VERSION ""

NS_ :

BS_:

BU_: L_3HKBD L_FHPTC L_2HKBD L_ATCU L_PCM L_EVNT L_HKBD L_RHPTC

BO_ 68 L_HKBD_04: 8 L_HKBD
 SG_ HKBD_Fr_DrTempDnSw : 0|1@1+ (1,0) [0|0] ""  L_ATCU
 SG_ HKBD_Fr_DrTempUpSw : 1|1@1+ (1,0) [0|0] ""  L_ATCU
 SG_ HKBD_Fr_PsBlwDnSw : 11|1@1+ (1,0) [0|0] ""  L_ATCU
 SG_ HKBD_Fr_PsBlwDnOffSw : 12|1@1+ (1,0) [0|0] ""  L_ATCU
 SG_ HKBD_Fr_PsBlwUpSw : 13|1@1+ (1,0) [0|0] ""  L_ATCU
 SG_ HKBD_Fr_PsBlwSet : 14|4@1+ (1,0) [0|0] ""  L_ATCU
 SG_ HKBD_Fr_RrDrTempDnSw : 18|1@1+ (1,0) [0|0] ""  L_ATCU
 SG_ HKBD_Fr_RrDrTempUpSw : 19|1@1+ (1,0) [0|0] ""  L_ATCU
 SG_ HKBD_Fr_PsTempDnSw : 2|1@1+ (1,0) [0|0] ""  L_ATCU
 SG_ HKBD_Fr_RrDrBlwDnSw : 20|1@1+ (1,0) [0|0] ""  L_ATCU
 SG_ HKBD_Fr_RrDrBlwDnOffSw : 21|1@1+ (1,0) [0|0] ""  L_ATCU
 SG_ HKBD_Fr_RrDrBlwUpSw : 22|1@1+ (1,0) [0|0] ""  L_ATCU
 SG_ HKBD_Fr_RrDrBlwSet : 23|4@1+ (1,0) [0|0] ""  L_ATCU
 SG_ HKBD_Fr_RrDrModDnSw : 27|1@1+ (1,0) [0|0] ""  L_ATCU
 SG_ HKBD_Fr_RrDrModUpSw : 28|1@1+ (1,0) [0|0] ""  L_ATCU
 SG_ HKBD_Fr_RrDrModVntSw : 29|1@1+ (1,0) [0|0] ""  L_ATCU
 SG_ HKBD_Fr_PsTempUpSw : 3|1@1+ (1,0) [0|0] ""  L_ATCU
 SG_ HKBD_Fr_RrDrModFlrSw : 30|1@1+ (1,0) [0|0] ""  L_ATCU
 SG_ HKBD_Fr_RrDrModBiLvlSw : 31|1@1+ (1,0) [0|0] ""  L_ATCU
 SG_ HKBD_Fr_RrDrAutoSw : 32|1@1+ (1,0) [0|0] ""  L_ATCU
 SG_ HKBD_Fr_RrDrMultiAutoSw : 33|3@1+ (1,0) [0|0] ""  L_ATCU
 SG_ HKBD_Fr_RrOffSw : 36|1@1+ (1,0) [0|0] ""  L_ATCU
 SG_ HKBD_Fr_RrSyncSw : 37|1@1+ (1,0) [0|0] ""  L_ATCU
 SG_ HKBD_Fr_RLStHeatSw : 38|1@1+ (1,0) [0|0] ""  L_ATCU
 SG_ HKBD_Fr_RLStVentSw : 39|1@1+ (1,0) [0|0] ""  L_ATCU
 SG_ HKBD_Fr_DrBlwDnSw : 4|1@1+ (1,0) [0|0] ""  L_ATCU
 SG_ HKBD_Fr_RRStHeatSw : 40|1@1+ (1,0) [0|0] ""  L_ATCU
 SG_ HKBD_Fr_RRStVentSw : 41|1@1+ (1,0) [0|0] ""  L_ATCU
 SG_ HKBD_Fr_RLStTumblrSw : 42|2@1+ (1,0) [0|0] ""  L_ATCU
 SG_ HKBD_Fr_RRStTumblrSw : 44|2@1+ (1,0) [0|0] ""  L_ATCU
 SG_ HKBD_Fr_RrPsModDnSw : 46|1@1+ (1,0) [0|0] ""  L_ATCU
 SG_ HKBD_Fr_RrPsModUpSw : 47|1@1+ (1,0) [0|0] ""  L_ATCU
 SG_ HKBD_Fr_RrPsModVntSw : 48|1@1+ (1,0) [0|0] ""  L_ATCU
 SG_ HKBD_Fr_RrPsModFlrSw : 49|1@1+ (1,0) [0|0] ""  L_ATCU
 SG_ HKBD_Fr_DrBlwDnOffSw : 5|1@1+ (1,0) [0|0] ""  L_ATCU
 SG_ HKBD_Fr_RrLockSw : 50|1@1+ (1,0) [0|0] ""  L_ATCU
 SG_ HKBD_Fr_RrPsModBiLvlSw : 51|1@1+ (1,0) [0|0] ""  L_ATCU
 SG_ HKBD_Fr_RrDrModSw : 52|1@1+ (1,0) [0|0] ""  L_ATCU
 SG_ HKBD_Fr_RrPsModSw : 53|1@1+ (1,0) [0|0] ""  L_ATCU
 SG_ HKBD_Fr_RrPsBlwSet : 54|4@1+ (1,0) [0|0] ""  L_ATCU
 SG_ HKBD_Fr_RrPsBlwUpSw : 58|1@1+ (1,0) [0|0] ""  L_ATCU
 SG_ HKBD_Fr_RrPsBlwDnSw : 59|1@1+ (1,0) [0|0] ""  L_ATCU
 SG_ HKBD_Fr_DrBlwUpSw : 6|1@1+ (1,0) [0|0] ""  L_ATCU
 SG_ HKBD_Fr_RrPsBlwDnOffSw : 60|1@1+ (1,0) [0|0] ""  L_ATCU
 SG_ HKBD_Fr_RrPsTempDnSw : 61|1@1+ (1,0) [0|0] ""  L_ATCU
 SG_ HKBD_Fr_RrPsTempUpSw : 62|1@1+ (1,0) [0|0] ""  L_ATCU
 SG_ HKBD_Fr_DrBlwSet : 7|4@1+ (1,0) [0|0] ""  L_ATCU

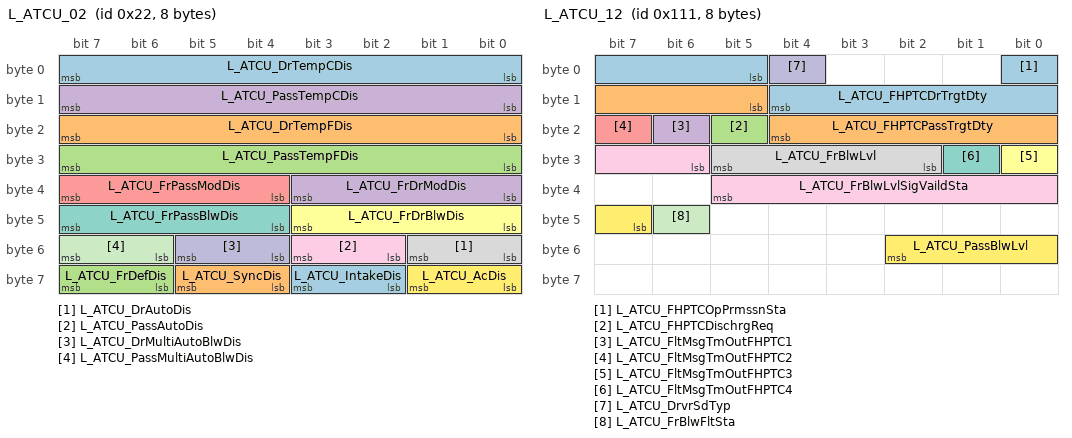
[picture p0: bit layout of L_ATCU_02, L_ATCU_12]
BO_ 34 L_ATCU_02: 8 L_ATCU
 SG_ L_ATCU_DrTempCDis : 0|8@1+ (0.5,14) [0|0] "¡É"  L_HKBD
 SG_ L_ATCU_DrTempFDis : 16|8@1+ (1,56) [0|0] "¢µ"  L_HKBD
 SG_ L_ATCU_PassTempFDis : 24|8@1+ (1,56) [0|0] "¢µ"  L_HKBD
 SG_ L_ATCU_FrDrModDis : 32|4@1+ (1,0) [0|0] ""  L_EVNT,L_HKBD
 SG_ L_ATCU_FrPassModDis : 36|4@1+ (1,0) [0|0] ""  L_EVNT,L_HKBD
 SG_ L_ATCU_FrDrBlwDis : 40|4@1+ (1,0) [0|0] ""  L_HKBD
 SG_ L_ATCU_FrPassBlwDis : 44|4@1+ (1,0) [0|0] ""  L_HKBD
 SG_ L_ATCU_DrAutoDis : 48|2@1+ (1,0) [0|0] ""  L_HKBD
 SG_ L_ATCU_PassAutoDis : 50|2@1+ (1,0) [0|0] ""  L_HKBD
 SG_ L_ATCU_DrMultiAutoBlwDis : 52|2@1+ (1,0) [0|0] ""  L_HKBD
 SG_ L_ATCU_PassMultiAutoBlwDis : 54|2@1+ (1,0) [0|0] ""  L_HKBD
 SG_ L_ATCU_AcDis : 56|2@1+ (1,0) [0|0] ""  L_HKBD
 SG_ L_ATCU_IntakeDis : 58|2@1+ (1,0) [0|0] ""  L_HKBD
 SG_ L_ATCU_SyncDis : 60|2@1+ (1,0) [0|0] ""  L_HKBD
 SG_ L_ATCU_FrDefDis : 62|2@1+ (1,0) [0|0] ""  L_HKBD
 SG_ L_ATCU_PassTempCDis : 8|8@1+ (0.5,14) [0|0] "¡É"  L_HKBD

BO_ 69 L_HKBD_05: 8 L_HKBD
 SG_ HKBD_Fr_3rdRrTempDnSw : 0|1@1+ (1,0) [0|0] ""  L_ATCU
 SG_ HKBD_Fr_3rdRrTempUpSw : 1|1@1+ (1,0) [0|0] ""  L_ATCU
 SG_ HKBD_Fr_3rdRrModUpSw : 10|1@1+ (1,0) [0|0] ""  L_ATCU
 SG_ HKBD_Fr_3rdRrModVntSw : 11|1@1+ (1,0) [0|0] ""  L_ATCU
 SG_ HKBD_Fr_3rdRrModFlrSw : 12|1@1+ (1,0) [0|0] ""  L_ATCU
 SG_ HKBD_Fr_3rdRrAutoSw : 13|1@1+ (1,0) [0|0] ""  L_ATCU
 SG_ HKBD_Fr_3rdRrMultiAutoSw : 14|3@1+ (1,0) [0|0] ""  L_ATCU
 SG_ HKBD_Fr_3rdRrOffSw : 17|1@1+ (1,0) [0|0] ""  L_ATCU
 SG_ HKBD_Fr_3rdRrSyncSw : 18|1@1+ (1,0) [0|0] ""  L_ATCU
 SG_ HKBD_Fr_3rdRrLockSw : 19|1@1+ (1,0) [0|0] ""  L_ATCU
 SG_ HKBD_Fr_3rdRrBlwDnSw : 2|1@1+ (1,0) [0|0] ""  L_ATCU
 SG_ HKBD_Fr_3rdRrModBiLvlSw : 20|1@1+ (1,0) [0|0] ""  L_ATCU
 SG_ HKBD_FrRrTglSet : 21|2@1+ (1,0) [0|0] ""  L_ATCU
 SG_ HKBD_Fr_RrScrnSet : 23|2@1+ (1,0) [0|0] ""  L_ATCU
 SG_ HKBD_Fr_OnOffSet : 25|2@1+ (1,0) [0|0] ""  L_ATCU
 SG_ HKBD_Fr_RrOnOffSet : 27|2@1+ (1,0) [0|0] ""  L_ATCU
 SG_ HKBD_Fr_3rdRrOnOffSet : 29|2@1+ (1,0) [0|0] ""  L_ATCU
 SG_ HKBD_Fr_3rdRrBlwDnOffSw : 3|1@1+ (1,0) [0|0] ""  L_ATCU
 SG_ HKBD_Fr_RrPsAutoSw : 31|1@1+ (1,0) [0|0] ""  L_ATCU
 SG_ HKBD_Fr_RrPsMultiAutoSw : 32|3@1+ (1,0) [0|0] ""  L_ATCU
 SG_ HKBD_Fr_3rdRrModSw : 35|1@1+ (1,0) [0|0] ""  L_ATCU
 SG_ HKBD_Fr_3rdRrBlwUpSw : 4|1@1+ (1,0) [0|0] ""  L_ATCU
 SG_ HKBD_Fr_3rdRrBlwSet : 5|4@1+ (1,0) [0|0] ""  L_ATCU
 SG_ HKBD_Fr_3rdRrModDnSw : 9|1@1+ (1,0) [0|0] ""  L_ATCU

BO_ 35 L_ATCU_03: 8 L_ATCU
 SG_ L_ATCU_DrOnlyDis : 0|2@1+ (1,0) [0|0] ""  L_HKBD
 SG_ L_ATCU_SmrtVntDis : 11|2@1+ (1,0) [0|0] ""  L_HKBD
 SG_ L_ATCU_FrWndShldHtInd : 13|2@1+ (1,0) [0|0] ""  L_HKBD
 SG_ L_ATCU_IncarMtrOnReq : 15|1@1+ (1,0) [0|0] ""  L_HKBD
 SG_ L_ATCU_LanguageInfo : 16|8@1+ (1,0) [0|0] ""  L_HKBD
 SG_ L_ATCU_RrDefInd : 2|1@1+ (1,0) [0|0] ""  L_HKBD
 SG_ L_ATCU_AfterBlowDisplay : 24|2@1+ (1,0) [0|0] ""  L_HKBD
 SG_ L_ATCU_SchdldVentDisplay : 26|2@1+ (1,0) [0|0] ""  L_HKBD
 SG_ L_ATCU_FLStHeatSwHInd : 28|1@1+ (1,0) [0|0] ""  L_HKBD
 SG_ L_ATCU_FLStHeatSwMInd : 29|1@1+ (1,0) [0|0] ""  L_HKBD
 SG_ L_ATCU_ADSBlinkDis : 3|2@1+ (1,0) [0|0] ""  L_HKBD
 SG_ L_ATCU_FLStHeatSwLInd : 30|1@1+ (1,0) [0|0] ""  L_HKBD
 SG_ L_ATCU_FLStVntSwHInd : 31|1@1+ (1,0) [0|0] ""  L_HKBD
 SG_ L_ATCU_FLStVntSwMInd : 32|1@1+ (1,0) [0|0] ""  L_HKBD
 SG_ L_ATCU_FLStVntSwLInd : 33|1@1+ (1,0) [0|0] ""  L_HKBD
 SG_ L_ATCU_FRStHeatSwHInd : 34|1@1+ (1,0) [0|0] ""  L_HKBD
 SG_ L_ATCU_FRStHeatSwMInd : 35|1@1+ (1,0) [0|0] ""  L_HKBD
 SG_ L_ATCU_FRStHeatSwLInd : 36|1@1+ (1,0) [0|0] ""  L_HKBD
 SG_ L_ATCU_FRStVntSwHInd : 37|1@1+ (1,0) [0|0] ""  L_HKBD
 SG_ L_ATCU_FRStVntSwMInd : 38|1@1+ (1,0) [0|0] ""  L_HKBD
 SG_ L_ATCU_FRStVntSwLInd : 39|1@1+ (1,0) [0|0] ""  L_HKBD
 SG_ L_ATCU_StrWhlHeatInd : 40|2@1+ (1,0) [0|0] ""  L_HKBD
 SG_ L_ATCU_RhstaLvlSta : 42|5@1+ (1,0) [0|0] ""  L_2HKBD,L_EVNT,L_HKBD
 SG_ L_ATCU_IntTailOnOff : 47|1@1+ (1,0) [0|0] ""  L_2HKBD,L_HKBD
 SG_ L_ATCU_AutoLightSta : 48|1@1+ (1,0) [0|0] ""  L_HKBD
 SG_ L_ATCU_FrBckLightSta : 49|1@1+ (1,0) [0|0] ""  L_HKBD
 SG_ L_ATCU_DisplayTheme : 50|2@1+ (1,0) [0|0] ""  L_HKBD
 SG_ L_ATCU_GUIBlankDis : 52|1@1+ (1,0) [0|0] ""  L_HKBD
 SG_ L_ATCU_HptIntnstySet : 53|4@1+ (1,0) [0|0] ""  L_HKBD
 SG_ L_ATCU_TlltLmpDis : 57|3@1+ (1,0) [0|0] ""  L_HKBD
 SG_ L_ATCU_AvTailOnOff : 60|1@1+ (1,0) [0|0] ""  L_HKBD
 SG_ L_ATCU_SchdldClimateDisplay : 61|2@1+ (1,0) [0|0] ""  L_HKBD
 SG_ L_ATCU_AirClnDis : 7|2@1+ (1,0) [0|0] ""  L_HKBD
 SG_ L_ATCU_CO2WrngDis : 9|2@1+ (1,0) [0|0] ""  L_HKBD

BO_ 70 L_HKBD_06: 8 L_HKBD
 SG_ HKBD_SwBtnTyp : 0|40@1+ (1,0) [0|0] ""  L_ATCU
 SG_ L_HKBD_ResetOpSta : 62|2@1+ (1,0) [0|0] ""  L_ATCU

BO_ 273 L_ATCU_12: 8 L_ATCU
 SG_ L_ATCU_FHPTCOpPrmssnSta : 0|1@1+ (1,0) [0|0] ""  L_FHPTC,L_RHPTC
 SG_ L_ATCU_FHPTCPassTrgtDty : 13|8@1+ (0.5,0) [0|0] "%"  L_FHPTC,L_RHPTC
 SG_ L_ATCU_FHPTCDischrgReq : 21|1@1+ (1,0) [0|0] ""  L_FHPTC,L_RHPTC
 SG_ L_ATCU_FltMsgTmOutFHPTC1 : 22|1@1+ (1,0) [0|0] ""  L_FHPTC,L_RHPTC
 SG_ L_ATCU_FltMsgTmOutFHPTC2 : 23|1@1+ (1,0) [0|0] ""  L_FHPTC,L_RHPTC
 SG_ L_ATCU_FltMsgTmOutFHPTC3 : 24|1@1+ (1,0) [0|0] ""  L_FHPTC,L_RHPTC
 SG_ L_ATCU_FltMsgTmOutFHPTC4 : 25|1@1+ (1,0) [0|0] ""  L_FHPTC,L_RHPTC
 SG_ L_ATCU_FrBlwLvl : 26|4@1+ (1,0) [0|0] ""  L_EVNT,L_FHPTC,L_RHPTC
 SG_ L_ATCU_FrBlwLvlSigVaildSta : 30|8@1+ (1,0) [0|0] ""  L_FHPTC,L_RHPTC
 SG_ L_ATCU_DrvrSdTyp : 4|1@1+ (1,0) [0|0] ""  L_EVNT,L_FHPTC,L_HKBD,L_RHPTC
 SG_ L_ATCU_FrBlwFltSta : 46|1@1+ (1,0) [0|0] ""  L_FHPTC,L_RHPTC
 SG_ L_ATCU_PassBlwLvl : 47|4@1+ (1,0) [0|0] ""  L_EVNT,L_FHPTC,L_RHPTC
 SG_ L_ATCU_FHPTCDrTrgtDty : 5|8@1+ (0.5,0) [0|0] "%"  L_FHPTC,L_RHPTC

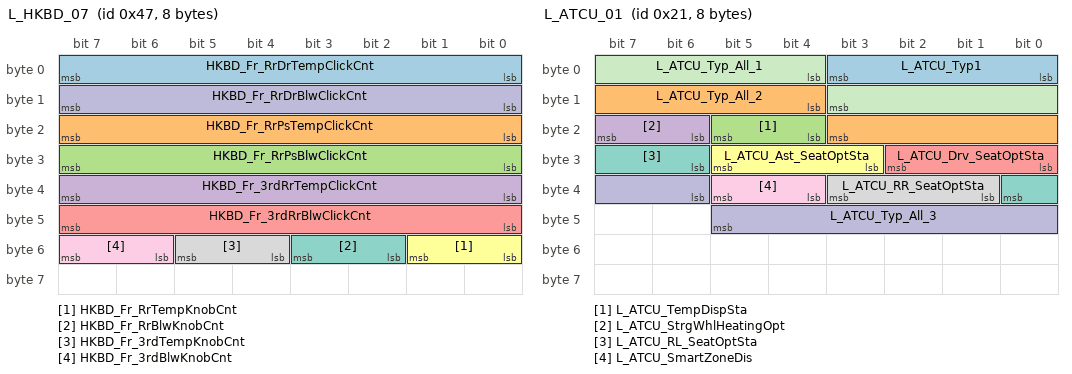
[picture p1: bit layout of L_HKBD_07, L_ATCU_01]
BO_ 71 L_HKBD_07: 8 L_HKBD
 SG_ HKBD_Fr_RrDrTempClickCnt : 0|8@1+ (1,0) [0|0] ""  L_ATCU
 SG_ HKBD_Fr_RrPsTempClickCnt : 16|8@1+ (1,0) [0|0] ""  L_ATCU
 SG_ HKBD_Fr_RrPsBlwClickCnt : 24|8@1+ (1,0) [0|0] ""  L_ATCU
 SG_ HKBD_Fr_3rdRrTempClickCnt : 32|8@1+ (1,0) [0|0] ""  L_ATCU
 SG_ HKBD_Fr_3rdRrBlwClickCnt : 40|8@1+ (1,0) [0|0] ""  L_ATCU
 SG_ HKBD_Fr_RrTempKnobCnt : 48|2@1+ (1,0) [0|0] ""  L_ATCU
 SG_ HKBD_Fr_RrBlwKnobCnt : 50|2@1+ (1,0) [0|0] ""  L_ATCU
 SG_ HKBD_Fr_3rdTempKnobCnt : 52|2@1+ (1,0) [0|0] ""  L_ATCU
 SG_ HKBD_Fr_3rdBlwKnobCnt : 54|2@1+ (1,0) [0|0] ""  L_ATCU
 SG_ HKBD_Fr_RrDrBlwClickCnt : 8|8@1+ (1,0) [0|0] ""  L_ATCU

BO_ 33 L_ATCU_01: 8 L_ATCU
 SG_ L_ATCU_Typ1 : 0|4@1+ (1,0) [0|0] ""  L_HKBD
 SG_ L_ATCU_Typ_All_2 : 12|8@1+ (1,0) [0|0] ""  L_2HKBD,L_3HKBD,L_HKBD
 SG_ L_ATCU_TempDispSta : 20|2@1+ (1,0) [0|0] ""  L_2HKBD,L_3HKBD,L_HKBD
 SG_ L_ATCU_StrgWhlHeatingOpt : 22|2@1+ (1,0) [0|0] ""  L_2HKBD,L_3HKBD,L_HKBD
 SG_ L_ATCU_Drv_SeatOptSta : 24|3@1+ (1,0) [0|0] ""  L_2HKBD,L_3HKBD,L_HKBD
 SG_ L_ATCU_Ast_SeatOptSta : 27|3@1+ (1,0) [0|0] ""  L_2HKBD,L_3HKBD,L_HKBD
 SG_ L_ATCU_RL_SeatOptSta : 30|3@1+ (1,0) [0|0] ""  L_2HKBD,L_3HKBD,L_HKBD
 SG_ L_ATCU_RR_SeatOptSta : 33|3@1+ (1,0) [0|0] ""  L_2HKBD,L_3HKBD,L_HKBD
 SG_ L_ATCU_SmartZoneDis : 36|2@1+ (1,0) [0|0] ""  L_HKBD
 SG_ L_ATCU_Typ_All_3 : 38|8@1+ (1,0) [0|0] ""  L_2HKBD,L_3HKBD,L_HKBD
 SG_ L_ATCU_Typ_All_1 : 4|8@1+ (1,0) [0|0] ""  L_2HKBD,L_3HKBD,L_HKBD

BO_ 38 L_ATCU_06: 8 L_ATCU
 SG_ L_ATCU_3rdRrTempCDis : 0|8@1+ (0.5,14) [0|0] "¡É"  L_3HKBD,L_HKBD
 SG_ L_ATCU_3rdRrModDis : 16|4@1+ (1,0) [0|0] ""  L_3HKBD,L_HKBD
 SG_ L_ATCU_3rdRrBlwDis : 20|4@1+ (1,0) [0|0] ""  L_3HKBD,L_HKBD
 SG_ L_ATCU_3rdRrAutoDis : 24|2@1+ (1,0) [0|0] ""  L_3HKBD,L_HKBD
 SG_ L_ATCU_3rdRrMultiAutoBlwDis : 26|3@1+ (1,0) [0|0] ""  L_3HKBD,L_HKBD
 SG_ L_ATCU_3rdRrSyncDis : 29|2@1+ (1,0) [0|0] ""  L_3HKBD,L_HKBD
 SG_ L_ATCU_3rdRrOnInd : 31|2@1+ (1,0) [0|0] ""  L_3HKBD,L_HKBD
 SG_ L_ATCU_3rdRrLockDis : 33|2@1+ (1,0) [0|0] ""  L_3HKBD,L_HKBD
 SG_ L_ATCU_3rdRrLcdBckLightSta : 35|1@1+ (1,0) [0|0] ""  L_3HKBD,L_HKBD
 SG_ L_ATCU_3rdRrGUIBlankDis : 36|1@1+ (1,0) [0|0] ""  L_3HKBD,L_HKBD
 SG_ L_ATCU_3rdRLStHeatSwHInd : 37|1@1+ (1,0) [0|0] ""  L_3HKBD,L_HKBD
 SG_ L_ATCU_3rdRLStHeatSwMInd : 38|1@1+ (1,0) [0|0] ""  L_3HKBD,L_HKBD
 SG_ L_ATCU_3rdRLStHeatSwLInd : 39|1@1+ (1,0) [0|0] ""  L_3HKBD,L_HKBD
 SG_ L_ATCU_3rdRLStVntSwHInd : 40|1@1+ (1,0) [0|0] ""  L_3HKBD,L_HKBD
 SG_ L_ATCU_3rdRLStVntSwMInd : 41|1@1+ (1,0) [0|0] ""  L_3HKBD,L_HKBD
 SG_ L_ATCU_3rdRLStVntSwLInd : 42|1@1+ (1,0) [0|0] ""  L_3HKBD,L_HKBD
 SG_ L_ATCU_3rdRRStHeatSwHInd : 43|1@1+ (1,0) [0|0] ""  L_3HKBD,L_HKBD
 SG_ L_ATCU_3rdRRStHeatSwMInd : 44|1@1+ (1,0) [0|0] ""  L_3HKBD,L_HKBD
 SG_ L_ATCU_3rdRRStHeatSwLInd : 45|1@1+ (1,0) [0|0] ""  L_3HKBD,L_HKBD
 SG_ L_ATCU_3rdRRStVntSwHInd : 46|1@1+ (1,0) [0|0] ""  L_3HKBD,L_HKBD
 SG_ L_ATCU_3rdRRStVntSwMInd : 47|1@1+ (1,0) [0|0] ""  L_3HKBD,L_HKBD
 SG_ L_ATCU_3rdRRStVntSwLInd : 48|1@1+ (1,0) [0|0] ""  L_3HKBD,L_HKBD
 SG_ L_ATCU_3rdRrMTCOpSta : 49|2@1+ (1,0) [0|0] ""  L_3HKBD,L_HKBD
 SG_ L_ATCU_3rdRrMtcTempLvl : 51|4@1+ (1,0) [0|0] ""  L_3HKBD,L_HKBD
 SG_ L_ATCU_3rdAUTOStep : 55|3@1+ (1,0) [0|0] ""  L_3HKBD,L_HKBD
 SG_ L_ATCU_RrPassMultiAutoBlwDis : 58|3@1+ (1,0) [0|0] ""  L_2HKBD,L_HKBD
 SG_ L_ATCU_DisPnlState : 61|2@1+ (1,0) [0|0] ""  L_HKBD
 SG_ L_ATCU_3rdRrTempFDis : 8|8@1+ (1,56) [0|0] "¢µ"  L_3HKBD,L_HKBD

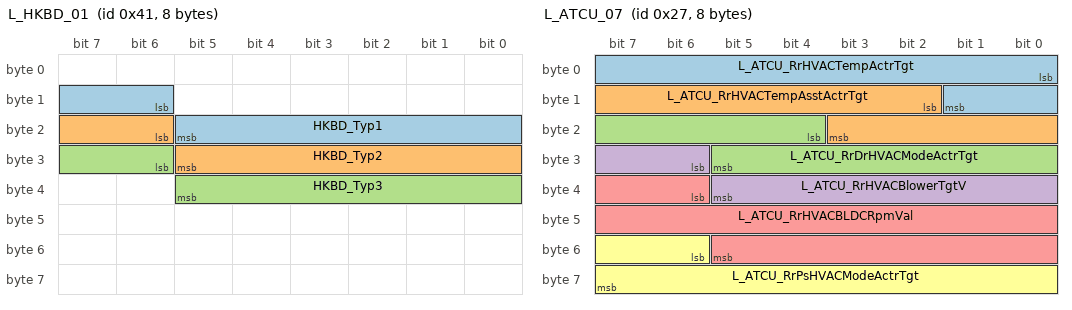
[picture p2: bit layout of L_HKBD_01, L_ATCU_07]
BO_ 65 L_HKBD_01: 8 L_HKBD
 SG_ HKBD_Typ1 : 14|8@1+ (1,0) [0|0] ""  L_ATCU
 SG_ HKBD_Typ2 : 22|8@1+ (1,0) [0|0] ""  L_ATCU
 SG_ HKBD_Typ3 : 30|8@1+ (1,0) [0|0] ""  L_ATCU

BO_ 39 L_ATCU_07: 8 L_ATCU
 SG_ L_ATCU_RrHVACTempActrTgt : 0|10@1+ (1,0) [0|0] "AD"  L_2HKBD,L_3HKBD,L_HKBD
 SG_ L_ATCU_RrHVACTempAsstActrTgt : 10|10@1+ (1,0) [0|0] "AD"  L_2HKBD,L_3HKBD,L_HKBD
 SG_ L_ATCU_RrDrHVACModeActrTgt : 20|10@1+ (1,0) [0|0] ""  L_2HKBD,L_3HKBD,L_HKBD
 SG_ L_ATCU_RrHVACBlowerTgtV : 30|8@1+ (0.1,0) [0|0] "V"  L_2HKBD,L_3HKBD,L_HKBD
 SG_ L_ATCU_RrHVACBLDCRpmVal : 38|16@1+ (1,0) [0|0] "rpm"  L_2HKBD,L_3HKBD,L_HKBD
 SG_ L_ATCU_RrPsHVACModeActrTgt : 54|10@1+ (1,0) [0|0] ""  L_2HKBD,L_3HKBD,L_HKBD

BO_ 66 L_HKBD_02: 8 L_HKBD
 SG_ HKBD_Fr_DrModDnSw : 0|1@1+ (1,0) [0|0] ""  L_ATCU
 SG_ HKBD_Fr_DrModUpSw : 1|1@1+ (1,0) [0|0] ""  L_ATCU
 SG_ HKBD_Fr_DrMultiAutoSw : 10|3@1+ (1,0) [0|0] ""  L_ATCU
 SG_ HKBD_Fr_PsAutoSw : 13|1@1+ (1,0) [0|0] ""  L_ATCU
 SG_ HKBD_Fr_PsMultiAutoSw : 14|3@1+ (1,0) [0|0] ""  L_ATCU
 SG_ HKBD_Fr_AcSw : 17|1@1+ (1,0) [0|0] ""  L_ATCU
 SG_ HKBD_Fr_DefSw : 18|1@1+ (1,0) [0|0] ""  L_ATCU
 SG_ HKBD_Fr_RecSw : 19|1@1+ (1,0) [0|0] ""  L_ATCU
 SG_ HKBD_Fr_DrModVntSw : 2|1@1+ (1,0) [0|0] ""  L_ATCU
 SG_ HKBD_Fr_FreSw : 20|1@1+ (1,0) [0|0] ""  L_ATCU
 SG_ HKBD_Fr_IntakeTglSw : 21|1@1+ (1,0) [0|0] ""  L_ATCU
 SG_ HKBD_Fr_OffSw : 22|1@1+ (1,0) [0|0] ""  L_ATCU
 SG_ HKBD_Fr_SyncSw : 23|1@1+ (1,0) [0|0] ""  L_ATCU
 SG_ HKBD_Fr_RrDefInd : 24|1@1+ (1,0) [0|0] ""  L_ATCU
 SG_ HKBD_Fr_RrDefSw : 25|1@1+ (1,0) [0|0] ""  L_ATCU
 SG_ HKBD_Fr_ArclnSw : 26|1@1+ (1,0) [0|0] ""  L_ATCU
 SG_ HKBD_Fr_DrOnlySw : 27|1@1+ (1,0) [0|0] ""  L_ATCU
 SG_ HKBD_Fr_ClimateSw : 28|1@1+ (1,0) [0|0] ""  L_ATCU
 SG_ HKBD_Fr_PerfumeSw : 29|1@1+ (1,0) [0|0] ""  L_ATCU
 SG_ HKBD_Fr_DrModFlrSw : 3|1@1+ (1,0) [0|0] ""  L_ATCU
 SG_ HKBD_Fr_HptIntnstySta : 30|4@1+ (1,0) [0|0] ""  L_ATCU
 SG_ HKBD_Fr_StrWhlHeatSw : 34|1@1+ (1,0) [0|0] ""  L_ATCU
 SG_ HKBD_FLStHeatSw : 35|1@1+ (1,0) [0|0] ""  L_ATCU
 SG_ HKBD_FLStVentSw : 36|1@1+ (1,0) [0|0] ""  L_ATCU
 SG_ HKBD_FRStHeatSw : 37|1@1+ (1,0) [0|0] ""  L_ATCU
 SG_ HKBD_FRStVentSw : 38|1@1+ (1,0) [0|0] ""  L_ATCU
 SG_ HKBD_FLStTumblrSw : 39|2@1+ (1,0) [0|0] ""  L_ATCU
 SG_ HKBD_Fr_DrModDefSw : 4|1@1+ (1,0) [0|0] ""  L_ATCU
 SG_ HKBD_FRStTumblrSw : 41|2@1+ (1,0) [0|0] ""  L_ATCU
 SG_ HKBD_Fr_FrWndShldHtSw : 43|1@1+ (1,0) [0|0] ""  L_ATCU
 SG_ HKBD_Fr_DrAutoDnSw : 44|1@1+ (1,0) [0|0] ""  L_ATCU
 SG_ HKBD_Fr_DrAutoUpSw : 45|1@1+ (1,0) [0|0] ""  L_ATCU
 SG_ HKBD_Fr_DrModSw : 46|1@1+ (1,0) [0|0] ""  L_ATCU
 SG_ HKBD_Fr_PsModSw : 47|1@1+ (1,0) [0|0] ""  L_ATCU
 SG_ HKBD_DisplayTheme : 48|2@1+ (1,0) [0|0] ""  L_ATCU
 SG_ HKBD_Fr_PsModDnSw : 5|1@1+ (1,0) [0|0] ""  L_ATCU
 SG_ HKBD_Fr_SmartZoneSW : 50|1@1+ (1,0) [0|0] ""  L_ATCU
 SG_ HKBD_Fr_PsModUpSw : 6|1@1+ (1,0) [0|0] ""  L_ATCU
 SG_ HKBD_Fr_PsModVntSw : 7|1@1+ (1,0) [0|0] ""  L_ATCU
 SG_ HKBD_Fr_PsModFlrSw : 8|1@1+ (1,0) [0|0] ""  L_ATCU
 SG_ HKBD_Fr_DrAutoSw : 9|1@1+ (1,0) [0|0] ""  L_ATCU

BO_ 36 L_ATCU_04: 8 L_ATCU
 SG_ L_ATCU_ArClnIntroEvt : 0|1@1+ (1,0) [0|0] ""  L_HKBD
 SG_ L_ATCU_ArClnSmblClr : 1|4@1+ (1,0) [0|0] ""  L_HKBD
 SG_ L_ATCU_DustLevelDis : 19|3@1+ (1,0) [0|0] ""  L_HKBD
 SG_ L_ATCU_DustBarDisOff : 22|1@1+ (1,0) [0|0] ""  L_HKBD
 SG_ L_ATCU_DustSnrStepDis : 23|6@1+ (1,0) [0|0] ""  L_HKBD
 SG_ L_ATCU_FragStrhDis : 29|2@1+ (1,0) [0|0] ""  L_HKBD,L_PCM
 SG_ L_ATCU_FragKindDis : 31|3@1+ (1,0) [0|0] ""  L_HKBD,L_PCM
 SG_ L_ATCU_Frag1Inform : 34|4@1+ (1,0) [0|0] ""  L_HKBD,L_PCM
 SG_ L_ATCU_Frag2Inform : 38|4@1+ (1,0) [0|0] ""  L_HKBD,L_PCM
 SG_ L_ATCU_Frag1RemainDisp : 42|4@1+ (1,0) [0|0] ""  L_HKBD,L_PCM
 SG_ L_ATCU_Frag2RemainDisp : 46|4@1+ (1,0) [0|0] ""  L_2HKBD,L_HKBD
 SG_ L_ATCU_ArClnSmblTyp : 5|4@1+ (1,0) [0|0] ""  L_HKBD
 SG_ L_ATCU_FrtBlwMaxLvlVaild : 50|4@1+ (1,0) [0|0] ""  L_2HKBD,L_HKBD
 SG_ L_ATCU_OpSta : 54|3@1+ (1,0) [0|0] ""  L_EVNT,L_HKBD
 SG_ L_ATCU_TempDispUnit : 57|2@1+ (1,0) [0|0] ""  L_2HKBD,L_HKBD
 SG_ L_ATCU_DrvAUTOStep : 59|4@1+ (1,0) [0|0] ""  L_HKBD
 SG_ L_ATCU_DiagCodeDis : 9|10@1+ (1,-1) [0|0] ""  L_HKBD

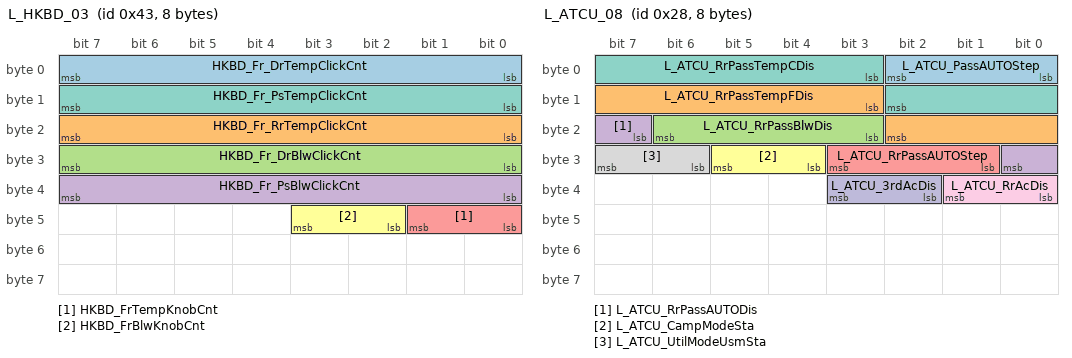
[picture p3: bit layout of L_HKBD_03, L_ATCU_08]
BO_ 67 L_HKBD_03: 8 L_HKBD
 SG_ HKBD_Fr_DrTempClickCnt : 0|8@1+ (1,0) [0|0] ""  L_ATCU
 SG_ HKBD_Fr_RrTempClickCnt : 16|8@1+ (1,0) [0|0] ""  L_ATCU
 SG_ HKBD_Fr_DrBlwClickCnt : 24|8@1+ (1,0) [0|0] ""  L_ATCU
 SG_ HKBD_Fr_PsBlwClickCnt : 32|8@1+ (1,0) [0|0] ""  L_ATCU
 SG_ HKBD_FrTempKnobCnt : 40|2@1+ (1,0) [0|0] ""  L_ATCU
 SG_ HKBD_FrBlwKnobCnt : 42|2@1+ (1,0) [0|0] ""  L_ATCU
 SG_ HKBD_Fr_PsTempClickCnt : 8|8@1+ (1,0) [0|0] ""  L_ATCU

BO_ 37 L_ATCU_05: 8 L_ATCU
 SG_ L_ATCU_RrOpSta : 0|3@1+ (1,0) [0|0] ""  L_2HKBD,L_HKBD
 SG_ L_ATCU_RrDrvTempFDis : 11|8@1+ (1,56) [0|0] "¢µ"  L_2HKBD,L_HKBD
 SG_ L_ATCU_RrDrvModDis : 19|4@1+ (1,0) [0|0] ""  L_2HKBD,L_EVNT,L_HKBD
 SG_ L_ATCU_RrDrvBlwDis : 23|4@1+ (1,0) [0|0] ""  L_2HKBD,L_HKBD
 SG_ L_ATCU_RrDrvAutoDis : 27|2@1+ (1,0) [0|0] ""  L_2HKBD,L_HKBD
 SG_ L_ATCU_RrDrvMultiAutoBlwDis : 29|2@1+ (1,0) [0|0] ""  L_2HKBD,L_HKBD
 SG_ L_ATCU_RrDrvTempCDis : 3|8@1+ (0.5,14) [0|0] "¡É"  L_2HKBD,L_HKBD
 SG_ L_ATCU_RrSyncDis : 31|2@1+ (1,0) [0|0] ""  L_2HKBD,L_HKBD
 SG_ L_ATCU_RrLcdBckLightSta : 33|1@1+ (1,0) [0|0] ""  L_2HKBD,L_HKBD
 SG_ L_ATCU_RrGUIBlankDis : 34|1@1+ (1,0) [0|0] ""  L_2HKBD,L_HKBD
 SG_ L_ATCU_RLStHeatSwHInd : 35|1@1+ (1,0) [0|0] ""  L_2HKBD,L_HKBD
 SG_ L_ATCU_RLStHeatSwMInd : 36|1@1+ (1,0) [0|0] ""  L_2HKBD,L_HKBD
 SG_ L_ATCU_RLStHeatSwLInd : 37|1@1+ (1,0) [0|0] ""  L_2HKBD,L_HKBD
 SG_ L_ATCU_RLStVntSwHInd : 38|1@1+ (1,0) [0|0] ""  L_2HKBD,L_HKBD
 SG_ L_ATCU_RLStVntSwMInd : 39|1@1+ (1,0) [0|0] ""  L_2HKBD,L_HKBD
 SG_ L_ATCU_RLStVntSwLInd : 40|1@1+ (1,0) [0|0] ""  L_2HKBD,L_HKBD
 SG_ L_ATCU_RRStHeatSwHInd : 41|1@1+ (1,0) [0|0] ""  L_2HKBD,L_HKBD
 SG_ L_ATCU_RRStHeatSwMInd : 42|1@1+ (1,0) [0|0] ""  L_2HKBD,L_HKBD
 SG_ L_ATCU_RRStHeatSwLInd : 43|1@1+ (1,0) [0|0] ""  L_2HKBD,L_HKBD
 SG_ L_ATCU_RRStVntSwHInd : 44|1@1+ (1,0) [0|0] ""  L_2HKBD,L_HKBD
 SG_ L_ATCU_RRStVntSwMInd : 45|1@1+ (1,0) [0|0] ""  L_2HKBD,L_HKBD
 SG_ L_ATCU_RRStVntSwLInd : 46|1@1+ (1,0) [0|0] ""  L_2HKBD,L_HKBD
 SG_ L_ATCU_RrMTCOpSta : 47|2@1+ (1,0) [0|0] ""  L_2HKBD,L_HKBD
 SG_ L_ATCU_RrMTCTempLvl : 49|4@1+ (1,0) [0|0] ""  L_2HKBD,L_HKBD
 SG_ L_ATCU_RrPsModDis : 53|4@1+ (1,0) [0|0] ""  L_2HKBD,L_EVNT,L_HKBD
 SG_ L_ATCU_RrLockDis : 57|2@1+ (1,0) [0|0] ""  L_2HKBD,L_HKBD
 SG_ L_ATCU_RrDrvAutoStep : 59|4@1+ (1,0) [0|0] ""  L_2HKBD,L_HKBD

BO_ 40 L_ATCU_08: 8 L_ATCU
 SG_ L_ATCU_PassAUTOStep : 0|3@1+ (1,0) [0|0] ""  L_2HKBD,L_HKBD
 SG_ L_ATCU_RrPassTempFDis : 11|8@1+ (1,56) [0|0] "¢µ"  L_2HKBD,L_HKBD
 SG_ L_ATCU_RrPassBlwDis : 19|4@1+ (1,0) [0|0] ""  L_2HKBD,L_HKBD
 SG_ L_ATCU_RrPassAUTODis : 23|2@1+ (1,0) [0|0] ""  L_2HKBD,L_HKBD
 SG_ L_ATCU_RrPassAUTOStep : 25|3@1+ (1,0) [0|0] ""  L_2HKBD,L_HKBD
 SG_ L_ATCU_CampModeSta : 28|2@1+ (1,0) [0|0] ""  L_2HKBD,L_3HKBD,L_EVNT,L_HKBD
 SG_ L_ATCU_RrPassTempCDis : 3|8@1+ (0.5,14) [0|0] "¡É"  L_2HKBD,L_HKBD
 SG_ L_ATCU_UtilModeUsmSta : 30|2@1+ (1,0) [0|0] ""  L_2HKBD,L_3HKBD,L_EVNT,L_HKBD
 SG_ L_ATCU_RrAcDis : 32|2@1+ (1,0) [0|0] ""  L_2HKBD,L_3HKBD,L_HKBD
 SG_ L_ATCU_3rdAcDis : 34|2@1+ (1,0) [0|0] ""  L_2HKBD,L_3HKBD,L_HKBD

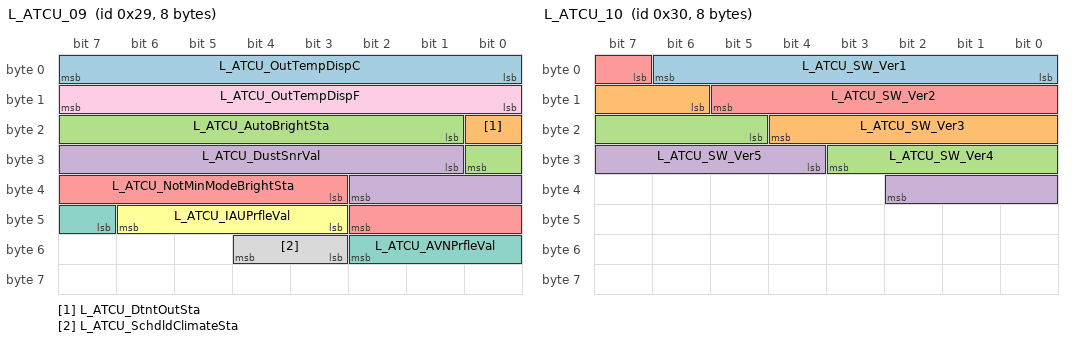
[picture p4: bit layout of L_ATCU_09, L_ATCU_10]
BO_ 41 L_ATCU_09: 8 L_ATCU
 SG_ L_ATCU_OutTempDispC : 0|8@1+ (0.5,-41) [0|0] "¡É"  L_FHPTC,L_HKBD,L_RHPTC
 SG_ L_ATCU_DtntOutSta : 16|1@1+ (1,0) [0|0] ""  L_2HKBD,L_EVNT,L_HKBD
 SG_ L_ATCU_AutoBrightSta : 17|8@1+ (1,0) [0|0] ""  L_2HKBD,L_EVNT,L_HKBD
 SG_ L_ATCU_DustSnrVal : 25|10@1+ (1,0) [0|0] "um/m3"  L_HKBD
 SG_ L_ATCU_NotMinModeBrightSta : 35|8@1+ (1,0) [0|0] ""  L_2HKBD,L_3HKBD,L_EVNT,L_HKBD
 SG_ L_ATCU_IAUPrfleVal : 43|4@1+ (1,0) [0|0] ""  L_EVNT
 SG_ L_ATCU_AVNPrfleVal : 47|4@1+ (1,0) [0|0] ""  L_EVNT
 SG_ L_ATCU_SchdldClimateSta : 51|2@1+ (1,0) [0|0] ""  L_EVNT
 SG_ L_ATCU_OutTempDispF : 8|8@1+ (1,-42) [0|0] "¢µ"  L_FHPTC,L_HKBD,L_RHPTC

BO_ 72 L_HKBD_08: 8 L_HKBD
 SG_ HKBD_Fr_IncarRaw : 0|10@1+ (0.01,0) [0|0] "V"  L_ATCU

BO_ 49 L_ATCU_11: 8 L_ATCU
 SG_ L_ATCU_ResetPreWrngForOthers : 0|2@1+ (1,0) [0|0] ""  L_2HKBD,L_3HKBD,L_EVNT,L_HKBD,L_PCM
 SG_ L_ATCU_ResetReqForOthers : 2|2@1+ (1,0) [0|0] ""  L_2HKBD,L_3HKBD,L_EVNT,L_HKBD,L_PCM

BO_ 48 L_ATCU_10: 8 L_ATCU
 SG_ L_ATCU_SW_Ver1 : 0|7@1+ (1,0) [0|0] ""  L_HKBD
 SG_ L_ATCU_SW_Ver3 : 14|7@1+ (1,0) [0|0] ""  L_HKBD
 SG_ L_ATCU_SW_Ver4 : 21|7@1+ (1,0) [0|0] ""  L_HKBD
 SG_ L_ATCU_SW_Ver5 : 28|7@1+ (1,0) [0|0] ""  L_HKBD
 SG_ L_ATCU_SW_Ver2 : 7|7@1+ (1,0) [0|0] ""  L_HKBD

CM_ BO_ 33 "[PE] Periodic and On Event";
CM_ SG_ 33 L_ATCU_Typ1 "ATCU_Type1";
CM_ SG_ 33 L_ATCU_Drv_SeatOptSta "ATCU_Drvier_SeatOptionStaus";
CM_ SG_ 33 L_ATCU_Ast_SeatOptSta "ATCU_Ast_SeatOptionStatus";
CM_ SG_ 33 L_ATCU_RL_SeatOptSta "ATCU_RearLeft_SeatOptionStatus";
CM_ SG_ 33 L_ATCU_RR_SeatOptSta "ATCU_RearRight_SeatOperationStatus";
CM_ SG_ 33 L_ATCU_SmartZoneDis "L_ATCU_SmartZoneDisplay";
CM_ BO_ 34 "[PE] Periodic and On Event";
CM_ SG_ 34 L_ATCU_DrTempCDis "ATCU_DrvierTemperatureDisplay(¡É)";
CM_ SG_ 34 L_ATCU_DrTempFDis "ATCU_DriverTemperatureDisplay(¢µ)";
CM_ SG_ 34 L_ATCU_PassTempFDis "ATCU_PassengerTemperatureDisplay(¢µ)";
CM_ SG_ 34 L_ATCU_FrDrModDis "ATCU_FrontDriverModeDisplay";
CM_ SG_ 34 L_ATCU_FrPassModDis "ATCU_FrontPassengerModeDisplay";
CM_ SG_ 34 L_ATCU_FrDrBlwDis "ATCU_FrontDriverBlowerDisplay";
CM_ SG_ 34 L_ATCU_FrPassBlwDis "ATCU_FrontPassengerBlowerDisplay";
CM_ SG_ 34 L_ATCU_DrAutoDis "ATCU_DriverAutoDisplay";
CM_ SG_ 34 L_ATCU_PassAutoDis "ATCU_PassengerAutoDisplay";
CM_ SG_ 34 L_ATCU_DrMultiAutoBlwDis "ATCU_DriverMultiAutoBlowerDisplay";
CM_ SG_ 34 L_ATCU_PassMultiAutoBlwDis "ATCU_PassengerMultiAutoBlowerDisplay";
CM_ SG_ 34 L_ATCU_AcDis "ATCU_AcDisplay";
CM_ SG_ 34 L_ATCU_IntakeDis "ATCU_IntakeDisplay";
CM_ SG_ 34 L_ATCU_SyncDis "ATCU_SyncDisplay";
CM_ SG_ 34 L_ATCU_FrDefDis "ATCU_FrontDefrostDisplay";
CM_ SG_ 34 L_ATCU_PassTempCDis "ATCU_PassengerTemperatureDisplay(¡É)";
CM_ BO_ 35 "[PE] Periodic and On Event";
CM_ SG_ 35 L_ATCU_DrOnlyDis "ATCU_DriverOnlyDisplay";
CM_ SG_ 35 L_ATCU_SmrtVntDis "ATCU_SmartVentilationDisplay";
CM_ SG_ 35 L_ATCU_FrWndShldHtInd "ATCU_FrontWindShieldHeaterIndicator";
CM_ SG_ 35 L_ATCU_IncarMtrOnReq "ATCU_IncarMotorOnRequest";
CM_ SG_ 35 L_ATCU_LanguageInfo "ATCU_LanguageInformation";
CM_ SG_ 35 L_ATCU_RrDefInd "ATCU_RearDEFIndicator";
CM_ SG_ 35 L_ATCU_AfterBlowDisplay "ATCU_AfterBlow Display";
CM_ SG_ 35 L_ATCU_SchdldVentDisplay "ATCU_SchduledVentDispaly";
CM_ SG_ 35 L_ATCU_FLStHeatSwHInd "ATCU_FrontLeftSeatHeatSwitchHighIndicator";
CM_ SG_ 35 L_ATCU_FLStHeatSwMInd "ATCU_FrontLeftSeatHeatSwitchMiddleIndicator";
CM_ SG_ 35 L_ATCU_ADSBlinkDis "ATCU_ADSBlinkDisplay";
CM_ SG_ 35 L_ATCU_FLStHeatSwLInd "ATCU_FrontLeftSeatHeatSwitchLowIndicator";
CM_ SG_ 35 L_ATCU_FLStVntSwHInd "ATCU_FrontLeftSeatVentilationSwitchHighIndicator";
CM_ SG_ 35 L_ATCU_FLStVntSwMInd "ATCU_FrontLeftSeatVentilationSwitchMiddleIndicator";
CM_ SG_ 35 L_ATCU_FLStVntSwLInd "ATCU_FrontLeftSeatVentilationSwitchLowIndicator";
CM_ SG_ 35 L_ATCU_FRStHeatSwHInd "ATCU_FrontRightSeatHeatSwitchHighIndicator";
CM_ SG_ 35 L_ATCU_FRStHeatSwMInd "ATCU_FrontRightSeatHeatSwitchMiddleIndicator";
CM_ SG_ 35 L_ATCU_FRStHeatSwLInd "ATCU_FrontRightSeatHeatSwitchLowIndicator";
CM_ SG_ 35 L_ATCU_FRStVntSwHInd "ATCU_FrontRightSeatVentilationSwitchHighIndicator";
CM_ SG_ 35 L_ATCU_FRStVntSwMInd "ATCU_FrontRightSeatVentilationSwitchMiddleIndicator";
CM_ SG_ 35 L_ATCU_FRStVntSwLInd "ATCU_FrontRightSeatVentilationSwitchLowIndicator";
CM_ SG_ 35 L_ATCU_StrWhlHeatInd "ATCU_SteeringWheelHeatIndicator";
CM_ SG_ 35 L_ATCU_RhstaLvlSta "ATCU_RheostatLevelStatus";
CM_ SG_ 35 L_ATCU_IntTailOnOff "ATCU_InternalTailOnOff";
CM_ SG_ 35 L_ATCU_AutoLightSta "ATCU_AutoLightStatus";
CM_ SG_ 35 L_ATCU_FrBckLightSta "ATCU_FrontBackLightStatus";
CM_ SG_ 35 L_ATCU_DisplayTheme "ATCU_DisplayTheme";
CM_ SG_ 35 L_ATCU_GUIBlankDis "ATCU_GUIBlankDisplay";
CM_ SG_ 35 L_ATCU_HptIntnstySet "ATCU_HapticIntensityLevelSet";
CM_ SG_ 35 L_ATCU_TlltLmpDis "ATCU_TelltaleLampDisplay";
CM_ SG_ 35 L_ATCU_AvTailOnOff "ATCU_AVTailOnOff";
CM_ SG_ 35 L_ATCU_SchdldClimateDisplay "ATCU_ScheduledClimateDisplay";
CM_ SG_ 35 L_ATCU_AirClnDis "ATCU_AirCleaningDisplay";
CM_ SG_ 35 L_ATCU_CO2WrngDis "ATCU_CO2WarningDisplay";
CM_ BO_ 36 "[PE] Periodic and On Event";
CM_ SG_ 36 L_ATCU_ArClnIntroEvt "ATCU_AirCleaningIntroEvent";
CM_ SG_ 36 L_ATCU_ArClnSmblClr "ATCU_AirCleaningSymbolColor";
CM_ SG_ 36 L_ATCU_DustLevelDis "ATCU_DustLevelDisplay";
CM_ SG_ 36 L_ATCU_DustBarDisOff "ATCU_DustBarDisplayOff";
CM_ SG_ 36 L_ATCU_DustSnrStepDis "ATCU_DustSensorStepDisplay";
CM_ SG_ 36 L_ATCU_FragStrhDis "ATCU_FragStrengthDisplay";
CM_ SG_ 36 L_ATCU_FragKindDis "ATCU_FragKindDisplay";
CM_ SG_ 36 L_ATCU_Frag1Inform "ATCU_Frag1Information";
CM_ SG_ 36 L_ATCU_Frag2Inform "ATCU_Frag2Information";
CM_ SG_ 36 L_ATCU_Frag1RemainDisp "ATCU_Frag1RemainDisplay";
CM_ SG_ 36 L_ATCU_Frag2RemainDisp "ATCU_Frag2RemainDisplay";
CM_ SG_ 36 L_ATCU_ArClnSmblTyp "ATCU_AircCleaningSymbolType";
CM_ SG_ 36 L_ATCU_FrtBlwMaxLvlVaild "ATCU_FrontBlowerMaxLevelVaild";
CM_ SG_ 36 L_ATCU_OpSta "ATCU_OperationStatus";
CM_ SG_ 36 L_ATCU_TempDispUnit "ATCU_TemperatureDisplayUnit";
CM_ SG_ 36 L_ATCU_DrvAUTOStep "ATCU_DriverAutoStep";
CM_ SG_ 36 L_ATCU_DiagCodeDis "ATCU_DiagCodeDisplay";
CM_ BO_ 37 "[PE] Periodic and On Event";
CM_ SG_ 37 L_ATCU_RrOpSta "ATCU_RearOperationStatus";
CM_ SG_ 37 L_ATCU_RrDrvTempFDis "ATCU_RearDriverTemperature¢µDisplay";
CM_ SG_ 37 L_ATCU_RrDrvModDis "ATCU_RearDriverModeDisplay";
CM_ SG_ 37 L_ATCU_RrDrvBlwDis "ATCU_RearDriverBlowerDisplay";
CM_ SG_ 37 L_ATCU_RrDrvAutoDis "ATCU_RearDriverAutoDisplay";
CM_ SG_ 37 L_ATCU_RrDrvMultiAutoBlwDis "ATCU_RearDriverMultiAutoBlowerDisplay";
CM_ SG_ 37 L_ATCU_RrDrvTempCDis "ATCU_RearDriverTemperature¡ÉDisplay";
CM_ SG_ 37 L_ATCU_RrSyncDis "ATCU_RearSyncDisplay";
CM_ SG_ 37 L_ATCU_RrLcdBckLightSta "ATCU_RearLCDBackLightStatus";
CM_ SG_ 37 L_ATCU_RrGUIBlankDis "ATCU_RearGUIBlankDisplay";
CM_ SG_ 37 L_ATCU_RLStHeatSwHInd "ATCU_RearLeftSeatHeatSwitchHighIndicator";
CM_ SG_ 37 L_ATCU_RLStHeatSwMInd "ATCU_RearLeftSeatHeatSwitchMiddleIndicator";
CM_ SG_ 37 L_ATCU_RLStHeatSwLInd "ATCU_RearLeftSeatHeatSwitchLowIndicator";
CM_ SG_ 37 L_ATCU_RLStVntSwHInd "ATCU_RearLeftSeatVentilationSwitchHighIndicator";
CM_ SG_ 37 L_ATCU_RLStVntSwMInd "ATCU_RearLeftSeatVentilationSwitchMiddleIndicator";
CM_ SG_ 37 L_ATCU_RLStVntSwLInd "ATCU_RearLeftSeatVentilationSwitchLowIndicator";
CM_ SG_ 37 L_ATCU_RRStHeatSwHInd "ATCU_RearRightSeatHeatSwitchHighIndicator";
CM_ SG_ 37 L_ATCU_RRStHeatSwMInd "ATCU_RearRightSeatHeatSwitchMiddleIndicator";
CM_ SG_ 37 L_ATCU_RRStHeatSwLInd "ATCU_RearRightSeatHeatSwitchLowIndicator";
CM_ SG_ 37 L_ATCU_RRStVntSwHInd "ATCU_RearRightSeatVentilationSwitchHighIndicator";
CM_ SG_ 37 L_ATCU_RRStVntSwMInd "ATCU_RearRightSeatVentilationSwitchMiddleIndicator";
CM_ SG_ 37 L_ATCU_RRStVntSwLInd "ATCU_RearRightSeatVentilationSwitchLowIndicator";
CM_ SG_ 37 L_ATCU_RrMTCOpSta "ATCU_RearMTCOperationStatus";
CM_ SG_ 37 L_ATCU_RrMTCTempLvl "ATCU_RearMTCTempLevel";
CM_ SG_ 37 L_ATCU_RrPsModDis "ATCU_RearPassengerModeDisplay";
CM_ SG_ 37 L_ATCU_RrLockDis "ATCU_RearLockDisplay";
CM_ SG_ 37 L_ATCU_RrDrvAutoStep "ATCU_RearDriverAutoStep";
CM_ BO_ 38 "[PE] Periodic and On Event";
CM_ SG_ 38 L_ATCU_3rdRrTempCDis "ATCU_3rdRearTemperature¡ÉDisplay";
CM_ SG_ 38 L_ATCU_3rdRrModDis "ATCU_3rdRearModeDisplay";
CM_ SG_ 38 L_ATCU_3rdRrBlwDis "ATCU_3rdRearBlowerDisplay";
CM_ SG_ 38 L_ATCU_3rdRrAutoDis "ATCU_3rdRearAutoDisplay";
CM_ SG_ 38 L_ATCU_3rdRrMultiAutoBlwDis "ATCU_3rdRearMultiAutoBlowerDisplay";
CM_ SG_ 38 L_ATCU_3rdRrSyncDis "ATCU_3rdRearSyncDisplay";
CM_ SG_ 38 L_ATCU_3rdRrOnInd "ATCU_3rdRearONIndicator";
CM_ SG_ 38 L_ATCU_3rdRrLockDis "ATCU_3rdRearLockDisplay";
CM_ SG_ 38 L_ATCU_3rdRrLcdBckLightSta "ATCU_3rdRearLCDBackLightStatus";
CM_ SG_ 38 L_ATCU_3rdRrGUIBlankDis "ATCU_3rdRearGUIBlankDisplay";
CM_ SG_ 38 L_ATCU_3rdRLStHeatSwHInd "ATCU_3rdRearLeftSeatHeatSwitchHighIndicator";
CM_ SG_ 38 L_ATCU_3rdRLStHeatSwMInd "ATCU_3rdRearLeftSeatHeatSwitchMiddleIndicator";
CM_ SG_ 38 L_ATCU_3rdRLStHeatSwLInd "ATCU_3rdRearLeftSeatHeatSwitchLowIndicator";
CM_ SG_ 38 L_ATCU_3rdRLStVntSwHInd "ATCU_3rdRearLeftSeatVentilationSwitchHighIndicator";
CM_ SG_ 38 L_ATCU_3rdRLStVntSwMInd "ATCU_3rdRearLeftSeatVentilationSwitchMiddleIndicator";
CM_ SG_ 38 L_ATCU_3rdRLStVntSwLInd "ATCU_3rdRearLeftSeatVentilationSwitchLowIndicator";
CM_ SG_ 38 L_ATCU_3rdRRStHeatSwHInd "ATCU_3rdRearRightSeatHeatSwitchHighIndicator";
CM_ SG_ 38 L_ATCU_3rdRRStHeatSwMInd "ATCU_3rdRearRightSeatHeatSwitchMiddleIndicator";
CM_ SG_ 38 L_ATCU_3rdRRStHeatSwLInd "ATCU_3rdRearRightSeatHeatSwitchLowIndicator";
CM_ SG_ 38 L_ATCU_3rdRRStVntSwHInd "ATCU_3rdRearRightSeatVentilationSwitchHighIndicator";
CM_ SG_ 38 L_ATCU_3rdRRStVntSwMInd "ATCU_3rdRearRightSeatVentilationSwitchMiddleIndicator";
CM_ SG_ 38 L_ATCU_3rdRRStVntSwLInd "ATCU_3rdRearRightSeatVentilationSwitchLowIndicator";
CM_ SG_ 38 L_ATCU_3rdRrMTCOpSta "ATCU_3rdRearMTCOperationStatus";
CM_ SG_ 38 L_ATCU_3rdRrMtcTempLvl "ATCU_3rdRearMTCTemperatureLevel";
CM_ SG_ 38 L_ATCU_3rdAUTOStep "ATCU_3rdAUTOStep";
CM_ SG_ 38 L_ATCU_RrPassMultiAutoBlwDis "ATCU_RrPassengerMultiAutoBlowerDisplay";
CM_ SG_ 38 L_ATCU_DisPnlState "ATCU_DisplayPanelState";
CM_ SG_ 38 L_ATCU_3rdRrTempFDis "ATCU_3rdRearTemperature¢µDisplay";
CM_ BO_ 39 "[P] Periodic";
CM_ SG_ 39 L_ATCU_RrHVACTempActrTgt "ATCU_RearHVACTemperatureActuatorTarget";
CM_ SG_ 39 L_ATCU_RrHVACTempAsstActrTgt "ATCU_RearHVCACTempAsstanceActuatorTarget";
CM_ SG_ 39 L_ATCU_RrDrHVACModeActrTgt "ATCU_RearDriverHVACModeActuatorTarget";
CM_ SG_ 39 L_ATCU_RrHVACBlowerTgtV "ATCU_RearHVACBlowerTargetVoltage";
CM_ SG_ 39 L_ATCU_RrHVACBLDCRpmVal "ATCU_RearHVAC BLDC Motor RPM Value";
CM_ SG_ 39 L_ATCU_RrPsHVACModeActrTgt "ATCU_RearPassengerHVACModeActuatorTarget";
CM_ BO_ 40 "[PE] Periodic and On Event";
CM_ SG_ 40 L_ATCU_PassAUTOStep "ATCU_PassAUTOStep";
CM_ SG_ 40 L_ATCU_RrPassTempFDis "ATCU_RrPassTempFDisplay";
CM_ SG_ 40 L_ATCU_RrPassBlwDis "ATCU_RrPassBlwDis";
CM_ SG_ 40 L_ATCU_RrPassAUTODis "ATCU_RrPassAUTODis";
CM_ SG_ 40 L_ATCU_RrPassAUTOStep "ATCU_RrPassAUTOStep";
CM_ SG_ 40 L_ATCU_CampModeSta "ATCU_CampModeStatus";
CM_ SG_ 40 L_ATCU_RrPassTempCDis "ATCU_RrPassTempCDisplay";
CM_ SG_ 40 L_ATCU_UtilModeUsmSta "ATCU_UtilityModeUSMStatus";
CM_ SG_ 40 L_ATCU_RrAcDis "ATCU_RrAcDisplay";
CM_ SG_ 40 L_ATCU_3rdAcDis "L_ATCU_3rdAcDisplay";
CM_ BO_ 41 "[P] Periodic";
CM_ SG_ 41 L_ATCU_OutTempDispC "ATCU_OutTemperatureDisplay(¡É)";
CM_ SG_ 41 L_ATCU_DtntOutSta "ATCU_DetentOutStatus";
CM_ SG_ 41 L_ATCU_AutoBrightSta "ATCU_AutoBrightStatus";
CM_ SG_ 41 L_ATCU_DustSnrVal "ATCU_DustSensorValue";
CM_ SG_ 41 L_ATCU_NotMinModeBrightSta "ATCU_NotMinimumModeBrightStatus";
CM_ SG_ 41 L_ATCU_IAUPrfleVal "L_ATCU_IAUProfileValue";
CM_ SG_ 41 L_ATCU_AVNPrfleVal "L_ATCU_AVNProfileValue";
CM_ SG_ 41 L_ATCU_SchdldClimateSta "Operation of the air conditioning system, controlled by the remote control instructions according to the Power status and VCU(HCU, CCU, etc.), NOT ROUTING.";
CM_ SG_ 41 L_ATCU_OutTempDispF "ATCU_OutTemperatureDisplay(¢µ)";
CM_ BO_ 48 "[PE] Periodic and On Event";
CM_ SG_ 48 L_ATCU_SW_Ver1 "ATCU_SoftWare_Version1";
CM_ SG_ 48 L_ATCU_SW_Ver3 "ATCU_SoftWare_Version3";
CM_ SG_ 48 L_ATCU_SW_Ver4 "ATCU_SoftWare_Version4";
CM_ SG_ 48 L_ATCU_SW_Ver5 "ATCU_SoftWare_Version5";
CM_ SG_ 48 L_ATCU_SW_Ver2 "ATCU_SoftWare_Version2";
CM_ BO_ 49 "[PE] Periodic and On Event";
CM_ SG_ 49 L_ATCU_ResetPreWrngForOthers "This is a PDC routing signal for reset preparing sideeffect of reset";
CM_ SG_ 49 L_ATCU_ResetReqForOthers "This is a PDC routing signal for SW reset except for Gateway";
CM_ BO_ 273 "[P] Periodic";
CM_ SG_ 273 L_ATCU_FHPTCOpPrmssnSta "ATCU_FHPTCOperationPermissionStatus";
CM_ SG_ 273 L_ATCU_FHPTCPassTrgtDty "ATCU_FHPTCPassengerTargetDuty";
CM_ SG_ 273 L_ATCU_FHPTCDischrgReq "ATCU_FHPTCDischrgeRequest";
CM_ SG_ 273 L_ATCU_FltMsgTmOutFHPTC1 "ATCU_FltMsgTmOutFHPTC1";
CM_ SG_ 273 L_ATCU_FltMsgTmOutFHPTC2 "ATCU_FltMsgTmOutFHPTC2";
CM_ SG_ 273 L_ATCU_FltMsgTmOutFHPTC3 "ATCU_FltMsgTmOutFHPTC3";
CM_ SG_ 273 L_ATCU_FltMsgTmOutFHPTC4 "ATCU_FltMsgTmOutFHPTC4";
CM_ SG_ 273 L_ATCU_FrBlwLvl "ATCU_FrBlowerLevel";
CM_ SG_ 273 L_ATCU_FrBlwLvlSigVaildSta "ATCU_FrBlowrLevelSignalVaildStatus";
CM_ SG_ 273 L_ATCU_DrvrSdTyp "ATCU_DriverSideType";
CM_ SG_ 273 L_ATCU_FrBlwFltSta "ATCU_FrontBlowerFaultStatus";
CM_ SG_ 273 L_ATCU_PassBlwLvl "ATCU_PasssengerBlowerLevel";
CM_ SG_ 273 L_ATCU_FHPTCDrTrgtDty "ATCU_FHPTCDriverTargetDuty";
CM_ BO_ 65 "[PE] Periodic and On Event";
CM_ SG_ 65 HKBD_Typ1 "HKBD_Type1";
CM_ SG_ 65 HKBD_Typ2 "HKBD_Type2";
CM_ SG_ 65 HKBD_Typ3 "HKBD_Type3";
CM_ BO_ 66 "[PE] Periodic and On Event";
CM_ SG_ 66 HKBD_Fr_DrModDnSw "HKBD_Front_DriverModeDownSwitch";
CM_ SG_ 66 HKBD_Fr_DrModUpSw "HKBD_Front_DriverModeUpSwitch";
CM_ SG_ 66 HKBD_Fr_DrMultiAutoSw "HKBD_Front_DriverMultiAutoSiwtch";
CM_ SG_ 66 HKBD_Fr_PsAutoSw "HKBD_Front_PassengerAutoSwitch";
CM_ SG_ 66 HKBD_Fr_PsMultiAutoSw "HKBD_Front_PassengerMultiAutoSwitch";
CM_ SG_ 66 HKBD_Fr_AcSw "HKBD_Front_ACSwitch";
CM_ SG_ 66 HKBD_Fr_DefSw "HKBD_Front_DEFSwitch";
CM_ SG_ 66 HKBD_Fr_RecSw "HKBD_Front_RecirculationSwitch";
CM_ SG_ 66 HKBD_Fr_DrModVntSw "HKBD_Front_DriverModeVentSwitch";
CM_ SG_ 66 HKBD_Fr_FreSw "HKBD_Front_FreshSwitch";
CM_ SG_ 66 HKBD_Fr_IntakeTglSw "HKBD_Front_IntakeToggleSwitch";
CM_ SG_ 66 HKBD_Fr_OffSw "HKBD_Front_OffSwitch";
CM_ SG_ 66 HKBD_Fr_SyncSw "HKBD_Front_SyncSwitch";
CM_ SG_ 66 HKBD_Fr_RrDefInd "HKBD_Front_RearDEFIndicator";
CM_ SG_ 66 HKBD_Fr_RrDefSw "HKBD_Front_RearDEFSwitch";
CM_ SG_ 66 HKBD_Fr_ArclnSw "HKBD_Front_AirCleaningIndicatorSwitch";
CM_ SG_ 66 HKBD_Fr_DrOnlySw "HKBD_Front_DriverOnlySwitch";
CM_ SG_ 66 HKBD_Fr_ClimateSw "HKBD_Front_ClimateSwitch";
CM_ SG_ 66 HKBD_Fr_PerfumeSw "HKBD_Front_PerfumeSwitch";
CM_ SG_ 66 HKBD_Fr_DrModFlrSw "HKBD_Front_DriverModeFloorSwitch";
CM_ SG_ 66 HKBD_Fr_HptIntnstySta "HKBD_Front_HapticIntensityState";
CM_ SG_ 66 HKBD_Fr_StrWhlHeatSw "HKBD_Front_SteeringWheelHeatSwitch";
CM_ SG_ 66 HKBD_FLStHeatSw "HKBD_FrontLeftSeatHeatSwitch";
CM_ SG_ 66 HKBD_FLStVentSw "HKBD_FrontLeftSeatVentSwitch";
CM_ SG_ 66 HKBD_FRStHeatSw "HBKD_FrontRightSeatHeatSwitch";
CM_ SG_ 66 HKBD_FRStVentSw "HKBD_FrontRightSeatVentSwitch";
CM_ SG_ 66 HKBD_FLStTumblrSw "HKBD_FrontLeftSeatTumblerSwitch";
CM_ SG_ 66 HKBD_Fr_DrModDefSw "HKBD_Front_DriverModeDEFSwitch";
CM_ SG_ 66 HKBD_FRStTumblrSw "HKBD_FrontRightSeatTumblerSwitch";
CM_ SG_ 66 HKBD_Fr_FrWndShldHtSw "HKBD_Front_FrontWindShieldHeatSwitch";
CM_ SG_ 66 HKBD_Fr_DrAutoDnSw "HKBD_Front_DriverAutoDownSwitch";
CM_ SG_ 66 HKBD_Fr_DrAutoUpSw "HKBD_Front_DriverAutoUpSwitch";
CM_ SG_ 66 HKBD_Fr_DrModSw "HKBD_Front_DriverModeSwitch";
CM_ SG_ 66 HKBD_Fr_PsModSw "HKBD_Front_PassengerModeSwitch";
CM_ SG_ 66 HKBD_DisplayTheme "HKBD_DisplayTheme (Black/White)";
CM_ SG_ 66 HKBD_Fr_PsModDnSw "HKBD_Front_PassengerModeDownSwitch";
CM_ SG_ 66 HKBD_Fr_SmartZoneSW "HKBD_Fr_SmartZoneSwitch";
CM_ SG_ 66 HKBD_Fr_PsModUpSw "HKBD_Front_PassengerModeUpSwitch";
CM_ SG_ 66 HKBD_Fr_PsModVntSw "HKBD_Front_PassengerModeVentSwitch";
CM_ SG_ 66 HKBD_Fr_PsModFlrSw "HKBD_Front_PasengerModeFloorSwitch";
CM_ SG_ 66 HKBD_Fr_DrAutoSw "HKBD_Front_DriverAutoSwitch";
CM_ BO_ 67 "[EC] On Event and On Change";
CM_ SG_ 67 HKBD_Fr_DrTempClickCnt "HKBD_Front_DriverTemperatureClickCount";
CM_ SG_ 67 HKBD_Fr_RrTempClickCnt "HKBD_Front_RearTemperatureClickCount";
CM_ SG_ 67 HKBD_Fr_DrBlwClickCnt "HKBD_Front_DriverBlowerClickCount";
CM_ SG_ 67 HKBD_Fr_PsBlwClickCnt "HKBD_Front_PassengerBlowerClickCount";
CM_ SG_ 67 HKBD_FrTempKnobCnt "HKBD_FrontTempKnobCount (for knobs rotate count)";
CM_ SG_ 67 HKBD_FrBlwKnobCnt "HKBD_FrontBlowerKnobCount (for knobs rotate count)";
CM_ SG_ 67 HKBD_Fr_PsTempClickCnt "HKBD_Front_PassengerTemperatureClickCount";
CM_ BO_ 68 "[PE] Periodic and On Event";
CM_ SG_ 68 HKBD_Fr_DrTempDnSw "HKBD_Front_DriverTemperatureDownSwitch";
CM_ SG_ 68 HKBD_Fr_DrTempUpSw "HKBD_Front_DriverTemperatureUpSwitch";
CM_ SG_ 68 HKBD_Fr_PsBlwDnSw "HKBD_Front_PassengerBlowerDownSwitch";
CM_ SG_ 68 HKBD_Fr_PsBlwDnOffSw "HKBD_Front_PasengerBlowerDownOffSwitch";
CM_ SG_ 68 HKBD_Fr_PsBlwUpSw "HKBD_Front_PassengerBlowerUpSwitch";
CM_ SG_ 68 HKBD_Fr_PsBlwSet "HKBD_Front_PassengerBlowerSet";
CM_ SG_ 68 HKBD_Fr_RrDrTempDnSw "HKBD_Front_RearDriverTemperatureDownSwitch";
CM_ SG_ 68 HKBD_Fr_RrDrTempUpSw "HKBD_Front_RearDriverTemperatureUpSwitch";
CM_ SG_ 68 HKBD_Fr_PsTempDnSw "HKBD_Front_PassengerTemperatureDownSwitch";
CM_ SG_ 68 HKBD_Fr_RrDrBlwDnSw "HKBD_Front_RearDriverBlowerDownSwitch";
CM_ SG_ 68 HKBD_Fr_RrDrBlwDnOffSw "HKBD_Front_RearDriverBlowerDownOffSwitch";
CM_ SG_ 68 HKBD_Fr_RrDrBlwUpSw "HKBD_Front_RearDriverBlowerUpSwitch";
CM_ SG_ 68 HKBD_Fr_RrDrBlwSet "HKBD_Front_RearDriverBlowerSet";
CM_ SG_ 68 HKBD_Fr_RrDrModDnSw "HKBD_Front_RearDriverModeDownSiwtch";
CM_ SG_ 68 HKBD_Fr_RrDrModUpSw "HKBD_Front_RearDriverModeUpSwitch";
CM_ SG_ 68 HKBD_Fr_RrDrModVntSw "HKBD_Front_RearDriverModeVentSwitch";
CM_ SG_ 68 HKBD_Fr_PsTempUpSw "HKBD_Front_PassengerTemperatureUpSwitch";
CM_ SG_ 68 HKBD_Fr_RrDrModFlrSw "HKBD_Front_RearDriverModeFloorSwitch";
CM_ SG_ 68 HKBD_Fr_RrDrModBiLvlSw "HKBD_Front_RearDriverModeBiLevelSwitch";
CM_ SG_ 68 HKBD_Fr_RrDrAutoSw "HKBD_Front_RearDriverAutoSwitch";
CM_ SG_ 68 HKBD_Fr_RrDrMultiAutoSw "HKBD_Front_RearDriverMultiAutoSwitch";
CM_ SG_ 68 HKBD_Fr_RrOffSw "HKBD_Front_RearOffSwitch";
CM_ SG_ 68 HKBD_Fr_RrSyncSw "HKBD_Front_RearSyncSwitch";
CM_ SG_ 68 HKBD_Fr_RLStHeatSw "HKBD_Front_RearLeftSeatHeatSwitch";
CM_ SG_ 68 HKBD_Fr_RLStVentSw "HKBD_Front_RearLeftSeatVentSwitch";
CM_ SG_ 68 HKBD_Fr_DrBlwDnSw "HKBD_Front_DriverBLowerDownSwitch";
CM_ SG_ 68 HKBD_Fr_RRStHeatSw "HKBD_Front_RearRightSeatHeatSwitch";
CM_ SG_ 68 HKBD_Fr_RRStVentSw "HKBD_Front_RearRightSeatVentSwitch";
CM_ SG_ 68 HKBD_Fr_RLStTumblrSw "HKBD_Front_RearLeftSeatTumblerSwitch";
CM_ SG_ 68 HKBD_Fr_RRStTumblrSw "HKBD_Front_RearRightSeatTumblerSwitch";
CM_ SG_ 68 HKBD_Fr_RrPsModDnSw "HKBD_Front_RearPassengerModeDownSwitch";
CM_ SG_ 68 HKBD_Fr_RrPsModUpSw "HKBD_Front_RearPassengerModeUpSwitch";
CM_ SG_ 68 HKBD_Fr_RrPsModVntSw "HKBD_Front_RearPassengerModeVentSwitch";
CM_ SG_ 68 HKBD_Fr_RrPsModFlrSw "HKBD_Front_RearPassengerModeFloorSwitch";
CM_ SG_ 68 HKBD_Fr_DrBlwDnOffSw "HKBD_Front_DriverBlowerDownOffSwitch";
CM_ SG_ 68 HKBD_Fr_RrLockSw "HKBD_Front_RearLockSwitch";
CM_ SG_ 68 HKBD_Fr_RrPsModBiLvlSw "HKBD_Front_RearPassengerrModeBiLevelSwitch";
CM_ SG_ 68 HKBD_Fr_RrDrModSw "HKBD_Front_RearDriverModeSwitch";
CM_ SG_ 68 HKBD_Fr_RrPsModSw "HKBD_Front_RearPassengerModeSwitch";
CM_ SG_ 68 HKBD_Fr_RrPsBlwSet "HKBD_Front_RearPassengerBlowerSet";
CM_ SG_ 68 HKBD_Fr_RrPsBlwUpSw "HKBD_Front_RearPassengerBlowerUpSwitch";
CM_ SG_ 68 HKBD_Fr_RrPsBlwDnSw "HKBD_Front_RearPassengerBlowerDownSwitch";
CM_ SG_ 68 HKBD_Fr_DrBlwUpSw "HKBD_Front_DriverBlowerUpSwitch";
CM_ SG_ 68 HKBD_Fr_RrPsBlwDnOffSw "HKBD_Front_RearPassengerBlowerDownOffSwitch";
CM_ SG_ 68 HKBD_Fr_RrPsTempDnSw "HKBD_Front_RearPassengerTemperatureDownSwitch";
CM_ SG_ 68 HKBD_Fr_RrPsTempUpSw "HKBD_Front_RearPassengerTemperatureUpSwitch";
CM_ SG_ 68 HKBD_Fr_DrBlwSet "HKBD_Front_DriverBlowerSet";
CM_ BO_ 69 "[PE] Periodic and On Event";
CM_ SG_ 69 HKBD_Fr_3rdRrTempDnSw "HKBD_Front_3rdRearTemperatureDownSwitch";
CM_ SG_ 69 HKBD_Fr_3rdRrTempUpSw "HKBD_Front_3rdRearTemperatureUpSwitch";
CM_ SG_ 69 HKBD_Fr_3rdRrModUpSw "HKBD_Front_3rdRearModeUpSwitch";
CM_ SG_ 69 HKBD_Fr_3rdRrModVntSw "HKBD_Front_3rdRearModeVentSwitch";
CM_ SG_ 69 HKBD_Fr_3rdRrModFlrSw "HKBD_Front_3rdRearModeFloorSwitch";
CM_ SG_ 69 HKBD_Fr_3rdRrAutoSw "HKBD_Front_3rdRearAutoSwitch";
CM_ SG_ 69 HKBD_Fr_3rdRrMultiAutoSw "HKBD_Front_3rdRearMultiAutoSwitch";
CM_ SG_ 69 HKBD_Fr_3rdRrOffSw "HKBD_Front_3rdRearOffSwitch";
CM_ SG_ 69 HKBD_Fr_3rdRrSyncSw "HKBD_Front_3rdRearSyncSwitch";
CM_ SG_ 69 HKBD_Fr_3rdRrLockSw "HKBD_Front_3rdRearLockSwitch";
CM_ SG_ 69 HKBD_Fr_3rdRrBlwDnSw "HKBD_Front_3rdRearBlowerDownSwitch";
CM_ SG_ 69 HKBD_Fr_3rdRrModBiLvlSw "HKBD_Front_3rdRearModeBiLevelSwitch";
CM_ SG_ 69 HKBD_FrRrTglSet "HKBD_FrontRearToggleSet";
CM_ SG_ 69 HKBD_Fr_RrScrnSet "HKBD_FrontRearScreenSet";
CM_ SG_ 69 HKBD_Fr_OnOffSet "HKBD_Front_OnOffSet";
CM_ SG_ 69 HKBD_Fr_RrOnOffSet "HKBD_Front_RearOnOffSet";
CM_ SG_ 69 HKBD_Fr_3rdRrOnOffSet "HKBD_Front_3rdRearOnOffSet";
CM_ SG_ 69 HKBD_Fr_3rdRrBlwDnOffSw "HKBD_Front_3rdRearBlowerDownOffSwitch";
CM_ SG_ 69 HKBD_Fr_RrPsAutoSw "HKBD_Front_RearPassengerAutoSwitch";
CM_ SG_ 69 HKBD_Fr_RrPsMultiAutoSw "HKBD_Front_RearPassengerMultiAutoSwitch";
CM_ SG_ 69 HKBD_Fr_3rdRrModSw "HKBD_Front_3rdRearModeSwitch";
CM_ SG_ 69 HKBD_Fr_3rdRrBlwUpSw "HKBD_Front_3rdRearBlowerUpSwitch";
CM_ SG_ 69 HKBD_Fr_3rdRrBlwSet "HKBD_Front_3rdRearBlowerSet";
CM_ SG_ 69 HKBD_Fr_3rdRrModDnSw "HKBD_Front_3rdRearModeDownSwitch";
CM_ BO_ 70 "[PE] Periodic and On Event";
CM_ SG_ 70 HKBD_SwBtnTyp "HKBD_SwitchButtonType";
CM_ SG_ 70 L_HKBD_ResetOpSta "This signal indicates whether the reset operation has been completed or not";
CM_ BO_ 71 "[EC] On Event and On Change";
CM_ SG_ 71 HKBD_Fr_RrDrTempClickCnt "HKBD_Front_RearDriverTemperatureClickCount";
CM_ SG_ 71 HKBD_Fr_RrPsTempClickCnt "HKBD_Front_RearPassengerTemperatureClickCount";
CM_ SG_ 71 HKBD_Fr_RrPsBlwClickCnt "HKBD_Front_RearPassengerBlowerClickCount";
CM_ SG_ 71 HKBD_Fr_3rdRrTempClickCnt "HKBD_Front_3rdRearTepmperatureClickCount";
CM_ SG_ 71 HKBD_Fr_3rdRrBlwClickCnt "HKBD_Front_3rdRearBlowerClickCount";
CM_ SG_ 71 HKBD_Fr_RrTempKnobCnt "HKBD_Front_RearTemperatureKnobCount (for knobs rotate count)";
CM_ SG_ 71 HKBD_Fr_RrBlwKnobCnt "HKBD_Front_RearBlowerKnobCount (for knobs rotate count)";
CM_ SG_ 71 HKBD_Fr_3rdTempKnobCnt "HKBD_Front_3rdTemperatureKnobCount (for knobs rotate count)";
CM_ SG_ 71 HKBD_Fr_3rdBlwKnobCnt "HKBD_Front_3rdBlowerKnobCount (for knobs rotate count)";
CM_ SG_ 71 HKBD_Fr_RrDrBlwClickCnt "HKBD_Front_RearDriverBlowerClickCount";
CM_ BO_ 72 "[P] Periodic";
CM_ SG_ 72 HKBD_Fr_IncarRaw "HKBD_Front_IncarSensorRawValue";
BA_DEF_ BO_ "UsrMsgIDSforwardDeviation" INT 0 100 ;
BA_DEF_ BO_ "UsrMsgIDSbackwardDeviation" INT 50 1000 ;
BA_DEF_ "BusType" STRING ;
BA_DEF_ "DBName" STRING ;
BA_DEF_ "Baudrate" INT 50000 1000000 ;
BA_DEF_ "GenEnvVarEndingDsp" STRING ;
BA_DEF_ "GenEnvVarEndingSnd" STRING ;
BA_DEF_ "GenEnvVarPrefix" STRING ;
BA_DEF_ "GenNWMApBusSleep" STRING ;
BA_DEF_ "GenNWMApCanNormal" STRING ;
BA_DEF_ "GenNWMApCanOff" STRING ;
BA_DEF_ "GenNWMApCanOn" STRING ;
BA_DEF_ "GenNWMApCanSleep" STRING ;
BA_DEF_ "GenNWMApCanWakeUp" STRING ;
BA_DEF_ "GenNWMGotoMode_Awake" STRING ;
BA_DEF_ "GenNWMGotoMode_BusSleep" STRING ;
BA_DEF_ "GenNWMSleepTime" INT 1375 1650 ;
BA_DEF_ "GenNWMTalkNM" STRING ;
BA_DEF_ "Manufacturer" STRING ;
BA_DEF_ "NmBaseAddress" HEX 0 2047 ;
BA_DEF_ "NmMessageCount" INT 0 128 ;
BA_DEF_ "NmType" STRING ;
BA_DEF_ "SamplePointMax" INT 50 85 ;
BA_DEF_ "SamplePointMin" INT 55 85 ;
BA_DEF_ "SyncJumpWidthMax" INT 1 8 ;
BA_DEF_ "SyncJumpWidthMin" INT 1 4 ;
BA_DEF_ "VersionDay" INT 1 31 ;
BA_DEF_ "VersionMonth" INT 1 12 ;
BA_DEF_ "VersionNumber" INT 0 999999 ;
BA_DEF_ "VersionNumberInternal" INT 0 9999 ;
BA_DEF_ "VersionWeek" INT 1 53 ;
BA_DEF_ "VersionYear" INT 0 9999 ;
BA_DEF_ BU_ "NmStationAddress" HEX 0 255 ;
BA_DEF_ BU_ "NmNode" ENUM "No","Yes" ;
BA_DEF_ BU_ "GenNodSleepTime" INT 1375 1650 ;
BA_DEF_ BU_ "ILUsed" ENUM "No","Yes" ;
BA_DEF_ BU_ "NmCAN" INT 1 2 ;
BA_DEF_ BU_ "NodeLayerModules" STRING ;
BA_DEF_ BU_ "NWM_Knoten" ENUM "No","Yes" ;
BA_DEF_ BO_ "GenMsgCycleTime" INT 0 2000 ;
BA_DEF_ BO_ "GenMsgStartDelayTime" INT 0 2000 ;
BA_DEF_ BO_ "GenMsgSendType" ENUM "Cyclic","NoMsgSendType" ;
BA_DEF_ BO_ "GenMsgCycleTimeFast" INT 0 500 ;
BA_DEF_ BO_ "GenMsgDelayTime" INT 0 20 ;
BA_DEF_ BO_ "GenMsgILSupport" ENUM "No","Yes" ;
BA_DEF_ BO_ "GenMsgNrOfRepetition" INT 0 3 ;
BA_DEF_ BO_ "VFrameFormat" ENUM "StandardCAN","ExtendedCAN","reserved","reserved","reserved","reserved","reserved","reserved","reserved","reserved","reserved","reserved","reserved","reserved","StandardCAN_FD","ExtendedCAN_FD" ;
BA_DEF_ SG_ "UserSigValidity" ENUM "B+","ACC","IG","IG1","IG2","IG3","IG1 or IG2","IG1 or IG3","Undef" ;
BA_DEF_ SG_ "UsrSigPurpose" ENUM "Undef","FN","DIAG","DIAG(Req)","DIAG(Res)","DIAG(Phy)","DEV","CCP(Req)","CCP(Res)","NM","TP" ;
BA_DEF_ SG_ "GenSigStartValue" INT 0 1215752192 ;
BA_DEF_ SG_ "NetworkRequestHoldingTime" INT 0 65535 ;
BA_DEF_ SG_ "Description" STRING ;
BA_DEF_ SG_ "Version" STRING ;
BA_DEF_ SG_ "GenSigEnvVarType" ENUM "Int","Float","Undef" ;
BA_DEF_ SG_ "GenSigSendType" ENUM "Cyclic","OnWrite","OnWriteWithRepetition","OnChange","OnChangeWithRepetition","IfActive","IfActiveWithRepetition","NoSigSendType","OnChangeAndIfActive","OnChangeAndIfActiveWithRepetition" ;
BA_DEF_ SG_ "GwSigLatencyTime" INT 0 65536 ;
BA_DEF_ SG_ "GwSigMissingSourceType" ENUM "Undef","OldValue","DefaultValue","InitialValue" ;
BA_DEF_ SG_ "NWM-WakeupAllowed" ENUM "<n.a.>" ;
BA_DEF_ SG_ "RoutingFactor" INT 1 1215752192 ;
BA_DEF_REL_ BU_SG_REL_ "GenSigTimeoutTime" INT 0 7000 ;
BA_DEF_DEF_ "UsrMsgIDSforwardDeviation" 10 ;
BA_DEF_DEF_ "UsrMsgIDSbackwardDeviation" 100 ;
BA_DEF_DEF_ "BusType" "CAN" ;
BA_DEF_DEF_ "DBName" "" ;
BA_DEF_DEF_ "Baudrate" 500000 ;
BA_DEF_DEF_ "GenEnvVarEndingDsp" "Dsp_" ;
BA_DEF_DEF_ "GenEnvVarEndingSnd" "_" ;
BA_DEF_DEF_ "GenEnvVarPrefix" "Env" ;
BA_DEF_DEF_ "GenNWMApBusSleep" "AppNmCanBusSleep()" ;
BA_DEF_DEF_ "GenNWMApCanNormal" "AppNmCanNormal()" ;
BA_DEF_DEF_ "GenNWMApCanOff" "ApplCanOffline()" ;
BA_DEF_DEF_ "GenNWMApCanOn" "ApplCanOnline()" ;
BA_DEF_DEF_ "GenNWMApCanSleep" "ApplNmCanSleep()" ;
BA_DEF_DEF_ "GenNWMApCanWakeUp" "ApplCanWakeUp()" ;
BA_DEF_DEF_ "GenNWMGotoMode_Awake" "GotoMode_Awake()" ;
BA_DEF_DEF_ "GenNWMGotoMode_BusSleep" "GotoMode_BusSleep()" ;
BA_DEF_DEF_ "GenNWMSleepTime" 1500 ;
BA_DEF_DEF_ "GenNWMTalkNM" "TalkNM()" ;
BA_DEF_DEF_ "Manufacturer" "HMC" ;
BA_DEF_DEF_ "NmBaseAddress" 1280 ;
BA_DEF_DEF_ "NmMessageCount" 128 ;
BA_DEF_DEF_ "NmType" "Vector" ;
BA_DEF_DEF_ "SamplePointMax" 80 ;
BA_DEF_DEF_ "SamplePointMin" 80 ;
BA_DEF_DEF_ "SyncJumpWidthMax" 3 ;
BA_DEF_DEF_ "SyncJumpWidthMin" 2 ;
BA_DEF_DEF_ "VersionDay" 1 ;
BA_DEF_DEF_ "VersionMonth" 1 ;
BA_DEF_DEF_ "VersionNumber" 0 ;
BA_DEF_DEF_ "VersionNumberInternal" 0 ;
BA_DEF_DEF_ "VersionWeek" 1 ;
BA_DEF_DEF_ "VersionYear" 0 ;
BA_DEF_DEF_ "NmStationAddress" 0 ;
BA_DEF_DEF_ "NmNode" "Yes" ;
BA_DEF_DEF_ "GenNodSleepTime" 1500 ;
BA_DEF_DEF_ "ILUsed" "Yes" ;
BA_DEF_DEF_ "NmCAN" 1 ;
BA_DEF_DEF_ "NodeLayerModules" "oseknm01.dll,CANoeILNLVector.dll" ;
BA_DEF_DEF_ "NWM_Knoten" "Yes" ;
BA_DEF_DEF_ "GenMsgCycleTime" 200 ;
BA_DEF_DEF_ "GenMsgStartDelayTime" 0 ;
BA_DEF_DEF_ "GenMsgSendType" "NoMsgSendType" ;
BA_DEF_DEF_ "GenMsgCycleTimeFast" 40 ;
BA_DEF_DEF_ "GenMsgDelayTime" 20 ;
BA_DEF_DEF_ "GenMsgILSupport" "Yes" ;
BA_DEF_DEF_ "GenMsgNrOfRepetition" 3 ;
BA_DEF_DEF_ "VFrameFormat" "StandardCAN" ;
BA_DEF_DEF_ "UserSigValidity" "IG" ;
BA_DEF_DEF_ "UsrSigPurpose" "FN" ;
BA_DEF_DEF_ "GenSigStartValue" 0 ;
BA_DEF_DEF_ "NetworkRequestHoldingTime" 0 ;
BA_DEF_DEF_ "Description" "" ;
BA_DEF_DEF_ "Version" "" ;
BA_DEF_DEF_ "GenSigEnvVarType" "Undef" ;
BA_DEF_DEF_ "GenSigSendType" "NoSigSendType" ;
BA_DEF_DEF_ "GwSigLatencyTime" 40 ;
BA_DEF_DEF_ "GwSigMissingSourceType" "Undef" ;
BA_DEF_DEF_ "NWM-WakeupAllowed" "<n.a.>" ;
BA_DEF_DEF_ "RoutingFactor" 1 ;
BA_DEF_DEF_REL_ "GenSigTimeoutTime" 500 ;
BA_ "DBName" "Local_HS";
BA_ "VersionYear" 1;
BA_ "VersionNumber" 241101;
BA_ "NmNode" BU_ L_ATCU 0;
BA_ "GenMsgSendType" BO_ 33 0;
BA_ "GenMsgCycleTime" BO_ 33 500;
BA_ "NmNode" BU_ L_HKBD 0;
BA_ "Description" SG_ 33 L_ATCU_Typ1 "This signal includes regional information.";
BA_ "GenSigSendType" SG_ 33 L_ATCU_Typ1 4;
BA_ "UserSigValidity" SG_ 33 L_ATCU_Typ1 7;
BA_REL_ "GenSigTimeoutTime" BU_SG_REL_ L_HKBD SG_ 33 L_ATCU_Typ1 5000;
BA_ "Version" SG_ 33 L_ATCU_Typ1 "23.08.13";
BA_ "NmNode" BU_ L_2HKBD 0;
BA_ "NmNode" BU_ L_3HKBD 0;
BA_ "Description" SG_ 33 L_ATCU_Typ_All_2 "Bit0~1 (2nd Blower Control): 0???None / 1???Single / 2 - Dual / 3???(Reserved)

Bit2~3 (2nd TEMP Control): 0???None / 1???Single / 2 - Dual / 3???(Reserved)

Bit4~5 (2nd MODE Control): 0???None / 1???Single / 2 - Dual / 3???(Reserved)

Bit6~7 (2nd AUTO Control): 0???None / 1???Single / 2 - Dual / 3???(Reserved)";
BA_ "GenSigSendType" SG_ 33 L_ATCU_Typ_All_2 4;
BA_ "UserSigValidity" SG_ 33 L_ATCU_Typ_All_2 7;
BA_REL_ "GenSigTimeoutTime" BU_SG_REL_ L_2HKBD SG_ 33 L_ATCU_Typ_All_2 5000;
BA_REL_ "GenSigTimeoutTime" BU_SG_REL_ L_3HKBD SG_ 33 L_ATCU_Typ_All_2 5000;
BA_REL_ "GenSigTimeoutTime" BU_SG_REL_ L_HKBD SG_ 33 L_ATCU_Typ_All_2 5000;
BA_ "Version" SG_ 33 L_ATCU_Typ_All_2 "24.08.00";
BA_ "Description" SG_ 33 L_ATCU_TempDispSta "Temperature range options";
BA_ "GenSigSendType" SG_ 33 L_ATCU_TempDispSta 4;
BA_ "GenSigStartValue" SG_ 33 L_ATCU_TempDispSta 1;
BA_ "UserSigValidity" SG_ 33 L_ATCU_TempDispSta 7;
BA_REL_ "GenSigTimeoutTime" BU_SG_REL_ L_2HKBD SG_ 33 L_ATCU_TempDispSta 5000;
BA_REL_ "GenSigTimeoutTime" BU_SG_REL_ L_3HKBD SG_ 33 L_ATCU_TempDispSta 5000;
BA_REL_ "GenSigTimeoutTime" BU_SG_REL_ L_HKBD SG_ 33 L_ATCU_TempDispSta 5000;
BA_ "Version" SG_ 33 L_ATCU_TempDispSta "24.08.00";
BA_ "Description" SG_ 33 L_ATCU_StrgWhlHeatingOpt "Steering Wheel Heating Option : Used when receiving CAN signals (C_StrgWhlHeatingOpt @ICU/PDC). If the vehicle does not receive CAN, 0x3: Invalid transmission, unable to transmit singular information.";
BA_ "GenSigSendType" SG_ 33 L_ATCU_StrgWhlHeatingOpt 4;
BA_ "GenSigStartValue" SG_ 33 L_ATCU_StrgWhlHeatingOpt 3;
BA_ "UserSigValidity" SG_ 33 L_ATCU_StrgWhlHeatingOpt 7;
BA_REL_ "GenSigTimeoutTime" BU_SG_REL_ L_2HKBD SG_ 33 L_ATCU_StrgWhlHeatingOpt 5000;
BA_REL_ "GenSigTimeoutTime" BU_SG_REL_ L_3HKBD SG_ 33 L_ATCU_StrgWhlHeatingOpt 5000;
BA_REL_ "GenSigTimeoutTime" BU_SG_REL_ L_HKBD SG_ 33 L_ATCU_StrgWhlHeatingOpt 5000;
BA_ "Version" SG_ 33 L_ATCU_StrgWhlHeatingOpt "24.08.00";
BA_ "Description" SG_ 33 L_ATCU_Drv_SeatOptSta "Heater/ventilation option specification applied to Driver seat (LH side for LHD / RH side for RHD)";
BA_ "GenSigSendType" SG_ 33 L_ATCU_Drv_SeatOptSta 4;
BA_ "UserSigValidity" SG_ 33 L_ATCU_Drv_SeatOptSta 7;
BA_REL_ "GenSigTimeoutTime" BU_SG_REL_ L_2HKBD SG_ 33 L_ATCU_Drv_SeatOptSta 5000;
BA_REL_ "GenSigTimeoutTime" BU_SG_REL_ L_3HKBD SG_ 33 L_ATCU_Drv_SeatOptSta 5000;
BA_REL_ "GenSigTimeoutTime" BU_SG_REL_ L_HKBD SG_ 33 L_ATCU_Drv_SeatOptSta 5000;
BA_ "Version" SG_ 33 L_ATCU_Drv_SeatOptSta "23.08.13";
BA_ "Description" SG_ 33 L_ATCU_Ast_SeatOptSta "Heater/ventilation option specification applied to Driver seat (LH side for LHD / RH side for RHD)";
BA_ "GenSigSendType" SG_ 33 L_ATCU_Ast_SeatOptSta 4;
BA_ "UserSigValidity" SG_ 33 L_ATCU_Ast_SeatOptSta 7;
BA_REL_ "GenSigTimeoutTime" BU_SG_REL_ L_2HKBD SG_ 33 L_ATCU_Ast_SeatOptSta 5000;
BA_REL_ "GenSigTimeoutTime" BU_SG_REL_ L_3HKBD SG_ 33 L_ATCU_Ast_SeatOptSta 5000;
BA_REL_ "GenSigTimeoutTime" BU_SG_REL_ L_HKBD SG_ 33 L_ATCU_Ast_SeatOptSta 5000;
BA_ "Version" SG_ 33 L_ATCU_Ast_SeatOptSta "23.08.13";
BA_ "Description" SG_ 33 L_ATCU_RL_SeatOptSta "Heater/ventilation option specification applied to Driver seat (LH side for LHD / RH side for RHD)";
BA_ "GenSigSendType" SG_ 33 L_ATCU_RL_SeatOptSta 4;
BA_ "UserSigValidity" SG_ 33 L_ATCU_RL_SeatOptSta 7;
BA_REL_ "GenSigTimeoutTime" BU_SG_REL_ L_2HKBD SG_ 33 L_ATCU_RL_SeatOptSta 5000;
BA_REL_ "GenSigTimeoutTime" BU_SG_REL_ L_3HKBD SG_ 33 L_ATCU_RL_SeatOptSta 5000;
BA_REL_ "GenSigTimeoutTime" BU_SG_REL_ L_HKBD SG_ 33 L_ATCU_RL_SeatOptSta 5000;
BA_ "Version" SG_ 33 L_ATCU_RL_SeatOptSta "23.08.13";
BA_ "Description" SG_ 33 L_ATCU_RR_SeatOptSta "Heater/ventilation option specification applied to Driver seat (LH side for LHD / RH side for RHD)";
BA_ "GenSigSendType" SG_ 33 L_ATCU_RR_SeatOptSta 4;
BA_ "UserSigValidity" SG_ 33 L_ATCU_RR_SeatOptSta 7;
BA_REL_ "GenSigTimeoutTime" BU_SG_REL_ L_2HKBD SG_ 33 L_ATCU_RR_SeatOptSta 5000;
BA_REL_ "GenSigTimeoutTime" BU_SG_REL_ L_3HKBD SG_ 33 L_ATCU_RR_SeatOptSta 5000;
BA_REL_ "GenSigTimeoutTime" BU_SG_REL_ L_HKBD SG_ 33 L_ATCU_RR_SeatOptSta 5000;
BA_ "Version" SG_ 33 L_ATCU_RR_SeatOptSta "23.08.13";
BA_ "Description" SG_ 33 L_ATCU_SmartZoneDis "Smart HVAC SmartZone on/off signal";
BA_ "GenSigSendType" SG_ 33 L_ATCU_SmartZoneDis 4;
BA_ "UserSigValidity" SG_ 33 L_ATCU_SmartZoneDis 7;
BA_REL_ "GenSigTimeoutTime" BU_SG_REL_ L_HKBD SG_ 33 L_ATCU_SmartZoneDis 1500;
BA_ "Version" SG_ 33 L_ATCU_SmartZoneDis "24.11.00";
BA_ "Description" SG_ 33 L_ATCU_Typ_All_3 "Bit0~1 (3rd Blower Control): 0???None / 1???Single / 2 - Dual / 3???(Reserved)

Bit2~3 (3rd TEMP Control): 0???None / 1???Single / 2 - Dual / 3???(Reserved)

Bit4~5 (3rd MODE Control): 0???None / 1???Single / 2 - Dual / 3???(Reserved)

Bit6~7 (3rd AUTO Control): 0???None / 1???Single / 2 - Dual / 3???(Reserved)";
BA_ "GenSigSendType" SG_ 33 L_ATCU_Typ_All_3 4;
BA_ "UserSigValidity" SG_ 33 L_ATCU_Typ_All_3 7;
BA_REL_ "GenSigTimeoutTime" BU_SG_REL_ L_2HKBD SG_ 33 L_ATCU_Typ_All_3 5000;
BA_REL_ "GenSigTimeoutTime" BU_SG_REL_ L_3HKBD SG_ 33 L_ATCU_Typ_All_3 5000;
BA_REL_ "GenSigTimeoutTime" BU_SG_REL_ L_HKBD SG_ 33 L_ATCU_Typ_All_3 5000;
BA_ "Version" SG_ 33 L_ATCU_Typ_All_3 "24.08.00";
BA_ "Description" SG_ 33 L_ATCU_Typ_All_1 "Bit0~1 (Front Blower Control): 0 ? None / 1 ? Single / 2 - Dual / 3 ? (Reserved)

Bit2~3 (Front TEMP Control): 0 ? None / 1 ? Single / 2 - Dual / 3 ? (Reserved)

Bit4~5 (Front MODE Control): 0 ? None / 1 ? Single / 2 - Dual / 3 ? (Reserved)

Bit6~7 (Front AUTO Control): 0 ? None / 1 ? Single / 2 - Dual / 3 ? (Reserved)";
BA_ "GenSigSendType" SG_ 33 L_ATCU_Typ_All_1 4;
BA_ "UserSigValidity" SG_ 33 L_ATCU_Typ_All_1 7;
BA_REL_ "GenSigTimeoutTime" BU_SG_REL_ L_2HKBD SG_ 33 L_ATCU_Typ_All_1 5000;
BA_REL_ "GenSigTimeoutTime" BU_SG_REL_ L_3HKBD SG_ 33 L_ATCU_Typ_All_1 5000;
BA_REL_ "GenSigTimeoutTime" BU_SG_REL_ L_HKBD SG_ 33 L_ATCU_Typ_All_1 5000;
BA_ "Version" SG_ 33 L_ATCU_Typ_All_1 "24.08.00";
BA_ "GenMsgSendType" BO_ 34 0;
BA_ "Description" SG_ 34 L_ATCU_DrTempCDis "This signal indicates Outside temperature (¡É).

(Use for display only)";
BA_ "GenSigSendType" SG_ 34 L_ATCU_DrTempCDis 4;
BA_ "UserSigValidity" SG_ 34 L_ATCU_DrTempCDis 7;
BA_REL_ "GenSigTimeoutTime" BU_SG_REL_ L_HKBD SG_ 34 L_ATCU_DrTempCDis 1500;
BA_ "Version" SG_ 34 L_ATCU_DrTempCDis "23.08.13";
BA_ "GenSigSendType" SG_ 34 L_ATCU_DrTempFDis 4;
BA_ "UserSigValidity" SG_ 34 L_ATCU_DrTempFDis 7;
BA_REL_ "GenSigTimeoutTime" BU_SG_REL_ L_HKBD SG_ 34 L_ATCU_DrTempFDis 1500;
BA_ "Version" SG_ 34 L_ATCU_DrTempFDis "23.08.13";
BA_ "GenSigSendType" SG_ 34 L_ATCU_PassTempFDis 4;
BA_ "UserSigValidity" SG_ 34 L_ATCU_PassTempFDis 7;
BA_REL_ "GenSigTimeoutTime" BU_SG_REL_ L_HKBD SG_ 34 L_ATCU_PassTempFDis 1500;
BA_ "Version" SG_ 34 L_ATCU_PassTempFDis "23.08.13";
BA_ "NmNode" BU_ L_EVNT 0;
BA_ "Description" SG_ 34 L_ATCU_FrDrModDis "ATCU_FrontDriverModeDisplay";
BA_ "GenSigSendType" SG_ 34 L_ATCU_FrDrModDis 4;
BA_ "UserSigValidity" SG_ 34 L_ATCU_FrDrModDis 7;
BA_REL_ "GenSigTimeoutTime" BU_SG_REL_ L_EVNT SG_ 34 L_ATCU_FrDrModDis 1500;
BA_REL_ "GenSigTimeoutTime" BU_SG_REL_ L_HKBD SG_ 34 L_ATCU_FrDrModDis 1500;
BA_ "Version" SG_ 34 L_ATCU_FrDrModDis "24.05.08";
BA_ "Description" SG_ 34 L_ATCU_FrPassModDis "ATCU_FrontPassengerModeDisplay";
BA_ "GenSigSendType" SG_ 34 L_ATCU_FrPassModDis 4;
BA_ "UserSigValidity" SG_ 34 L_ATCU_FrPassModDis 7;
BA_REL_ "GenSigTimeoutTime" BU_SG_REL_ L_EVNT SG_ 34 L_ATCU_FrPassModDis 1500;
BA_REL_ "GenSigTimeoutTime" BU_SG_REL_ L_HKBD SG_ 34 L_ATCU_FrPassModDis 1500;
BA_ "Version" SG_ 34 L_ATCU_FrPassModDis "24.05.08";
BA_ "Description" SG_ 34 L_ATCU_FrDrBlwDis "This signal indicates step of Front Blower graphic.

This signal occurs when Front Blower siwtch(button) is selected either manually or automatically.";
BA_ "GenSigSendType" SG_ 34 L_ATCU_FrDrBlwDis 4;
BA_ "UserSigValidity" SG_ 34 L_ATCU_FrDrBlwDis 7;
BA_REL_ "GenSigTimeoutTime" BU_SG_REL_ L_HKBD SG_ 34 L_ATCU_FrDrBlwDis 1500;
BA_ "Version" SG_ 34 L_ATCU_FrDrBlwDis "23.08.13";
BA_ "GenSigSendType" SG_ 34 L_ATCU_FrPassBlwDis 4;
BA_ "UserSigValidity" SG_ 34 L_ATCU_FrPassBlwDis 7;
BA_REL_ "GenSigTimeoutTime" BU_SG_REL_ L_HKBD SG_ 34 L_ATCU_FrPassBlwDis 1500;
BA_ "Version" SG_ 34 L_ATCU_FrPassBlwDis "23.08.13";
BA_ "GenSigSendType" SG_ 34 L_ATCU_DrAutoDis 4;
BA_ "UserSigValidity" SG_ 34 L_ATCU_DrAutoDis 7;
BA_REL_ "GenSigTimeoutTime" BU_SG_REL_ L_HKBD SG_ 34 L_ATCU_DrAutoDis 1500;
BA_ "Version" SG_ 34 L_ATCU_DrAutoDis "23.08.13";
BA_ "GenSigSendType" SG_ 34 L_ATCU_PassAutoDis 4;
BA_ "UserSigValidity" SG_ 34 L_ATCU_PassAutoDis 7;
BA_REL_ "GenSigTimeoutTime" BU_SG_REL_ L_HKBD SG_ 34 L_ATCU_PassAutoDis 1500;
BA_ "Version" SG_ 34 L_ATCU_PassAutoDis "23.08.13";
BA_ "GenSigSendType" SG_ 34 L_ATCU_DrMultiAutoBlwDis 4;
BA_ "UserSigValidity" SG_ 34 L_ATCU_DrMultiAutoBlwDis 7;
BA_REL_ "GenSigTimeoutTime" BU_SG_REL_ L_HKBD SG_ 34 L_ATCU_DrMultiAutoBlwDis 1500;
BA_ "Version" SG_ 34 L_ATCU_DrMultiAutoBlwDis "23.08.13";
BA_ "GenSigSendType" SG_ 34 L_ATCU_PassMultiAutoBlwDis 4;
BA_ "UserSigValidity" SG_ 34 L_ATCU_PassMultiAutoBlwDis 7;
BA_REL_ "GenSigTimeoutTime" BU_SG_REL_ L_HKBD SG_ 34 L_ATCU_PassMultiAutoBlwDis 1500;
BA_ "Version" SG_ 34 L_ATCU_PassMultiAutoBlwDis "23.08.13";
BA_ "GenSigSendType" SG_ 34 L_ATCU_AcDis 4;
BA_ "UserSigValidity" SG_ 34 L_ATCU_AcDis 7;
BA_REL_ "GenSigTimeoutTime" BU_SG_REL_ L_HKBD SG_ 34 L_ATCU_AcDis 1500;
BA_ "Version" SG_ 34 L_ATCU_AcDis "23.08.13";
BA_ "GenSigSendType" SG_ 34 L_ATCU_IntakeDis 4;
BA_ "UserSigValidity" SG_ 34 L_ATCU_IntakeDis 7;
BA_REL_ "GenSigTimeoutTime" BU_SG_REL_ L_HKBD SG_ 34 L_ATCU_IntakeDis 1500;
BA_ "Version" SG_ 34 L_ATCU_IntakeDis "23.11.06";
BA_ "GenSigSendType" SG_ 34 L_ATCU_SyncDis 4;
BA_ "UserSigValidity" SG_ 34 L_ATCU_SyncDis 7;
BA_REL_ "GenSigTimeoutTime" BU_SG_REL_ L_HKBD SG_ 34 L_ATCU_SyncDis 1500;
BA_ "Version" SG_ 34 L_ATCU_SyncDis "23.08.13";
BA_ "GenSigSendType" SG_ 34 L_ATCU_FrDefDis 4;
BA_ "UserSigValidity" SG_ 34 L_ATCU_FrDefDis 7;
BA_REL_ "GenSigTimeoutTime" BU_SG_REL_ L_HKBD SG_ 34 L_ATCU_FrDefDis 1500;
BA_ "Version" SG_ 34 L_ATCU_FrDefDis "23.08.13";
BA_ "Description" SG_ 34 L_ATCU_PassTempCDis "This signal indicates Outside Temperature (¢µ)

(Use for display only)";
BA_ "GenSigSendType" SG_ 34 L_ATCU_PassTempCDis 4;
BA_ "UserSigValidity" SG_ 34 L_ATCU_PassTempCDis 7;
BA_REL_ "GenSigTimeoutTime" BU_SG_REL_ L_HKBD SG_ 34 L_ATCU_PassTempCDis 1500;
BA_ "Version" SG_ 34 L_ATCU_PassTempCDis "23.08.13";
BA_ "GenMsgSendType" BO_ 35 0;
BA_ "GenSigSendType" SG_ 35 L_ATCU_DrOnlyDis 4;
BA_ "UserSigValidity" SG_ 35 L_ATCU_DrOnlyDis 7;
BA_REL_ "GenSigTimeoutTime" BU_SG_REL_ L_HKBD SG_ 35 L_ATCU_DrOnlyDis 1500;
BA_ "Version" SG_ 35 L_ATCU_DrOnlyDis "23.08.13";
BA_ "GenSigSendType" SG_ 35 L_ATCU_SmrtVntDis 4;
BA_ "UserSigValidity" SG_ 35 L_ATCU_SmrtVntDis 7;
BA_REL_ "GenSigTimeoutTime" BU_SG_REL_ L_HKBD SG_ 35 L_ATCU_SmrtVntDis 1500;
BA_ "Version" SG_ 35 L_ATCU_SmrtVntDis "23.08.13";
BA_ "GenSigSendType" SG_ 35 L_ATCU_FrWndShldHtInd 4;
BA_ "UserSigValidity" SG_ 35 L_ATCU_FrWndShldHtInd 7;
BA_REL_ "GenSigTimeoutTime" BU_SG_REL_ L_HKBD SG_ 35 L_ATCU_FrWndShldHtInd 1500;
BA_ "Version" SG_ 35 L_ATCU_FrWndShldHtInd "23.08.13";
BA_ "GenSigSendType" SG_ 35 L_ATCU_IncarMtrOnReq 4;
BA_ "UserSigValidity" SG_ 35 L_ATCU_IncarMtrOnReq 7;
BA_REL_ "GenSigTimeoutTime" BU_SG_REL_ L_HKBD SG_ 35 L_ATCU_IncarMtrOnReq 1500;
BA_ "Version" SG_ 35 L_ATCU_IncarMtrOnReq "23.11.06";
BA_ "Description" SG_ 35 L_ATCU_LanguageInfo "This signal indicates System Language information for Font display";
BA_ "GenSigSendType" SG_ 35 L_ATCU_LanguageInfo 4;
BA_ "GenSigStartValue" SG_ 35 L_ATCU_LanguageInfo 255;
BA_ "UserSigValidity" SG_ 35 L_ATCU_LanguageInfo 7;
BA_REL_ "GenSigTimeoutTime" BU_SG_REL_ L_HKBD SG_ 35 L_ATCU_LanguageInfo 1500;
BA_ "Version" SG_ 35 L_ATCU_LanguageInfo "24.01.00";
BA_ "GenSigSendType" SG_ 35 L_ATCU_RrDefInd 4;
BA_ "UserSigValidity" SG_ 35 L_ATCU_RrDefInd 7;
BA_REL_ "GenSigTimeoutTime" BU_SG_REL_ L_HKBD SG_ 35 L_ATCU_RrDefInd 1500;
BA_ "Version" SG_ 35 L_ATCU_RrDefInd "23.08.13";
BA_ "GenSigSendType" SG_ 35 L_ATCU_AfterBlowDisplay 4;
BA_ "UserSigValidity" SG_ 35 L_ATCU_AfterBlowDisplay 7;
BA_REL_ "GenSigTimeoutTime" BU_SG_REL_ L_HKBD SG_ 35 L_ATCU_AfterBlowDisplay 1500;
BA_ "Version" SG_ 35 L_ATCU_AfterBlowDisplay "23.11.09";
BA_ "Description" SG_ 35 L_ATCU_SchdldVentDisplay "Operate Blower based on set time and date by user for better cabin room ventilation.";
BA_ "GenSigSendType" SG_ 35 L_ATCU_SchdldVentDisplay 4;
BA_ "UserSigValidity" SG_ 35 L_ATCU_SchdldVentDisplay 7;
BA_REL_ "GenSigTimeoutTime" BU_SG_REL_ L_HKBD SG_ 35 L_ATCU_SchdldVentDisplay 1500;
BA_ "Version" SG_ 35 L_ATCU_SchdldVentDisplay "24.01.00";
BA_ "GenSigSendType" SG_ 35 L_ATCU_FLStHeatSwHInd 4;
BA_ "UserSigValidity" SG_ 35 L_ATCU_FLStHeatSwHInd 7;
BA_REL_ "GenSigTimeoutTime" BU_SG_REL_ L_HKBD SG_ 35 L_ATCU_FLStHeatSwHInd 1500;
BA_ "Version" SG_ 35 L_ATCU_FLStHeatSwHInd "23.08.13";
BA_ "GenSigSendType" SG_ 35 L_ATCU_FLStHeatSwMInd 4;
BA_ "UserSigValidity" SG_ 35 L_ATCU_FLStHeatSwMInd 7;
BA_REL_ "GenSigTimeoutTime" BU_SG_REL_ L_HKBD SG_ 35 L_ATCU_FLStHeatSwMInd 1500;
BA_ "Version" SG_ 35 L_ATCU_FLStHeatSwMInd "23.08.13";
BA_ "GenSigSendType" SG_ 35 L_ATCU_ADSBlinkDis 4;
BA_ "UserSigValidity" SG_ 35 L_ATCU_ADSBlinkDis 7;
BA_REL_ "GenSigTimeoutTime" BU_SG_REL_ L_HKBD SG_ 35 L_ATCU_ADSBlinkDis 1500;
BA_ "Version" SG_ 35 L_ATCU_ADSBlinkDis "23.08.13";
BA_ "GenSigSendType" SG_ 35 L_ATCU_FLStHeatSwLInd 4;
BA_ "UserSigValidity" SG_ 35 L_ATCU_FLStHeatSwLInd 7;
BA_REL_ "GenSigTimeoutTime" BU_SG_REL_ L_HKBD SG_ 35 L_ATCU_FLStHeatSwLInd 1500;
BA_ "Version" SG_ 35 L_ATCU_FLStHeatSwLInd "23.08.13";
BA_ "GenSigSendType" SG_ 35 L_ATCU_FLStVntSwHInd 4;
BA_ "UserSigValidity" SG_ 35 L_ATCU_FLStVntSwHInd 7;
BA_REL_ "GenSigTimeoutTime" BU_SG_REL_ L_HKBD SG_ 35 L_ATCU_FLStVntSwHInd 1500;
BA_ "Version" SG_ 35 L_ATCU_FLStVntSwHInd "23.08.13";
BA_ "GenSigSendType" SG_ 35 L_ATCU_FLStVntSwMInd 4;
BA_ "UserSigValidity" SG_ 35 L_ATCU_FLStVntSwMInd 7;
BA_REL_ "GenSigTimeoutTime" BU_SG_REL_ L_HKBD SG_ 35 L_ATCU_FLStVntSwMInd 1500;
BA_ "Version" SG_ 35 L_ATCU_FLStVntSwMInd "23.08.13";
BA_ "GenSigSendType" SG_ 35 L_ATCU_FLStVntSwLInd 4;
BA_ "UserSigValidity" SG_ 35 L_ATCU_FLStVntSwLInd 7;
BA_REL_ "GenSigTimeoutTime" BU_SG_REL_ L_HKBD SG_ 35 L_ATCU_FLStVntSwLInd 1500;
BA_ "Version" SG_ 35 L_ATCU_FLStVntSwLInd "23.08.13";
BA_ "GenSigSendType" SG_ 35 L_ATCU_FRStHeatSwHInd 4;
BA_ "UserSigValidity" SG_ 35 L_ATCU_FRStHeatSwHInd 7;
BA_REL_ "GenSigTimeoutTime" BU_SG_REL_ L_HKBD SG_ 35 L_ATCU_FRStHeatSwHInd 1500;
BA_ "Version" SG_ 35 L_ATCU_FRStHeatSwHInd "23.08.13";
BA_ "GenSigSendType" SG_ 35 L_ATCU_FRStHeatSwMInd 4;
BA_ "UserSigValidity" SG_ 35 L_ATCU_FRStHeatSwMInd 7;
BA_REL_ "GenSigTimeoutTime" BU_SG_REL_ L_HKBD SG_ 35 L_ATCU_FRStHeatSwMInd 1500;
BA_ "Version" SG_ 35 L_ATCU_FRStHeatSwMInd "23.08.13";
BA_ "GenSigSendType" SG_ 35 L_ATCU_FRStHeatSwLInd 4;
BA_ "UserSigValidity" SG_ 35 L_ATCU_FRStHeatSwLInd 7;
BA_REL_ "GenSigTimeoutTime" BU_SG_REL_ L_HKBD SG_ 35 L_ATCU_FRStHeatSwLInd 1500;
BA_ "Version" SG_ 35 L_ATCU_FRStHeatSwLInd "23.08.13";
BA_ "GenSigSendType" SG_ 35 L_ATCU_FRStVntSwHInd 4;
BA_ "UserSigValidity" SG_ 35 L_ATCU_FRStVntSwHInd 7;
BA_REL_ "GenSigTimeoutTime" BU_SG_REL_ L_HKBD SG_ 35 L_ATCU_FRStVntSwHInd 1500;
BA_ "Version" SG_ 35 L_ATCU_FRStVntSwHInd "23.08.13";
BA_ "GenSigSendType" SG_ 35 L_ATCU_FRStVntSwMInd 4;
BA_ "UserSigValidity" SG_ 35 L_ATCU_FRStVntSwMInd 7;
BA_REL_ "GenSigTimeoutTime" BU_SG_REL_ L_HKBD SG_ 35 L_ATCU_FRStVntSwMInd 1500;
BA_ "Version" SG_ 35 L_ATCU_FRStVntSwMInd "23.08.13";
BA_ "GenSigSendType" SG_ 35 L_ATCU_FRStVntSwLInd 4;
BA_ "UserSigValidity" SG_ 35 L_ATCU_FRStVntSwLInd 7;
BA_REL_ "GenSigTimeoutTime" BU_SG_REL_ L_HKBD SG_ 35 L_ATCU_FRStVntSwLInd 1500;
BA_ "Version" SG_ 35 L_ATCU_FRStVntSwLInd "23.08.13";
BA_ "Description" SG_ 35 L_ATCU_StrWhlHeatInd "This signal indicates the status of Steering Wheel Heater";
BA_ "GenSigSendType" SG_ 35 L_ATCU_StrWhlHeatInd 4;
BA_ "UserSigValidity" SG_ 35 L_ATCU_StrWhlHeatInd 7;
BA_REL_ "GenSigTimeoutTime" BU_SG_REL_ L_HKBD SG_ 35 L_ATCU_StrWhlHeatInd 1500;
BA_ "Version" SG_ 35 L_ATCU_StrWhlHeatInd "23.08.13";
BA_ "Description" SG_ 35 L_ATCU_RhstaLvlSta "This signal is used for a rheostat level of CLUSTER from 1 to 21 level (21 level:Detent) for a Unified Illumination System



¡Ø Start Value:Current Value";
BA_ "GenSigSendType" SG_ 35 L_ATCU_RhstaLvlSta 4;
BA_ "UserSigValidity" SG_ 35 L_ATCU_RhstaLvlSta 7;
BA_REL_ "GenSigTimeoutTime" BU_SG_REL_ L_2HKBD SG_ 35 L_ATCU_RhstaLvlSta 1500;
BA_REL_ "GenSigTimeoutTime" BU_SG_REL_ L_EVNT SG_ 35 L_ATCU_RhstaLvlSta 1500;
BA_REL_ "GenSigTimeoutTime" BU_SG_REL_ L_HKBD SG_ 35 L_ATCU_RhstaLvlSta 1500;
BA_ "Version" SG_ 35 L_ATCU_RhstaLvlSta "24.08.00";
BA_ "GenSigSendType" SG_ 35 L_ATCU_IntTailOnOff 4;
BA_ "UserSigValidity" SG_ 35 L_ATCU_IntTailOnOff 7;
BA_REL_ "GenSigTimeoutTime" BU_SG_REL_ L_2HKBD SG_ 35 L_ATCU_IntTailOnOff 1500;
BA_REL_ "GenSigTimeoutTime" BU_SG_REL_ L_HKBD SG_ 35 L_ATCU_IntTailOnOff 1500;
BA_ "Version" SG_ 35 L_ATCU_IntTailOnOff "23.08.13";
BA_ "Description" SG_ 35 L_ATCU_AutoLightSta "This signal indicates autolight sensor output";
BA_ "GenSigSendType" SG_ 35 L_ATCU_AutoLightSta 4;
BA_ "UserSigValidity" SG_ 35 L_ATCU_AutoLightSta 7;
BA_REL_ "GenSigTimeoutTime" BU_SG_REL_ L_HKBD SG_ 35 L_ATCU_AutoLightSta 1500;
BA_ "Version" SG_ 35 L_ATCU_AutoLightSta "23.08.13";
BA_ "GenSigSendType" SG_ 35 L_ATCU_FrBckLightSta 4;
BA_ "UserSigValidity" SG_ 35 L_ATCU_FrBckLightSta 7;
BA_REL_ "GenSigTimeoutTime" BU_SG_REL_ L_HKBD SG_ 35 L_ATCU_FrBckLightSta 1500;
BA_ "Version" SG_ 35 L_ATCU_FrBckLightSta "23.08.13";
BA_ "GenSigSendType" SG_ 35 L_ATCU_DisplayTheme 4;
BA_ "UserSigValidity" SG_ 35 L_ATCU_DisplayTheme 7;
BA_REL_ "GenSigTimeoutTime" BU_SG_REL_ L_HKBD SG_ 35 L_ATCU_DisplayTheme 1500;
BA_ "Version" SG_ 35 L_ATCU_DisplayTheme "23.08.13";
BA_ "GenSigSendType" SG_ 35 L_ATCU_GUIBlankDis 4;
BA_ "UserSigValidity" SG_ 35 L_ATCU_GUIBlankDis 7;
BA_REL_ "GenSigTimeoutTime" BU_SG_REL_ L_HKBD SG_ 35 L_ATCU_GUIBlankDis 1500;
BA_ "Version" SG_ 35 L_ATCU_GUIBlankDis "23.08.13";
BA_ "GenSigSendType" SG_ 35 L_ATCU_HptIntnstySet 4;
BA_ "UserSigValidity" SG_ 35 L_ATCU_HptIntnstySet 7;
BA_REL_ "GenSigTimeoutTime" BU_SG_REL_ L_HKBD SG_ 35 L_ATCU_HptIntnstySet 1500;
BA_ "Version" SG_ 35 L_ATCU_HptIntnstySet "23.11.06";
BA_ "Description" SG_ 35 L_ATCU_TlltLmpDis "This signal means information regarding Occupant status.

0) 00Xb:X position means PAB OFF Lamp indication. When this bit set as 1 PAB OFF lamp turns ON. 

    0Y0b:Y position means PAB ON Lamp indication. When this bit set as 1 PAB ON lamp turns ON.



1) Default value:0x2 (PAB ON Lamp on, PAB OFF Lamp off,)

2) Default value Transmit condition

    - When the input condition is not determined.

    - When the input condition is not supported.";
BA_ "GenSigSendType" SG_ 35 L_ATCU_TlltLmpDis 4;
BA_ "UserSigValidity" SG_ 35 L_ATCU_TlltLmpDis 7;
BA_REL_ "GenSigTimeoutTime" BU_SG_REL_ L_HKBD SG_ 35 L_ATCU_TlltLmpDis 1500;
BA_ "Version" SG_ 35 L_ATCU_TlltLmpDis "23.08.13";
BA_ "GenSigSendType" SG_ 35 L_ATCU_AvTailOnOff 4;
BA_ "UserSigValidity" SG_ 35 L_ATCU_AvTailOnOff 7;
BA_REL_ "GenSigTimeoutTime" BU_SG_REL_ L_HKBD SG_ 35 L_ATCU_AvTailOnOff 1500;
BA_ "Version" SG_ 35 L_ATCU_AvTailOnOff "23.08.13";
BA_ "Description" SG_ 35 L_ATCU_SchdldClimateDisplay "Operate Climate system based on set time and date by user in EV vehicle.";
BA_ "GenSigSendType" SG_ 35 L_ATCU_SchdldClimateDisplay 4;
BA_ "UserSigValidity" SG_ 35 L_ATCU_SchdldClimateDisplay 7;
BA_REL_ "GenSigTimeoutTime" BU_SG_REL_ L_HKBD SG_ 35 L_ATCU_SchdldClimateDisplay 1500;
BA_ "Version" SG_ 35 L_ATCU_SchdldClimateDisplay "24.01.00";
BA_ "GenSigSendType" SG_ 35 L_ATCU_AirClnDis 4;
BA_ "UserSigValidity" SG_ 35 L_ATCU_AirClnDis 7;
BA_REL_ "GenSigTimeoutTime" BU_SG_REL_ L_HKBD SG_ 35 L_ATCU_AirClnDis 1500;
BA_ "Version" SG_ 35 L_ATCU_AirClnDis "23.08.13";
BA_ "GenSigSendType" SG_ 35 L_ATCU_CO2WrngDis 4;
BA_ "UserSigValidity" SG_ 35 L_ATCU_CO2WrngDis 7;
BA_REL_ "GenSigTimeoutTime" BU_SG_REL_ L_HKBD SG_ 35 L_ATCU_CO2WrngDis 1500;
BA_ "Version" SG_ 35 L_ATCU_CO2WrngDis "23.08.13";
BA_ "GenMsgSendType" BO_ 36 0;
BA_ "GenSigSendType" SG_ 36 L_ATCU_ArClnIntroEvt 4;
BA_ "UserSigValidity" SG_ 36 L_ATCU_ArClnIntroEvt 7;
BA_REL_ "GenSigTimeoutTime" BU_SG_REL_ L_HKBD SG_ 36 L_ATCU_ArClnIntroEvt 1500;
BA_ "Version" SG_ 36 L_ATCU_ArClnIntroEvt "23.08.13";
BA_ "Description" SG_ 36 L_ATCU_ArClnSmblClr "This signal indicates the information about Color of AirCleaning Symbol displaying in the AVN";
BA_ "GenSigSendType" SG_ 36 L_ATCU_ArClnSmblClr 4;
BA_ "UserSigValidity" SG_ 36 L_ATCU_ArClnSmblClr 7;
BA_REL_ "GenSigTimeoutTime" BU_SG_REL_ L_HKBD SG_ 36 L_ATCU_ArClnSmblClr 1500;
BA_ "Version" SG_ 36 L_ATCU_ArClnSmblClr "23.08.13";
BA_ "GenSigSendType" SG_ 36 L_ATCU_DustLevelDis 4;
BA_ "UserSigValidity" SG_ 36 L_ATCU_DustLevelDis 7;
BA_REL_ "GenSigTimeoutTime" BU_SG_REL_ L_HKBD SG_ 36 L_ATCU_DustLevelDis 1500;
BA_ "Version" SG_ 36 L_ATCU_DustLevelDis "23.08.13";
BA_ "GenSigSendType" SG_ 36 L_ATCU_DustBarDisOff 4;
BA_ "UserSigValidity" SG_ 36 L_ATCU_DustBarDisOff 7;
BA_REL_ "GenSigTimeoutTime" BU_SG_REL_ L_HKBD SG_ 36 L_ATCU_DustBarDisOff 1500;
BA_ "Version" SG_ 36 L_ATCU_DustBarDisOff "23.08.13";
BA_ "GenSigSendType" SG_ 36 L_ATCU_DustSnrStepDis 4;
BA_ "UserSigValidity" SG_ 36 L_ATCU_DustSnrStepDis 7;
BA_REL_ "GenSigTimeoutTime" BU_SG_REL_ L_HKBD SG_ 36 L_ATCU_DustSnrStepDis 1500;
BA_ "Version" SG_ 36 L_ATCU_DustSnrStepDis "23.08.13";
BA_ "NmNode" BU_ L_PCM 0;
BA_ "GenSigSendType" SG_ 36 L_ATCU_FragStrhDis 4;
BA_ "UserSigValidity" SG_ 36 L_ATCU_FragStrhDis 7;
BA_REL_ "GenSigTimeoutTime" BU_SG_REL_ L_HKBD SG_ 36 L_ATCU_FragStrhDis 1500;
BA_REL_ "GenSigTimeoutTime" BU_SG_REL_ L_PCM SG_ 36 L_ATCU_FragStrhDis 1500;
BA_ "Version" SG_ 36 L_ATCU_FragStrhDis "23.08.13";
BA_ "Description" SG_ 36 L_ATCU_FragKindDis "This singal indicates display value of Fragnance kind";
BA_ "GenSigSendType" SG_ 36 L_ATCU_FragKindDis 4;
BA_ "UserSigValidity" SG_ 36 L_ATCU_FragKindDis 7;
BA_REL_ "GenSigTimeoutTime" BU_SG_REL_ L_HKBD SG_ 36 L_ATCU_FragKindDis 1500;
BA_REL_ "GenSigTimeoutTime" BU_SG_REL_ L_PCM SG_ 36 L_ATCU_FragKindDis 1500;
BA_ "Version" SG_ 36 L_ATCU_FragKindDis "24.05.08";
BA_ "Description" SG_ 36 L_ATCU_Frag1Inform "This signal indicates Information of Fragrance 1";
BA_ "GenSigSendType" SG_ 36 L_ATCU_Frag1Inform 4;
BA_ "UserSigValidity" SG_ 36 L_ATCU_Frag1Inform 7;
BA_REL_ "GenSigTimeoutTime" BU_SG_REL_ L_HKBD SG_ 36 L_ATCU_Frag1Inform 1500;
BA_REL_ "GenSigTimeoutTime" BU_SG_REL_ L_PCM SG_ 36 L_ATCU_Frag1Inform 1500;
BA_ "Version" SG_ 36 L_ATCU_Frag1Inform "23.08.13";
BA_ "Description" SG_ 36 L_ATCU_Frag2Inform "This signal indicates Information of Fragrance 2";
BA_ "GenSigSendType" SG_ 36 L_ATCU_Frag2Inform 4;
BA_ "UserSigValidity" SG_ 36 L_ATCU_Frag2Inform 7;
BA_REL_ "GenSigTimeoutTime" BU_SG_REL_ L_HKBD SG_ 36 L_ATCU_Frag2Inform 1500;
BA_REL_ "GenSigTimeoutTime" BU_SG_REL_ L_PCM SG_ 36 L_ATCU_Frag2Inform 1500;
BA_ "Version" SG_ 36 L_ATCU_Frag2Inform "23.08.13";
BA_ "Description" SG_ 36 L_ATCU_Frag1RemainDisp "This signal indicates Remain Display of Ragrnace No.1";
BA_ "GenSigSendType" SG_ 36 L_ATCU_Frag1RemainDisp 4;
BA_ "UserSigValidity" SG_ 36 L_ATCU_Frag1RemainDisp 7;
BA_REL_ "GenSigTimeoutTime" BU_SG_REL_ L_HKBD SG_ 36 L_ATCU_Frag1RemainDisp 1500;
BA_REL_ "GenSigTimeoutTime" BU_SG_REL_ L_PCM SG_ 36 L_ATCU_Frag1RemainDisp 1500;
BA_ "Version" SG_ 36 L_ATCU_Frag1RemainDisp "23.08.13";
BA_ "Description" SG_ 36 L_ATCU_Frag2RemainDisp "This signal indicates Remain Display of Ragrnace No.2";
BA_ "GenSigSendType" SG_ 36 L_ATCU_Frag2RemainDisp 4;
BA_ "UserSigValidity" SG_ 36 L_ATCU_Frag2RemainDisp 7;
BA_REL_ "GenSigTimeoutTime" BU_SG_REL_ L_2HKBD SG_ 36 L_ATCU_Frag2RemainDisp 1500;
BA_REL_ "GenSigTimeoutTime" BU_SG_REL_ L_HKBD SG_ 36 L_ATCU_Frag2RemainDisp 1500;
BA_ "Version" SG_ 36 L_ATCU_Frag2RemainDisp "23.08.13";
BA_ "Description" SG_ 36 L_ATCU_ArClnSmblTyp "This signal indicate the feature of Air Cleaning Symbol displaying in the AVN";
BA_ "GenSigSendType" SG_ 36 L_ATCU_ArClnSmblTyp 4;
BA_ "UserSigValidity" SG_ 36 L_ATCU_ArClnSmblTyp 7;
BA_REL_ "GenSigTimeoutTime" BU_SG_REL_ L_HKBD SG_ 36 L_ATCU_ArClnSmblTyp 1500;
BA_ "Version" SG_ 36 L_ATCU_ArClnSmblTyp "23.08.13";
BA_ "Description" SG_ 36 L_ATCU_FrtBlwMaxLvlVaild "This signal indicates the maximum step of Front Blower according to multi auto steps.";
BA_ "GenSigSendType" SG_ 36 L_ATCU_FrtBlwMaxLvlVaild 4;
BA_ "UserSigValidity" SG_ 36 L_ATCU_FrtBlwMaxLvlVaild 7;
BA_REL_ "GenSigTimeoutTime" BU_SG_REL_ L_2HKBD SG_ 36 L_ATCU_FrtBlwMaxLvlVaild 1500;
BA_REL_ "GenSigTimeoutTime" BU_SG_REL_ L_HKBD SG_ 36 L_ATCU_FrtBlwMaxLvlVaild 1500;
BA_ "Version" SG_ 36 L_ATCU_FrtBlwMaxLvlVaild "23.08.13";
BA_ "GenSigSendType" SG_ 36 L_ATCU_OpSta 4;
BA_ "UserSigValidity" SG_ 36 L_ATCU_OpSta 7;
BA_REL_ "GenSigTimeoutTime" BU_SG_REL_ L_EVNT SG_ 36 L_ATCU_OpSta 1500;
BA_REL_ "GenSigTimeoutTime" BU_SG_REL_ L_HKBD SG_ 36 L_ATCU_OpSta 1500;
BA_ "Version" SG_ 36 L_ATCU_OpSta "23.08.13";
BA_ "Description" SG_ 36 L_ATCU_TempDispUnit "This signal is unit of Temperature display";
BA_ "GenSigSendType" SG_ 36 L_ATCU_TempDispUnit 4;
BA_ "UserSigValidity" SG_ 36 L_ATCU_TempDispUnit 7;
BA_REL_ "GenSigTimeoutTime" BU_SG_REL_ L_2HKBD SG_ 36 L_ATCU_TempDispUnit 1500;
BA_REL_ "GenSigTimeoutTime" BU_SG_REL_ L_HKBD SG_ 36 L_ATCU_TempDispUnit 1500;
BA_ "Version" SG_ 36 L_ATCU_TempDispUnit "24.05.08";
BA_ "GenSigSendType" SG_ 36 L_ATCU_DrvAUTOStep 4;
BA_ "UserSigValidity" SG_ 36 L_ATCU_DrvAUTOStep 7;
BA_REL_ "GenSigTimeoutTime" BU_SG_REL_ L_HKBD SG_ 36 L_ATCU_DrvAUTOStep 1500;
BA_ "Version" SG_ 36 L_ATCU_DrvAUTOStep "23.08.13";
BA_ "Description" SG_ 36 L_ATCU_DiagCodeDis "0x1~0x3FE:PHY=(HEX*1.0-1.0)";
BA_ "GenSigSendType" SG_ 36 L_ATCU_DiagCodeDis 4;
BA_ "UserSigValidity" SG_ 36 L_ATCU_DiagCodeDis 7;
BA_REL_ "GenSigTimeoutTime" BU_SG_REL_ L_HKBD SG_ 36 L_ATCU_DiagCodeDis 1500;
BA_ "Version" SG_ 36 L_ATCU_DiagCodeDis "23.08.13";
BA_ "GenMsgSendType" BO_ 37 0;
BA_ "Description" SG_ 37 L_ATCU_RrOpSta "ATCU_RearOperationStatus";
BA_ "GenSigSendType" SG_ 37 L_ATCU_RrOpSta 4;
BA_ "UserSigValidity" SG_ 37 L_ATCU_RrOpSta 7;
BA_REL_ "GenSigTimeoutTime" BU_SG_REL_ L_2HKBD SG_ 37 L_ATCU_RrOpSta 1500;
BA_REL_ "GenSigTimeoutTime" BU_SG_REL_ L_HKBD SG_ 37 L_ATCU_RrOpSta 1500;
BA_ "Version" SG_ 37 L_ATCU_RrOpSta "24.08.00";
BA_ "Description" SG_ 37 L_ATCU_RrDrvTempFDis "This signal indicates Outside Temperature (¢µ)

(Use for display only)";
BA_ "GenSigSendType" SG_ 37 L_ATCU_RrDrvTempFDis 4;
BA_ "UserSigValidity" SG_ 37 L_ATCU_RrDrvTempFDis 7;
BA_REL_ "GenSigTimeoutTime" BU_SG_REL_ L_2HKBD SG_ 37 L_ATCU_RrDrvTempFDis 1500;
BA_REL_ "GenSigTimeoutTime" BU_SG_REL_ L_HKBD SG_ 37 L_ATCU_RrDrvTempFDis 1500;
BA_ "Version" SG_ 37 L_ATCU_RrDrvTempFDis "23.08.13";
BA_ "Description" SG_ 37 L_ATCU_RrDrvModDis "ATCU_RearDriverModeDisplay";
BA_ "GenSigSendType" SG_ 37 L_ATCU_RrDrvModDis 4;
BA_ "UserSigValidity" SG_ 37 L_ATCU_RrDrvModDis 7;
BA_REL_ "GenSigTimeoutTime" BU_SG_REL_ L_2HKBD SG_ 37 L_ATCU_RrDrvModDis 1500;
BA_REL_ "GenSigTimeoutTime" BU_SG_REL_ L_EVNT SG_ 37 L_ATCU_RrDrvModDis 1500;
BA_REL_ "GenSigTimeoutTime" BU_SG_REL_ L_HKBD SG_ 37 L_ATCU_RrDrvModDis 1500;
BA_ "Version" SG_ 37 L_ATCU_RrDrvModDis "24.05.08";
BA_ "GenSigSendType" SG_ 37 L_ATCU_RrDrvBlwDis 4;
BA_ "UserSigValidity" SG_ 37 L_ATCU_RrDrvBlwDis 7;
BA_REL_ "GenSigTimeoutTime" BU_SG_REL_ L_2HKBD SG_ 37 L_ATCU_RrDrvBlwDis 1500;
BA_REL_ "GenSigTimeoutTime" BU_SG_REL_ L_HKBD SG_ 37 L_ATCU_RrDrvBlwDis 1500;
BA_ "Version" SG_ 37 L_ATCU_RrDrvBlwDis "23.08.13";
BA_ "GenSigSendType" SG_ 37 L_ATCU_RrDrvAutoDis 4;
BA_ "UserSigValidity" SG_ 37 L_ATCU_RrDrvAutoDis 7;
BA_REL_ "GenSigTimeoutTime" BU_SG_REL_ L_2HKBD SG_ 37 L_ATCU_RrDrvAutoDis 1500;
BA_REL_ "GenSigTimeoutTime" BU_SG_REL_ L_HKBD SG_ 37 L_ATCU_RrDrvAutoDis 1500;
BA_ "Version" SG_ 37 L_ATCU_RrDrvAutoDis "23.08.13";
BA_ "GenSigSendType" SG_ 37 L_ATCU_RrDrvMultiAutoBlwDis 4;
BA_ "UserSigValidity" SG_ 37 L_ATCU_RrDrvMultiAutoBlwDis 7;
BA_REL_ "GenSigTimeoutTime" BU_SG_REL_ L_2HKBD SG_ 37 L_ATCU_RrDrvMultiAutoBlwDis 1500;
BA_REL_ "GenSigTimeoutTime" BU_SG_REL_ L_HKBD SG_ 37 L_ATCU_RrDrvMultiAutoBlwDis 1500;
BA_ "Version" SG_ 37 L_ATCU_RrDrvMultiAutoBlwDis "23.08.13";
BA_ "Description" SG_ 37 L_ATCU_RrDrvTempCDis "This signal indicates Outside temperature (¡É).

(Use for display only)";
BA_ "GenSigSendType" SG_ 37 L_ATCU_RrDrvTempCDis 4;
BA_ "UserSigValidity" SG_ 37 L_ATCU_RrDrvTempCDis 7;
BA_REL_ "GenSigTimeoutTime" BU_SG_REL_ L_2HKBD SG_ 37 L_ATCU_RrDrvTempCDis 1500;
BA_REL_ "GenSigTimeoutTime" BU_SG_REL_ L_HKBD SG_ 37 L_ATCU_RrDrvTempCDis 1500;
BA_ "Version" SG_ 37 L_ATCU_RrDrvTempCDis "23.08.13";
BA_ "GenSigSendType" SG_ 37 L_ATCU_RrSyncDis 4;
BA_ "UserSigValidity" SG_ 37 L_ATCU_RrSyncDis 7;
BA_REL_ "GenSigTimeoutTime" BU_SG_REL_ L_2HKBD SG_ 37 L_ATCU_RrSyncDis 1500;
BA_REL_ "GenSigTimeoutTime" BU_SG_REL_ L_HKBD SG_ 37 L_ATCU_RrSyncDis 1500;
BA_ "Version" SG_ 37 L_ATCU_RrSyncDis "23.08.13";
BA_ "GenSigSendType" SG_ 37 L_ATCU_RrLcdBckLightSta 4;
BA_ "UserSigValidity" SG_ 37 L_ATCU_RrLcdBckLightSta 7;
BA_REL_ "GenSigTimeoutTime" BU_SG_REL_ L_2HKBD SG_ 37 L_ATCU_RrLcdBckLightSta 1500;
BA_REL_ "GenSigTimeoutTime" BU_SG_REL_ L_HKBD SG_ 37 L_ATCU_RrLcdBckLightSta 1500;
BA_ "Version" SG_ 37 L_ATCU_RrLcdBckLightSta "23.08.13";
BA_ "GenSigSendType" SG_ 37 L_ATCU_RrGUIBlankDis 4;
BA_ "UserSigValidity" SG_ 37 L_ATCU_RrGUIBlankDis 7;
BA_REL_ "GenSigTimeoutTime" BU_SG_REL_ L_2HKBD SG_ 37 L_ATCU_RrGUIBlankDis 1500;
BA_REL_ "GenSigTimeoutTime" BU_SG_REL_ L_HKBD SG_ 37 L_ATCU_RrGUIBlankDis 1500;
BA_ "Version" SG_ 37 L_ATCU_RrGUIBlankDis "23.08.13";
BA_ "GenSigSendType" SG_ 37 L_ATCU_RLStHeatSwHInd 4;
BA_ "UserSigValidity" SG_ 37 L_ATCU_RLStHeatSwHInd 7;
BA_REL_ "GenSigTimeoutTime" BU_SG_REL_ L_2HKBD SG_ 37 L_ATCU_RLStHeatSwHInd 1500;
BA_REL_ "GenSigTimeoutTime" BU_SG_REL_ L_HKBD SG_ 37 L_ATCU_RLStHeatSwHInd 1500;
BA_ "Version" SG_ 37 L_ATCU_RLStHeatSwHInd "23.08.13";
BA_ "GenSigSendType" SG_ 37 L_ATCU_RLStHeatSwMInd 4;
BA_ "UserSigValidity" SG_ 37 L_ATCU_RLStHeatSwMInd 7;
BA_REL_ "GenSigTimeoutTime" BU_SG_REL_ L_2HKBD SG_ 37 L_ATCU_RLStHeatSwMInd 1500;
BA_REL_ "GenSigTimeoutTime" BU_SG_REL_ L_HKBD SG_ 37 L_ATCU_RLStHeatSwMInd 1500;
BA_ "Version" SG_ 37 L_ATCU_RLStHeatSwMInd "23.08.13";
BA_ "GenSigSendType" SG_ 37 L_ATCU_RLStHeatSwLInd 4;
BA_ "UserSigValidity" SG_ 37 L_ATCU_RLStHeatSwLInd 7;
BA_REL_ "GenSigTimeoutTime" BU_SG_REL_ L_2HKBD SG_ 37 L_ATCU_RLStHeatSwLInd 1500;
BA_REL_ "GenSigTimeoutTime" BU_SG_REL_ L_HKBD SG_ 37 L_ATCU_RLStHeatSwLInd 1500;
BA_ "Version" SG_ 37 L_ATCU_RLStHeatSwLInd "23.08.13";
BA_ "GenSigSendType" SG_ 37 L_ATCU_RLStVntSwHInd 4;
BA_ "UserSigValidity" SG_ 37 L_ATCU_RLStVntSwHInd 7;
BA_REL_ "GenSigTimeoutTime" BU_SG_REL_ L_2HKBD SG_ 37 L_ATCU_RLStVntSwHInd 1500;
BA_REL_ "GenSigTimeoutTime" BU_SG_REL_ L_HKBD SG_ 37 L_ATCU_RLStVntSwHInd 1500;
BA_ "Version" SG_ 37 L_ATCU_RLStVntSwHInd "23.08.13";
BA_ "GenSigSendType" SG_ 37 L_ATCU_RLStVntSwMInd 4;
BA_ "UserSigValidity" SG_ 37 L_ATCU_RLStVntSwMInd 7;
BA_REL_ "GenSigTimeoutTime" BU_SG_REL_ L_2HKBD SG_ 37 L_ATCU_RLStVntSwMInd 1500;
BA_REL_ "GenSigTimeoutTime" BU_SG_REL_ L_HKBD SG_ 37 L_ATCU_RLStVntSwMInd 1500;
BA_ "Version" SG_ 37 L_ATCU_RLStVntSwMInd "23.08.13";
BA_ "GenSigSendType" SG_ 37 L_ATCU_RLStVntSwLInd 4;
BA_ "UserSigValidity" SG_ 37 L_ATCU_RLStVntSwLInd 7;
BA_REL_ "GenSigTimeoutTime" BU_SG_REL_ L_2HKBD SG_ 37 L_ATCU_RLStVntSwLInd 1500;
BA_REL_ "GenSigTimeoutTime" BU_SG_REL_ L_HKBD SG_ 37 L_ATCU_RLStVntSwLInd 1500;
BA_ "Version" SG_ 37 L_ATCU_RLStVntSwLInd "23.08.13";
BA_ "GenSigSendType" SG_ 37 L_ATCU_RRStHeatSwHInd 4;
BA_ "UserSigValidity" SG_ 37 L_ATCU_RRStHeatSwHInd 7;
BA_REL_ "GenSigTimeoutTime" BU_SG_REL_ L_2HKBD SG_ 37 L_ATCU_RRStHeatSwHInd 1500;
BA_REL_ "GenSigTimeoutTime" BU_SG_REL_ L_HKBD SG_ 37 L_ATCU_RRStHeatSwHInd 1500;
BA_ "Version" SG_ 37 L_ATCU_RRStHeatSwHInd "23.08.13";
BA_ "GenSigSendType" SG_ 37 L_ATCU_RRStHeatSwMInd 4;
BA_ "UserSigValidity" SG_ 37 L_ATCU_RRStHeatSwMInd 7;
BA_REL_ "GenSigTimeoutTime" BU_SG_REL_ L_2HKBD SG_ 37 L_ATCU_RRStHeatSwMInd 1500;
BA_REL_ "GenSigTimeoutTime" BU_SG_REL_ L_HKBD SG_ 37 L_ATCU_RRStHeatSwMInd 1500;
BA_ "Version" SG_ 37 L_ATCU_RRStHeatSwMInd "23.08.13";
BA_ "GenSigSendType" SG_ 37 L_ATCU_RRStHeatSwLInd 4;
BA_ "UserSigValidity" SG_ 37 L_ATCU_RRStHeatSwLInd 7;
BA_REL_ "GenSigTimeoutTime" BU_SG_REL_ L_2HKBD SG_ 37 L_ATCU_RRStHeatSwLInd 1500;
BA_REL_ "GenSigTimeoutTime" BU_SG_REL_ L_HKBD SG_ 37 L_ATCU_RRStHeatSwLInd 1500;
BA_ "Version" SG_ 37 L_ATCU_RRStHeatSwLInd "23.08.13";
BA_ "GenSigSendType" SG_ 37 L_ATCU_RRStVntSwHInd 4;
BA_ "UserSigValidity" SG_ 37 L_ATCU_RRStVntSwHInd 7;
BA_REL_ "GenSigTimeoutTime" BU_SG_REL_ L_2HKBD SG_ 37 L_ATCU_RRStVntSwHInd 1500;
BA_REL_ "GenSigTimeoutTime" BU_SG_REL_ L_HKBD SG_ 37 L_ATCU_RRStVntSwHInd 1500;
BA_ "Version" SG_ 37 L_ATCU_RRStVntSwHInd "23.08.13";
BA_ "GenSigSendType" SG_ 37 L_ATCU_RRStVntSwMInd 4;
BA_ "UserSigValidity" SG_ 37 L_ATCU_RRStVntSwMInd 7;
BA_REL_ "GenSigTimeoutTime" BU_SG_REL_ L_2HKBD SG_ 37 L_ATCU_RRStVntSwMInd 1500;
BA_REL_ "GenSigTimeoutTime" BU_SG_REL_ L_HKBD SG_ 37 L_ATCU_RRStVntSwMInd 1500;
BA_ "Version" SG_ 37 L_ATCU_RRStVntSwMInd "23.08.13";
BA_ "GenSigSendType" SG_ 37 L_ATCU_RRStVntSwLInd 4;
BA_ "UserSigValidity" SG_ 37 L_ATCU_RRStVntSwLInd 7;
BA_REL_ "GenSigTimeoutTime" BU_SG_REL_ L_2HKBD SG_ 37 L_ATCU_RRStVntSwLInd 1500;
BA_REL_ "GenSigTimeoutTime" BU_SG_REL_ L_HKBD SG_ 37 L_ATCU_RRStVntSwLInd 1500;
BA_ "Version" SG_ 37 L_ATCU_RRStVntSwLInd "23.08.13";
BA_ "GenSigSendType" SG_ 37 L_ATCU_RrMTCOpSta 4;
BA_ "UserSigValidity" SG_ 37 L_ATCU_RrMTCOpSta 7;
BA_REL_ "GenSigTimeoutTime" BU_SG_REL_ L_2HKBD SG_ 37 L_ATCU_RrMTCOpSta 1500;
BA_REL_ "GenSigTimeoutTime" BU_SG_REL_ L_HKBD SG_ 37 L_ATCU_RrMTCOpSta 1500;
BA_ "Version" SG_ 37 L_ATCU_RrMTCOpSta "23.08.13";
BA_ "GenSigSendType" SG_ 37 L_ATCU_RrMTCTempLvl 4;
BA_ "UserSigValidity" SG_ 37 L_ATCU_RrMTCTempLvl 7;
BA_REL_ "GenSigTimeoutTime" BU_SG_REL_ L_2HKBD SG_ 37 L_ATCU_RrMTCTempLvl 1500;
BA_REL_ "GenSigTimeoutTime" BU_SG_REL_ L_HKBD SG_ 37 L_ATCU_RrMTCTempLvl 1500;
BA_ "Version" SG_ 37 L_ATCU_RrMTCTempLvl "23.08.13";
BA_ "Description" SG_ 37 L_ATCU_RrPsModDis "ATCU_RearPassengerModeDisplay";
BA_ "GenSigSendType" SG_ 37 L_ATCU_RrPsModDis 4;
BA_ "UserSigValidity" SG_ 37 L_ATCU_RrPsModDis 7;
BA_REL_ "GenSigTimeoutTime" BU_SG_REL_ L_2HKBD SG_ 37 L_ATCU_RrPsModDis 1500;
BA_REL_ "GenSigTimeoutTime" BU_SG_REL_ L_EVNT SG_ 37 L_ATCU_RrPsModDis 1500;
BA_REL_ "GenSigTimeoutTime" BU_SG_REL_ L_HKBD SG_ 37 L_ATCU_RrPsModDis 1500;
BA_ "Version" SG_ 37 L_ATCU_RrPsModDis "24.05.08";
BA_ "GenSigSendType" SG_ 37 L_ATCU_RrLockDis 4;
BA_ "UserSigValidity" SG_ 37 L_ATCU_RrLockDis 7;
BA_REL_ "GenSigTimeoutTime" BU_SG_REL_ L_2HKBD SG_ 37 L_ATCU_RrLockDis 1500;
BA_REL_ "GenSigTimeoutTime" BU_SG_REL_ L_HKBD SG_ 37 L_ATCU_RrLockDis 1500;
BA_ "Version" SG_ 37 L_ATCU_RrLockDis "23.08.13";
BA_ "GenSigSendType" SG_ 37 L_ATCU_RrDrvAutoStep 4;
BA_ "UserSigValidity" SG_ 37 L_ATCU_RrDrvAutoStep 7;
BA_REL_ "GenSigTimeoutTime" BU_SG_REL_ L_2HKBD SG_ 37 L_ATCU_RrDrvAutoStep 1500;
BA_REL_ "GenSigTimeoutTime" BU_SG_REL_ L_HKBD SG_ 37 L_ATCU_RrDrvAutoStep 1500;
BA_ "Version" SG_ 37 L_ATCU_RrDrvAutoStep "23.08.13";
BA_ "GenMsgSendType" BO_ 38 0;
BA_ "Description" SG_ 38 L_ATCU_3rdRrTempCDis "This signal indicates Outside temperature (¡É).

(Use for display only)";
BA_ "GenSigSendType" SG_ 38 L_ATCU_3rdRrTempCDis 4;
BA_ "UserSigValidity" SG_ 38 L_ATCU_3rdRrTempCDis 7;
BA_REL_ "GenSigTimeoutTime" BU_SG_REL_ L_3HKBD SG_ 38 L_ATCU_3rdRrTempCDis 1500;
BA_REL_ "GenSigTimeoutTime" BU_SG_REL_ L_HKBD SG_ 38 L_ATCU_3rdRrTempCDis 1500;
BA_ "Version" SG_ 38 L_ATCU_3rdRrTempCDis "23.08.13";
BA_ "GenSigSendType" SG_ 38 L_ATCU_3rdRrModDis 4;
BA_ "UserSigValidity" SG_ 38 L_ATCU_3rdRrModDis 7;
BA_REL_ "GenSigTimeoutTime" BU_SG_REL_ L_3HKBD SG_ 38 L_ATCU_3rdRrModDis 1500;
BA_REL_ "GenSigTimeoutTime" BU_SG_REL_ L_HKBD SG_ 38 L_ATCU_3rdRrModDis 1500;
BA_ "Version" SG_ 38 L_ATCU_3rdRrModDis "23.08.13";
BA_ "GenSigSendType" SG_ 38 L_ATCU_3rdRrBlwDis 4;
BA_ "UserSigValidity" SG_ 38 L_ATCU_3rdRrBlwDis 7;
BA_REL_ "GenSigTimeoutTime" BU_SG_REL_ L_3HKBD SG_ 38 L_ATCU_3rdRrBlwDis 1500;
BA_REL_ "GenSigTimeoutTime" BU_SG_REL_ L_HKBD SG_ 38 L_ATCU_3rdRrBlwDis 1500;
BA_ "Version" SG_ 38 L_ATCU_3rdRrBlwDis "23.08.13";
BA_ "GenSigSendType" SG_ 38 L_ATCU_3rdRrAutoDis 4;
BA_ "UserSigValidity" SG_ 38 L_ATCU_3rdRrAutoDis 7;
BA_REL_ "GenSigTimeoutTime" BU_SG_REL_ L_3HKBD SG_ 38 L_ATCU_3rdRrAutoDis 1500;
BA_REL_ "GenSigTimeoutTime" BU_SG_REL_ L_HKBD SG_ 38 L_ATCU_3rdRrAutoDis 1500;
BA_ "Version" SG_ 38 L_ATCU_3rdRrAutoDis "23.08.13";
BA_ "GenSigSendType" SG_ 38 L_ATCU_3rdRrMultiAutoBlwDis 4;
BA_ "UserSigValidity" SG_ 38 L_ATCU_3rdRrMultiAutoBlwDis 7;
BA_REL_ "GenSigTimeoutTime" BU_SG_REL_ L_3HKBD SG_ 38 L_ATCU_3rdRrMultiAutoBlwDis 1500;
BA_REL_ "GenSigTimeoutTime" BU_SG_REL_ L_HKBD SG_ 38 L_ATCU_3rdRrMultiAutoBlwDis 1500;
BA_ "Version" SG_ 38 L_ATCU_3rdRrMultiAutoBlwDis "23.08.13";
BA_ "GenSigSendType" SG_ 38 L_ATCU_3rdRrSyncDis 4;
BA_ "UserSigValidity" SG_ 38 L_ATCU_3rdRrSyncDis 7;
BA_REL_ "GenSigTimeoutTime" BU_SG_REL_ L_3HKBD SG_ 38 L_ATCU_3rdRrSyncDis 1500;
BA_REL_ "GenSigTimeoutTime" BU_SG_REL_ L_HKBD SG_ 38 L_ATCU_3rdRrSyncDis 1500;
BA_ "Version" SG_ 38 L_ATCU_3rdRrSyncDis "23.08.13";
BA_ "GenSigSendType" SG_ 38 L_ATCU_3rdRrOnInd 4;
BA_ "UserSigValidity" SG_ 38 L_ATCU_3rdRrOnInd 7;
BA_REL_ "GenSigTimeoutTime" BU_SG_REL_ L_3HKBD SG_ 38 L_ATCU_3rdRrOnInd 1500;
BA_REL_ "GenSigTimeoutTime" BU_SG_REL_ L_HKBD SG_ 38 L_ATCU_3rdRrOnInd 1500;
BA_ "Version" SG_ 38 L_ATCU_3rdRrOnInd "23.08.13";
BA_ "GenSigSendType" SG_ 38 L_ATCU_3rdRrLockDis 4;
BA_ "UserSigValidity" SG_ 38 L_ATCU_3rdRrLockDis 7;
BA_REL_ "GenSigTimeoutTime" BU_SG_REL_ L_3HKBD SG_ 38 L_ATCU_3rdRrLockDis 1500;
BA_REL_ "GenSigTimeoutTime" BU_SG_REL_ L_HKBD SG_ 38 L_ATCU_3rdRrLockDis 1500;
BA_ "Version" SG_ 38 L_ATCU_3rdRrLockDis "23.08.13";
BA_ "GenSigSendType" SG_ 38 L_ATCU_3rdRrLcdBckLightSta 4;
BA_ "UserSigValidity" SG_ 38 L_ATCU_3rdRrLcdBckLightSta 7;
BA_REL_ "GenSigTimeoutTime" BU_SG_REL_ L_3HKBD SG_ 38 L_ATCU_3rdRrLcdBckLightSta 1500;
BA_REL_ "GenSigTimeoutTime" BU_SG_REL_ L_HKBD SG_ 38 L_ATCU_3rdRrLcdBckLightSta 1500;
BA_ "Version" SG_ 38 L_ATCU_3rdRrLcdBckLightSta "23.08.13";
BA_ "GenSigSendType" SG_ 38 L_ATCU_3rdRrGUIBlankDis 4;
BA_ "UserSigValidity" SG_ 38 L_ATCU_3rdRrGUIBlankDis 7;
BA_REL_ "GenSigTimeoutTime" BU_SG_REL_ L_3HKBD SG_ 38 L_ATCU_3rdRrGUIBlankDis 1500;
BA_REL_ "GenSigTimeoutTime" BU_SG_REL_ L_HKBD SG_ 38 L_ATCU_3rdRrGUIBlankDis 1500;
BA_ "Version" SG_ 38 L_ATCU_3rdRrGUIBlankDis "23.08.13";
BA_ "GenSigSendType" SG_ 38 L_ATCU_3rdRLStHeatSwHInd 4;
BA_ "UserSigValidity" SG_ 38 L_ATCU_3rdRLStHeatSwHInd 7;
BA_REL_ "GenSigTimeoutTime" BU_SG_REL_ L_3HKBD SG_ 38 L_ATCU_3rdRLStHeatSwHInd 1500;
BA_REL_ "GenSigTimeoutTime" BU_SG_REL_ L_HKBD SG_ 38 L_ATCU_3rdRLStHeatSwHInd 1500;
BA_ "Version" SG_ 38 L_ATCU_3rdRLStHeatSwHInd "23.08.13";
BA_ "GenSigSendType" SG_ 38 L_ATCU_3rdRLStHeatSwMInd 4;
BA_ "UserSigValidity" SG_ 38 L_ATCU_3rdRLStHeatSwMInd 7;
BA_REL_ "GenSigTimeoutTime" BU_SG_REL_ L_3HKBD SG_ 38 L_ATCU_3rdRLStHeatSwMInd 1500;
BA_REL_ "GenSigTimeoutTime" BU_SG_REL_ L_HKBD SG_ 38 L_ATCU_3rdRLStHeatSwMInd 1500;
BA_ "Version" SG_ 38 L_ATCU_3rdRLStHeatSwMInd "23.08.13";
BA_ "GenSigSendType" SG_ 38 L_ATCU_3rdRLStHeatSwLInd 4;
BA_ "UserSigValidity" SG_ 38 L_ATCU_3rdRLStHeatSwLInd 7;
BA_REL_ "GenSigTimeoutTime" BU_SG_REL_ L_3HKBD SG_ 38 L_ATCU_3rdRLStHeatSwLInd 1500;
BA_REL_ "GenSigTimeoutTime" BU_SG_REL_ L_HKBD SG_ 38 L_ATCU_3rdRLStHeatSwLInd 1500;
BA_ "Version" SG_ 38 L_ATCU_3rdRLStHeatSwLInd "23.08.13";
BA_ "GenSigSendType" SG_ 38 L_ATCU_3rdRLStVntSwHInd 4;
BA_ "UserSigValidity" SG_ 38 L_ATCU_3rdRLStVntSwHInd 7;
BA_REL_ "GenSigTimeoutTime" BU_SG_REL_ L_3HKBD SG_ 38 L_ATCU_3rdRLStVntSwHInd 1500;
BA_REL_ "GenSigTimeoutTime" BU_SG_REL_ L_HKBD SG_ 38 L_ATCU_3rdRLStVntSwHInd 1500;
BA_ "Version" SG_ 38 L_ATCU_3rdRLStVntSwHInd "23.08.13";
BA_ "GenSigSendType" SG_ 38 L_ATCU_3rdRLStVntSwMInd 4;
BA_ "UserSigValidity" SG_ 38 L_ATCU_3rdRLStVntSwMInd 7;
BA_REL_ "GenSigTimeoutTime" BU_SG_REL_ L_3HKBD SG_ 38 L_ATCU_3rdRLStVntSwMInd 1500;
BA_REL_ "GenSigTimeoutTime" BU_SG_REL_ L_HKBD SG_ 38 L_ATCU_3rdRLStVntSwMInd 1500;
BA_ "Version" SG_ 38 L_ATCU_3rdRLStVntSwMInd "23.08.13";
BA_ "GenSigSendType" SG_ 38 L_ATCU_3rdRLStVntSwLInd 4;
BA_ "UserSigValidity" SG_ 38 L_ATCU_3rdRLStVntSwLInd 7;
BA_REL_ "GenSigTimeoutTime" BU_SG_REL_ L_3HKBD SG_ 38 L_ATCU_3rdRLStVntSwLInd 1500;
BA_REL_ "GenSigTimeoutTime" BU_SG_REL_ L_HKBD SG_ 38 L_ATCU_3rdRLStVntSwLInd 1500;
BA_ "Version" SG_ 38 L_ATCU_3rdRLStVntSwLInd "23.08.13";
BA_ "GenSigSendType" SG_ 38 L_ATCU_3rdRRStHeatSwHInd 4;
BA_ "UserSigValidity" SG_ 38 L_ATCU_3rdRRStHeatSwHInd 7;
BA_REL_ "GenSigTimeoutTime" BU_SG_REL_ L_3HKBD SG_ 38 L_ATCU_3rdRRStHeatSwHInd 1500;
BA_REL_ "GenSigTimeoutTime" BU_SG_REL_ L_HKBD SG_ 38 L_ATCU_3rdRRStHeatSwHInd 1500;
BA_ "Version" SG_ 38 L_ATCU_3rdRRStHeatSwHInd "23.08.13";
BA_ "GenSigSendType" SG_ 38 L_ATCU_3rdRRStHeatSwMInd 4;
BA_ "UserSigValidity" SG_ 38 L_ATCU_3rdRRStHeatSwMInd 7;
BA_REL_ "GenSigTimeoutTime" BU_SG_REL_ L_3HKBD SG_ 38 L_ATCU_3rdRRStHeatSwMInd 1500;
BA_REL_ "GenSigTimeoutTime" BU_SG_REL_ L_HKBD SG_ 38 L_ATCU_3rdRRStHeatSwMInd 1500;
BA_ "Version" SG_ 38 L_ATCU_3rdRRStHeatSwMInd "23.08.13";
BA_ "GenSigSendType" SG_ 38 L_ATCU_3rdRRStHeatSwLInd 4;
BA_ "UserSigValidity" SG_ 38 L_ATCU_3rdRRStHeatSwLInd 7;
BA_REL_ "GenSigTimeoutTime" BU_SG_REL_ L_3HKBD SG_ 38 L_ATCU_3rdRRStHeatSwLInd 1500;
BA_REL_ "GenSigTimeoutTime" BU_SG_REL_ L_HKBD SG_ 38 L_ATCU_3rdRRStHeatSwLInd 1500;
BA_ "Version" SG_ 38 L_ATCU_3rdRRStHeatSwLInd "23.08.13";
BA_ "GenSigSendType" SG_ 38 L_ATCU_3rdRRStVntSwHInd 4;
BA_ "UserSigValidity" SG_ 38 L_ATCU_3rdRRStVntSwHInd 7;
BA_REL_ "GenSigTimeoutTime" BU_SG_REL_ L_3HKBD SG_ 38 L_ATCU_3rdRRStVntSwHInd 1500;
BA_REL_ "GenSigTimeoutTime" BU_SG_REL_ L_HKBD SG_ 38 L_ATCU_3rdRRStVntSwHInd 1500;
BA_ "Version" SG_ 38 L_ATCU_3rdRRStVntSwHInd "23.08.13";
BA_ "GenSigSendType" SG_ 38 L_ATCU_3rdRRStVntSwMInd 4;
BA_ "UserSigValidity" SG_ 38 L_ATCU_3rdRRStVntSwMInd 7;
BA_REL_ "GenSigTimeoutTime" BU_SG_REL_ L_3HKBD SG_ 38 L_ATCU_3rdRRStVntSwMInd 1500;
BA_REL_ "GenSigTimeoutTime" BU_SG_REL_ L_HKBD SG_ 38 L_ATCU_3rdRRStVntSwMInd 1500;
BA_ "Version" SG_ 38 L_ATCU_3rdRRStVntSwMInd "23.08.13";
BA_ "GenSigSendType" SG_ 38 L_ATCU_3rdRRStVntSwLInd 4;
BA_ "UserSigValidity" SG_ 38 L_ATCU_3rdRRStVntSwLInd 7;
BA_REL_ "GenSigTimeoutTime" BU_SG_REL_ L_3HKBD SG_ 38 L_ATCU_3rdRRStVntSwLInd 1500;
BA_REL_ "GenSigTimeoutTime" BU_SG_REL_ L_HKBD SG_ 38 L_ATCU_3rdRRStVntSwLInd 1500;
BA_ "Version" SG_ 38 L_ATCU_3rdRRStVntSwLInd "23.08.13";
BA_ "GenSigSendType" SG_ 38 L_ATCU_3rdRrMTCOpSta 4;
BA_ "UserSigValidity" SG_ 38 L_ATCU_3rdRrMTCOpSta 7;
BA_REL_ "GenSigTimeoutTime" BU_SG_REL_ L_3HKBD SG_ 38 L_ATCU_3rdRrMTCOpSta 1500;
BA_REL_ "GenSigTimeoutTime" BU_SG_REL_ L_HKBD SG_ 38 L_ATCU_3rdRrMTCOpSta 1500;
BA_ "Version" SG_ 38 L_ATCU_3rdRrMTCOpSta "23.08.13";
BA_ "GenSigSendType" SG_ 38 L_ATCU_3rdRrMtcTempLvl 4;
BA_ "UserSigValidity" SG_ 38 L_ATCU_3rdRrMtcTempLvl 7;
BA_REL_ "GenSigTimeoutTime" BU_SG_REL_ L_3HKBD SG_ 38 L_ATCU_3rdRrMtcTempLvl 1500;
BA_REL_ "GenSigTimeoutTime" BU_SG_REL_ L_HKBD SG_ 38 L_ATCU_3rdRrMtcTempLvl 1500;
BA_ "Version" SG_ 38 L_ATCU_3rdRrMtcTempLvl "23.08.13";
BA_ "GenSigSendType" SG_ 38 L_ATCU_3rdAUTOStep 4;
BA_ "UserSigValidity" SG_ 38 L_ATCU_3rdAUTOStep 7;
BA_REL_ "GenSigTimeoutTime" BU_SG_REL_ L_3HKBD SG_ 38 L_ATCU_3rdAUTOStep 1500;
BA_REL_ "GenSigTimeoutTime" BU_SG_REL_ L_HKBD SG_ 38 L_ATCU_3rdAUTOStep 1500;
BA_ "Version" SG_ 38 L_ATCU_3rdAUTOStep "23.08.13";
BA_ "GenSigSendType" SG_ 38 L_ATCU_RrPassMultiAutoBlwDis 4;
BA_ "UserSigValidity" SG_ 38 L_ATCU_RrPassMultiAutoBlwDis 7;
BA_REL_ "GenSigTimeoutTime" BU_SG_REL_ L_2HKBD SG_ 38 L_ATCU_RrPassMultiAutoBlwDis 1500;
BA_REL_ "GenSigTimeoutTime" BU_SG_REL_ L_HKBD SG_ 38 L_ATCU_RrPassMultiAutoBlwDis 1500;
BA_ "Version" SG_ 38 L_ATCU_RrPassMultiAutoBlwDis "23.08.13";
BA_ "GenSigSendType" SG_ 38 L_ATCU_DisPnlState 4;
BA_ "UserSigValidity" SG_ 38 L_ATCU_DisPnlState 7;
BA_REL_ "GenSigTimeoutTime" BU_SG_REL_ L_HKBD SG_ 38 L_ATCU_DisPnlState 1500;
BA_ "Version" SG_ 38 L_ATCU_DisPnlState "24.02.08";
BA_ "Description" SG_ 38 L_ATCU_3rdRrTempFDis "This signal indicates Outside Temperature (¢µ)

(Use for display only)";
BA_ "GenSigSendType" SG_ 38 L_ATCU_3rdRrTempFDis 4;
BA_ "UserSigValidity" SG_ 38 L_ATCU_3rdRrTempFDis 7;
BA_REL_ "GenSigTimeoutTime" BU_SG_REL_ L_3HKBD SG_ 38 L_ATCU_3rdRrTempFDis 1500;
BA_REL_ "GenSigTimeoutTime" BU_SG_REL_ L_HKBD SG_ 38 L_ATCU_3rdRrTempFDis 1500;
BA_ "Version" SG_ 38 L_ATCU_3rdRrTempFDis "23.08.13";
BA_ "GenMsgSendType" BO_ 39 0;
BA_ "GenMsgCycleTime" BO_ 39 20;
BA_ "GenMsgCycleTimeFast" BO_ 39 0;
BA_ "GenMsgNrOfRepetition" BO_ 39 0;
BA_ "GenMsgDelayTime" BO_ 39 0;
BA_ "UserSigValidity" SG_ 39 L_ATCU_RrHVACTempActrTgt 7;
BA_ "Version" SG_ 39 L_ATCU_RrHVACTempActrTgt "23.08.13";
BA_ "UserSigValidity" SG_ 39 L_ATCU_RrHVACTempAsstActrTgt 7;
BA_ "Version" SG_ 39 L_ATCU_RrHVACTempAsstActrTgt "23.08.13";
BA_ "UserSigValidity" SG_ 39 L_ATCU_RrDrHVACModeActrTgt 7;
BA_ "Version" SG_ 39 L_ATCU_RrDrHVACModeActrTgt "24.02.01";
BA_ "UserSigValidity" SG_ 39 L_ATCU_RrHVACBlowerTgtV 7;
BA_ "Version" SG_ 39 L_ATCU_RrHVACBlowerTgtV "23.08.13";
BA_ "UserSigValidity" SG_ 39 L_ATCU_RrHVACBLDCRpmVal 7;
BA_ "Version" SG_ 39 L_ATCU_RrHVACBLDCRpmVal "24.02.01";
BA_ "UserSigValidity" SG_ 39 L_ATCU_RrPsHVACModeActrTgt 7;
BA_ "Version" SG_ 39 L_ATCU_RrPsHVACModeActrTgt "24.02.01";
BA_ "GenMsgSendType" BO_ 40 0;
BA_ "GenSigSendType" SG_ 40 L_ATCU_PassAUTOStep 4;
BA_ "UserSigValidity" SG_ 40 L_ATCU_PassAUTOStep 7;
BA_REL_ "GenSigTimeoutTime" BU_SG_REL_ L_2HKBD SG_ 40 L_ATCU_PassAUTOStep 1500;
BA_REL_ "GenSigTimeoutTime" BU_SG_REL_ L_HKBD SG_ 40 L_ATCU_PassAUTOStep 1500;
BA_ "Version" SG_ 40 L_ATCU_PassAUTOStep "23.08.13";
BA_ "GenSigSendType" SG_ 40 L_ATCU_RrPassTempFDis 4;
BA_ "UserSigValidity" SG_ 40 L_ATCU_RrPassTempFDis 7;
BA_REL_ "GenSigTimeoutTime" BU_SG_REL_ L_2HKBD SG_ 40 L_ATCU_RrPassTempFDis 1500;
BA_REL_ "GenSigTimeoutTime" BU_SG_REL_ L_HKBD SG_ 40 L_ATCU_RrPassTempFDis 1500;
BA_ "Version" SG_ 40 L_ATCU_RrPassTempFDis "23.08.13";
BA_ "GenSigSendType" SG_ 40 L_ATCU_RrPassBlwDis 4;
BA_ "UserSigValidity" SG_ 40 L_ATCU_RrPassBlwDis 7;
BA_REL_ "GenSigTimeoutTime" BU_SG_REL_ L_2HKBD SG_ 40 L_ATCU_RrPassBlwDis 1500;
BA_REL_ "GenSigTimeoutTime" BU_SG_REL_ L_HKBD SG_ 40 L_ATCU_RrPassBlwDis 1500;
BA_ "Version" SG_ 40 L_ATCU_RrPassBlwDis "23.08.13";
BA_ "GenSigSendType" SG_ 40 L_ATCU_RrPassAUTODis 4;
BA_ "UserSigValidity" SG_ 40 L_ATCU_RrPassAUTODis 7;
BA_REL_ "GenSigTimeoutTime" BU_SG_REL_ L_2HKBD SG_ 40 L_ATCU_RrPassAUTODis 1500;
BA_REL_ "GenSigTimeoutTime" BU_SG_REL_ L_HKBD SG_ 40 L_ATCU_RrPassAUTODis 1500;
BA_ "Version" SG_ 40 L_ATCU_RrPassAUTODis "23.08.13";
BA_ "GenSigSendType" SG_ 40 L_ATCU_RrPassAUTOStep 4;
BA_ "UserSigValidity" SG_ 40 L_ATCU_RrPassAUTOStep 7;
BA_REL_ "GenSigTimeoutTime" BU_SG_REL_ L_2HKBD SG_ 40 L_ATCU_RrPassAUTOStep 1500;
BA_REL_ "GenSigTimeoutTime" BU_SG_REL_ L_HKBD SG_ 40 L_ATCU_RrPassAUTOStep 1500;
BA_ "Version" SG_ 40 L_ATCU_RrPassAUTOStep "23.08.13";
BA_ "Description" SG_ 40 L_ATCU_CampModeSta "Define the status of Camp Mode in EV";
BA_ "GenSigSendType" SG_ 40 L_ATCU_CampModeSta 4;
BA_ "UserSigValidity" SG_ 40 L_ATCU_CampModeSta 7;
BA_REL_ "GenSigTimeoutTime" BU_SG_REL_ L_2HKBD SG_ 40 L_ATCU_CampModeSta 1500;
BA_REL_ "GenSigTimeoutTime" BU_SG_REL_ L_3HKBD SG_ 40 L_ATCU_CampModeSta 1500;
BA_REL_ "GenSigTimeoutTime" BU_SG_REL_ L_EVNT SG_ 40 L_ATCU_CampModeSta 1500;
BA_REL_ "GenSigTimeoutTime" BU_SG_REL_ L_HKBD SG_ 40 L_ATCU_CampModeSta 1500;
BA_ "Version" SG_ 40 L_ATCU_CampModeSta "23.08.13";
BA_ "GenSigSendType" SG_ 40 L_ATCU_RrPassTempCDis 4;
BA_ "UserSigValidity" SG_ 40 L_ATCU_RrPassTempCDis 7;
BA_REL_ "GenSigTimeoutTime" BU_SG_REL_ L_2HKBD SG_ 40 L_ATCU_RrPassTempCDis 1500;
BA_REL_ "GenSigTimeoutTime" BU_SG_REL_ L_HKBD SG_ 40 L_ATCU_RrPassTempCDis 1500;
BA_ "Version" SG_ 40 L_ATCU_RrPassTempCDis "23.08.13";
BA_ "Description" SG_ 40 L_ATCU_UtilModeUsmSta "Timeout : Utility Mode OFF(Rest Mode OFF)";
BA_ "GenSigSendType" SG_ 40 L_ATCU_UtilModeUsmSta 4;
BA_ "UserSigValidity" SG_ 40 L_ATCU_UtilModeUsmSta 7;
BA_REL_ "GenSigTimeoutTime" BU_SG_REL_ L_2HKBD SG_ 40 L_ATCU_UtilModeUsmSta 1500;
BA_REL_ "GenSigTimeoutTime" BU_SG_REL_ L_3HKBD SG_ 40 L_ATCU_UtilModeUsmSta 1500;
BA_REL_ "GenSigTimeoutTime" BU_SG_REL_ L_EVNT SG_ 40 L_ATCU_UtilModeUsmSta 1500;
BA_REL_ "GenSigTimeoutTime" BU_SG_REL_ L_HKBD SG_ 40 L_ATCU_UtilModeUsmSta 1500;
BA_ "Version" SG_ 40 L_ATCU_UtilModeUsmSta "23.08.13";
BA_ "GenSigSendType" SG_ 40 L_ATCU_RrAcDis 4;
BA_ "UserSigValidity" SG_ 40 L_ATCU_RrAcDis 7;
BA_REL_ "GenSigTimeoutTime" BU_SG_REL_ L_2HKBD SG_ 40 L_ATCU_RrAcDis 1500;
BA_REL_ "GenSigTimeoutTime" BU_SG_REL_ L_3HKBD SG_ 40 L_ATCU_RrAcDis 1500;
BA_REL_ "GenSigTimeoutTime" BU_SG_REL_ L_HKBD SG_ 40 L_ATCU_RrAcDis 1500;
BA_ "Version" SG_ 40 L_ATCU_RrAcDis "24.02.01";
BA_ "GenSigSendType" SG_ 40 L_ATCU_3rdAcDis 4;
BA_ "UserSigValidity" SG_ 40 L_ATCU_3rdAcDis 7;
BA_REL_ "GenSigTimeoutTime" BU_SG_REL_ L_2HKBD SG_ 40 L_ATCU_3rdAcDis 1500;
BA_REL_ "GenSigTimeoutTime" BU_SG_REL_ L_3HKBD SG_ 40 L_ATCU_3rdAcDis 1500;
BA_REL_ "GenSigTimeoutTime" BU_SG_REL_ L_HKBD SG_ 40 L_ATCU_3rdAcDis 1500;
BA_ "Version" SG_ 40 L_ATCU_3rdAcDis "24.02.01";
BA_ "GenMsgSendType" BO_ 41 0;
BA_ "GenMsgCycleTime" BO_ 41 20;
BA_ "GenMsgCycleTimeFast" BO_ 41 0;
BA_ "GenMsgNrOfRepetition" BO_ 41 0;
BA_ "GenMsgDelayTime" BO_ 41 0;
BA_ "NmNode" BU_ L_FHPTC 0;
BA_ "NmNode" BU_ L_RHPTC 0;
BA_ "Description" SG_ 41 L_ATCU_OutTempDispC "This signal indicates Outside temperature (¡É).

(Use for display only)";
BA_ "UserSigValidity" SG_ 41 L_ATCU_OutTempDispC 7;
BA_ "Version" SG_ 41 L_ATCU_OutTempDispC "23.08.13";
BA_ "UserSigValidity" SG_ 41 L_ATCU_DtntOutSta 7;
BA_ "Version" SG_ 41 L_ATCU_DtntOutSta "23.08.13";
BA_ "UserSigValidity" SG_ 41 L_ATCU_AutoBrightSta 7;
BA_ "Version" SG_ 41 L_ATCU_AutoBrightSta "23.08.13";
BA_ "UserSigValidity" SG_ 41 L_ATCU_DustSnrVal 7;
BA_ "Version" SG_ 41 L_ATCU_DustSnrVal "23.08.13";
BA_ "Description" SG_ 41 L_ATCU_NotMinModeBrightSta "This signal indicates the bright level of original state. Original state means the previous state of Camp Mode.";
BA_ "UserSigValidity" SG_ 41 L_ATCU_NotMinModeBrightSta 7;
BA_ "Version" SG_ 41 L_ATCU_NotMinModeBrightSta "23.08.13";
BA_ "Description" SG_ 41 L_ATCU_IAUPrfleVal "This signal Indicate the Current detected Profile ID by IAU.

This signal is a signal that forwards profile signals from IAU to L_ATCU, and L_ATCU then forwards them as is to L_EVNT.(NOTICE : MAIN CAN's original validity is B+)";
BA_ "UserSigValidity" SG_ 41 L_ATCU_IAUPrfleVal 7;
BA_ "Version" SG_ 41 L_ATCU_IAUPrfleVal "24.03.06";
BA_ "Description" SG_ 41 L_ATCU_AVNPrfleVal "This signal is a signal that forwards profile signals from HU to L_ATCU, and L_ATCU then forwards them as is to L_EVNT.(NOTICE : MAIN CAN's original validity is B+) 

Profile 3~Profile9 value is only used from Vehicle Architecture 2.0 (STD_DB_CAR_R2, SV 24.6~) vehicle models Vehicle Architecture 1.0 (STD_DB_CAR) vehicle models can us";
BA_ "GenSigStartValue" SG_ 41 L_ATCU_AVNPrfleVal 15;
BA_ "UserSigValidity" SG_ 41 L_ATCU_AVNPrfleVal 7;
BA_ "Version" SG_ 41 L_ATCU_AVNPrfleVal "24.03.06";
BA_ "Description" SG_ 41 L_ATCU_SchdldClimateSta "Operation of the air conditioning system(NOT ROUTING)";
BA_ "UserSigValidity" SG_ 41 L_ATCU_SchdldClimateSta 7;
BA_ "Version" SG_ 41 L_ATCU_SchdldClimateSta "24.08.08";
BA_ "Description" SG_ 41 L_ATCU_OutTempDispF "This signal indicates Outside Temperature (¢µ)

(Use for display only)";
BA_ "UserSigValidity" SG_ 41 L_ATCU_OutTempDispF 7;
BA_ "Version" SG_ 41 L_ATCU_OutTempDispF "23.08.13";
BA_ "GenMsgSendType" BO_ 48 0;
BA_ "GenMsgCycleTime" BO_ 48 500;
BA_ "GenSigSendType" SG_ 48 L_ATCU_SW_Ver1 4;
BA_ "UserSigValidity" SG_ 48 L_ATCU_SW_Ver1 7;
BA_REL_ "GenSigTimeoutTime" BU_SG_REL_ L_HKBD SG_ 48 L_ATCU_SW_Ver1 5000;
BA_ "Version" SG_ 48 L_ATCU_SW_Ver1 "23.08.13";
BA_ "GenSigSendType" SG_ 48 L_ATCU_SW_Ver3 4;
BA_ "UserSigValidity" SG_ 48 L_ATCU_SW_Ver3 7;
BA_REL_ "GenSigTimeoutTime" BU_SG_REL_ L_HKBD SG_ 48 L_ATCU_SW_Ver3 5000;
BA_ "Version" SG_ 48 L_ATCU_SW_Ver3 "23.08.13";
BA_ "GenSigSendType" SG_ 48 L_ATCU_SW_Ver4 4;
BA_ "UserSigValidity" SG_ 48 L_ATCU_SW_Ver4 7;
BA_REL_ "GenSigTimeoutTime" BU_SG_REL_ L_HKBD SG_ 48 L_ATCU_SW_Ver4 5000;
BA_ "Version" SG_ 48 L_ATCU_SW_Ver4 "23.08.13";
BA_ "GenSigSendType" SG_ 48 L_ATCU_SW_Ver5 4;
BA_ "UserSigValidity" SG_ 48 L_ATCU_SW_Ver5 7;
BA_REL_ "GenSigTimeoutTime" BU_SG_REL_ L_HKBD SG_ 48 L_ATCU_SW_Ver5 5000;
BA_ "Version" SG_ 48 L_ATCU_SW_Ver5 "23.08.13";
BA_ "GenSigSendType" SG_ 48 L_ATCU_SW_Ver2 4;
BA_ "UserSigValidity" SG_ 48 L_ATCU_SW_Ver2 7;
BA_REL_ "GenSigTimeoutTime" BU_SG_REL_ L_HKBD SG_ 48 L_ATCU_SW_Ver2 5000;
BA_ "Version" SG_ 48 L_ATCU_SW_Ver2 "23.08.13";
BA_ "GenMsgSendType" BO_ 49 0;
BA_ "Description" SG_ 49 L_ATCU_ResetPreWrngForOthers "This is a PDC routing signal for reset preparing sideeffect of reset";
BA_ "GenSigSendType" SG_ 49 L_ATCU_ResetPreWrngForOthers 4;
BA_ "UserSigValidity" SG_ 49 L_ATCU_ResetPreWrngForOthers 0;
BA_REL_ "GenSigTimeoutTime" BU_SG_REL_ L_2HKBD SG_ 49 L_ATCU_ResetPreWrngForOthers 1500;
BA_REL_ "GenSigTimeoutTime" BU_SG_REL_ L_3HKBD SG_ 49 L_ATCU_ResetPreWrngForOthers 1500;
BA_REL_ "GenSigTimeoutTime" BU_SG_REL_ L_EVNT SG_ 49 L_ATCU_ResetPreWrngForOthers 1500;
BA_REL_ "GenSigTimeoutTime" BU_SG_REL_ L_HKBD SG_ 49 L_ATCU_ResetPreWrngForOthers 1500;
BA_REL_ "GenSigTimeoutTime" BU_SG_REL_ L_PCM SG_ 49 L_ATCU_ResetPreWrngForOthers 1500;
BA_ "Version" SG_ 49 L_ATCU_ResetPreWrngForOthers "24.07.02";
BA_ "Description" SG_ 49 L_ATCU_ResetReqForOthers "This is a PDC routing signal for SW reset except for Gateway";
BA_ "GenSigSendType" SG_ 49 L_ATCU_ResetReqForOthers 4;
BA_ "UserSigValidity" SG_ 49 L_ATCU_ResetReqForOthers 0;
BA_REL_ "GenSigTimeoutTime" BU_SG_REL_ L_2HKBD SG_ 49 L_ATCU_ResetReqForOthers 1500;
BA_REL_ "GenSigTimeoutTime" BU_SG_REL_ L_3HKBD SG_ 49 L_ATCU_ResetReqForOthers 1500;
BA_REL_ "GenSigTimeoutTime" BU_SG_REL_ L_EVNT SG_ 49 L_ATCU_ResetReqForOthers 1500;
BA_REL_ "GenSigTimeoutTime" BU_SG_REL_ L_HKBD SG_ 49 L_ATCU_ResetReqForOthers 1500;
BA_REL_ "GenSigTimeoutTime" BU_SG_REL_ L_PCM SG_ 49 L_ATCU_ResetReqForOthers 1500;
BA_ "Version" SG_ 49 L_ATCU_ResetReqForOthers "24.07.02";
BA_ "GenMsgSendType" BO_ 273 0;
BA_ "GenMsgCycleTime" BO_ 273 20;
BA_ "GenMsgCycleTimeFast" BO_ 273 0;
BA_ "GenMsgNrOfRepetition" BO_ 273 0;
BA_ "GenMsgDelayTime" BO_ 273 0;
BA_ "UserSigValidity" SG_ 273 L_ATCU_FHPTCOpPrmssnSta 7;
BA_ "Version" SG_ 273 L_ATCU_FHPTCOpPrmssnSta "23.08.13";
BA_ "UserSigValidity" SG_ 273 L_ATCU_FHPTCPassTrgtDty 7;
BA_ "Version" SG_ 273 L_ATCU_FHPTCPassTrgtDty "23.08.13";
BA_ "UserSigValidity" SG_ 273 L_ATCU_FHPTCDischrgReq 7;
BA_ "Version" SG_ 273 L_ATCU_FHPTCDischrgReq "23.08.13";
BA_ "Description" SG_ 273 L_ATCU_FltMsgTmOutFHPTC1 "Message Timeout of FHPTC_01";
BA_ "UserSigValidity" SG_ 273 L_ATCU_FltMsgTmOutFHPTC1 7;
BA_ "Version" SG_ 273 L_ATCU_FltMsgTmOutFHPTC1 "23.08.13";
BA_ "Description" SG_ 273 L_ATCU_FltMsgTmOutFHPTC2 "Message Timeout of FHPTC_02";
BA_ "UserSigValidity" SG_ 273 L_ATCU_FltMsgTmOutFHPTC2 7;
BA_ "Version" SG_ 273 L_ATCU_FltMsgTmOutFHPTC2 "23.08.13";
BA_ "Description" SG_ 273 L_ATCU_FltMsgTmOutFHPTC3 "Message Timeout of FHPTC_03";
BA_ "UserSigValidity" SG_ 273 L_ATCU_FltMsgTmOutFHPTC3 7;
BA_ "Version" SG_ 273 L_ATCU_FltMsgTmOutFHPTC3 "23.08.13";
BA_ "Description" SG_ 273 L_ATCU_FltMsgTmOutFHPTC4 "Message Timeout of FHPTC_04";
BA_ "UserSigValidity" SG_ 273 L_ATCU_FltMsgTmOutFHPTC4 7;
BA_ "Version" SG_ 273 L_ATCU_FltMsgTmOutFHPTC4 "23.08.13";
BA_ "Description" SG_ 273 L_ATCU_FrBlwLvl "This signal indicates step of Front blower operation";
BA_ "UserSigValidity" SG_ 273 L_ATCU_FrBlwLvl 7;
BA_ "Version" SG_ 273 L_ATCU_FrBlwLvl "23.08.13";
BA_ "Description" SG_ 273 L_ATCU_FrBlwLvlSigVaildSta "This signal sindicates the validation of 'blower level signal'

Initial value is 0x0(Invalid, do not send information of blower level)";
BA_ "UserSigValidity" SG_ 273 L_ATCU_FrBlwLvlSigVaildSta 7;
BA_ "Version" SG_ 273 L_ATCU_FrBlwLvlSigVaildSta "23.08.13";
BA_ "Description" SG_ 273 L_ATCU_DrvrSdTyp "This signal indicates information of driver type (LHD/RHD)";
BA_ "UserSigValidity" SG_ 273 L_ATCU_DrvrSdTyp 7;
BA_ "Version" SG_ 273 L_ATCU_DrvrSdTyp "23.08.13";
BA_ "UserSigValidity" SG_ 273 L_ATCU_FrBlwFltSta 7;
BA_ "Version" SG_ 273 L_ATCU_FrBlwFltSta "23.08.13";
BA_ "UserSigValidity" SG_ 273 L_ATCU_PassBlwLvl 7;
BA_ "Version" SG_ 273 L_ATCU_PassBlwLvl "23.08.13";
BA_ "UserSigValidity" SG_ 273 L_ATCU_FHPTCDrTrgtDty 7;
BA_ "Version" SG_ 273 L_ATCU_FHPTCDrTrgtDty "23.08.13";
BA_ "GenMsgSendType" BO_ 65 0;
BA_ "GenMsgCycleTime" BO_ 65 500;
BA_ "Description" SG_ 65 HKBD_Typ1 "Bit0 (Climate Display Side):0 ? Left Side /1 ? Right Side

Bit1 (LCD/NON LCD TYPE): 0- NON LCD/1- LCD TYPE

Bit2~3 (Button Type):0 - HardKey (Push-Return)/1- Touch/2- HardKey + Touch/3 - RESERVED 

Bit4~5 (Button Arragement Type):0 ? Single (Blower-Temp-Mode)/1 ? Single (Temp-Mode-Blower)/2 ? Dual ¡¤ 3zone ¡¤ 4zone¡¤Etc. /3 - RESERVED 

Bit6~7 (Mode Button):0 ? 1 Button/1 ?  2 Button/2 ? 3 Button";
BA_ "GenSigSendType" SG_ 65 HKBD_Typ1 4;
BA_ "UserSigValidity" SG_ 65 HKBD_Typ1 7;
BA_REL_ "GenSigTimeoutTime" BU_SG_REL_ L_ATCU SG_ 65 HKBD_Typ1 5000;
BA_ "Version" SG_ 65 HKBD_Typ1 "23.08.13";
BA_ "Description" SG_ 65 HKBD_Typ2 "Bit0 (Mode Def Type):0 ? Symbol Type/1 ? Arrow Type

Bit1 (Air Purifier Button):0 - None/1 - AIR PURIFIER BUTTON APPLIED

Bit2 (Haptic):0 - None/1 - Applied 

Bit3 (Multi Auto Button Type) :  0 - Push / 1 - Tumbler 

Bit4~ 5 (Climate OSD UI Type) : 0 - None (Basic UI Type) / 1 - (TEMP-Blower - Mode - Temp) / 2 - (Temp - Mode (Auto) - Blower - Temp) / 3 - Reserved 

Bit6~7 (Blower Button Type) : 0 - None / 1 - Blower down type / 2 - blower down off type / 3 - Invalid";
BA_ "GenSigSendType" SG_ 65 HKBD_Typ2 4;
BA_ "UserSigValidity" SG_ 65 HKBD_Typ2 7;
BA_REL_ "GenSigTimeoutTime" BU_SG_REL_ L_ATCU SG_ 65 HKBD_Typ2 5000;
BA_ "Version" SG_ 65 HKBD_Typ2 "24.02.01";
BA_ "Description" SG_ 65 HKBD_Typ3 "Bit0~1 : RESERVED

Bit2~3 (Front Multi Auto Text):0 - Multi Auto State Text Not Applied/1 - Multi Auto State Text Display Only Applied/2 - Multi Auto State Text Display & Control Applied/3 ? RESERVED

Bit4~5 : RESERVED

Bit6~7 (Pass Multi Auto Text):0 - Multi Auto State Text Not Applied/1 - Multi Auto State Text Display Only Applied/2 - Multi Auto State Text Display & Control Applied/3 ? RESERVED";
BA_ "GenSigSendType" SG_ 65 HKBD_Typ3 4;
BA_ "UserSigValidity" SG_ 65 HKBD_Typ3 7;
BA_REL_ "GenSigTimeoutTime" BU_SG_REL_ L_ATCU SG_ 65 HKBD_Typ3 5000;
BA_ "Version" SG_ 65 HKBD_Typ3 "24.02.01";
BA_ "GenMsgSendType" BO_ 66 0;
BA_ "GenSigSendType" SG_ 66 HKBD_Fr_DrModDnSw 4;
BA_ "UserSigValidity" SG_ 66 HKBD_Fr_DrModDnSw 7;
BA_REL_ "GenSigTimeoutTime" BU_SG_REL_ L_ATCU SG_ 66 HKBD_Fr_DrModDnSw 1500;
BA_ "Version" SG_ 66 HKBD_Fr_DrModDnSw "23.08.13";
BA_ "GenSigSendType" SG_ 66 HKBD_Fr_DrModUpSw 4;
BA_ "UserSigValidity" SG_ 66 HKBD_Fr_DrModUpSw 7;
BA_REL_ "GenSigTimeoutTime" BU_SG_REL_ L_ATCU SG_ 66 HKBD_Fr_DrModUpSw 1500;
BA_ "Version" SG_ 66 HKBD_Fr_DrModUpSw "23.08.13";
BA_ "GenSigSendType" SG_ 66 HKBD_Fr_DrMultiAutoSw 4;
BA_ "GenSigStartValue" SG_ 66 HKBD_Fr_DrMultiAutoSw 7;
BA_ "UserSigValidity" SG_ 66 HKBD_Fr_DrMultiAutoSw 7;
BA_REL_ "GenSigTimeoutTime" BU_SG_REL_ L_ATCU SG_ 66 HKBD_Fr_DrMultiAutoSw 1500;
BA_ "Version" SG_ 66 HKBD_Fr_DrMultiAutoSw "24.05.08";
BA_ "GenSigSendType" SG_ 66 HKBD_Fr_PsAutoSw 4;
BA_ "UserSigValidity" SG_ 66 HKBD_Fr_PsAutoSw 7;
BA_REL_ "GenSigTimeoutTime" BU_SG_REL_ L_ATCU SG_ 66 HKBD_Fr_PsAutoSw 1500;
BA_ "Version" SG_ 66 HKBD_Fr_PsAutoSw "23.08.13";
BA_ "GenSigSendType" SG_ 66 HKBD_Fr_PsMultiAutoSw 4;
BA_ "GenSigStartValue" SG_ 66 HKBD_Fr_PsMultiAutoSw 7;
BA_ "UserSigValidity" SG_ 66 HKBD_Fr_PsMultiAutoSw 7;
BA_REL_ "GenSigTimeoutTime" BU_SG_REL_ L_ATCU SG_ 66 HKBD_Fr_PsMultiAutoSw 1500;
BA_ "Version" SG_ 66 HKBD_Fr_PsMultiAutoSw "24.05.08";
BA_ "GenSigSendType" SG_ 66 HKBD_Fr_AcSw 4;
BA_ "UserSigValidity" SG_ 66 HKBD_Fr_AcSw 7;
BA_REL_ "GenSigTimeoutTime" BU_SG_REL_ L_ATCU SG_ 66 HKBD_Fr_AcSw 1500;
BA_ "Version" SG_ 66 HKBD_Fr_AcSw "23.08.13";
BA_ "GenSigSendType" SG_ 66 HKBD_Fr_DefSw 4;
BA_ "UserSigValidity" SG_ 66 HKBD_Fr_DefSw 7;
BA_REL_ "GenSigTimeoutTime" BU_SG_REL_ L_ATCU SG_ 66 HKBD_Fr_DefSw 1500;
BA_ "Version" SG_ 66 HKBD_Fr_DefSw "23.08.13";
BA_ "GenSigSendType" SG_ 66 HKBD_Fr_RecSw 4;
BA_ "UserSigValidity" SG_ 66 HKBD_Fr_RecSw 7;
BA_REL_ "GenSigTimeoutTime" BU_SG_REL_ L_ATCU SG_ 66 HKBD_Fr_RecSw 1500;
BA_ "Version" SG_ 66 HKBD_Fr_RecSw "23.08.13";
BA_ "GenSigSendType" SG_ 66 HKBD_Fr_DrModVntSw 4;
BA_ "UserSigValidity" SG_ 66 HKBD_Fr_DrModVntSw 7;
BA_REL_ "GenSigTimeoutTime" BU_SG_REL_ L_ATCU SG_ 66 HKBD_Fr_DrModVntSw 1500;
BA_ "Version" SG_ 66 HKBD_Fr_DrModVntSw "23.08.13";
BA_ "GenSigSendType" SG_ 66 HKBD_Fr_FreSw 4;
BA_ "UserSigValidity" SG_ 66 HKBD_Fr_FreSw 7;
BA_REL_ "GenSigTimeoutTime" BU_SG_REL_ L_ATCU SG_ 66 HKBD_Fr_FreSw 1500;
BA_ "Version" SG_ 66 HKBD_Fr_FreSw "23.08.13";
BA_ "GenSigSendType" SG_ 66 HKBD_Fr_IntakeTglSw 4;
BA_ "UserSigValidity" SG_ 66 HKBD_Fr_IntakeTglSw 7;
BA_REL_ "GenSigTimeoutTime" BU_SG_REL_ L_ATCU SG_ 66 HKBD_Fr_IntakeTglSw 1500;
BA_ "Version" SG_ 66 HKBD_Fr_IntakeTglSw "23.08.13";
BA_ "GenSigSendType" SG_ 66 HKBD_Fr_OffSw 4;
BA_ "UserSigValidity" SG_ 66 HKBD_Fr_OffSw 7;
BA_REL_ "GenSigTimeoutTime" BU_SG_REL_ L_ATCU SG_ 66 HKBD_Fr_OffSw 1500;
BA_ "Version" SG_ 66 HKBD_Fr_OffSw "23.08.13";
BA_ "GenSigSendType" SG_ 66 HKBD_Fr_SyncSw 4;
BA_ "UserSigValidity" SG_ 66 HKBD_Fr_SyncSw 7;
BA_REL_ "GenSigTimeoutTime" BU_SG_REL_ L_ATCU SG_ 66 HKBD_Fr_SyncSw 1500;
BA_ "Version" SG_ 66 HKBD_Fr_SyncSw "23.08.13";
BA_ "GenSigSendType" SG_ 66 HKBD_Fr_RrDefInd 4;
BA_ "UserSigValidity" SG_ 66 HKBD_Fr_RrDefInd 7;
BA_REL_ "GenSigTimeoutTime" BU_SG_REL_ L_ATCU SG_ 66 HKBD_Fr_RrDefInd 1500;
BA_ "Version" SG_ 66 HKBD_Fr_RrDefInd "23.08.13";
BA_ "GenSigSendType" SG_ 66 HKBD_Fr_RrDefSw 4;
BA_ "UserSigValidity" SG_ 66 HKBD_Fr_RrDefSw 7;
BA_REL_ "GenSigTimeoutTime" BU_SG_REL_ L_ATCU SG_ 66 HKBD_Fr_RrDefSw 1500;
BA_ "Version" SG_ 66 HKBD_Fr_RrDefSw "23.08.13";
BA_ "GenSigSendType" SG_ 66 HKBD_Fr_ArclnSw 4;
BA_ "UserSigValidity" SG_ 66 HKBD_Fr_ArclnSw 7;
BA_REL_ "GenSigTimeoutTime" BU_SG_REL_ L_ATCU SG_ 66 HKBD_Fr_ArclnSw 1500;
BA_ "Version" SG_ 66 HKBD_Fr_ArclnSw "23.08.13";
BA_ "GenSigSendType" SG_ 66 HKBD_Fr_DrOnlySw 4;
BA_ "UserSigValidity" SG_ 66 HKBD_Fr_DrOnlySw 7;
BA_REL_ "GenSigTimeoutTime" BU_SG_REL_ L_ATCU SG_ 66 HKBD_Fr_DrOnlySw 1500;
BA_ "Version" SG_ 66 HKBD_Fr_DrOnlySw "23.08.13";
BA_ "GenSigSendType" SG_ 66 HKBD_Fr_ClimateSw 4;
BA_ "UserSigValidity" SG_ 66 HKBD_Fr_ClimateSw 7;
BA_REL_ "GenSigTimeoutTime" BU_SG_REL_ L_ATCU SG_ 66 HKBD_Fr_ClimateSw 1500;
BA_ "Version" SG_ 66 HKBD_Fr_ClimateSw "23.08.13";
BA_ "GenSigSendType" SG_ 66 HKBD_Fr_PerfumeSw 4;
BA_ "UserSigValidity" SG_ 66 HKBD_Fr_PerfumeSw 7;
BA_REL_ "GenSigTimeoutTime" BU_SG_REL_ L_ATCU SG_ 66 HKBD_Fr_PerfumeSw 1500;
BA_ "Version" SG_ 66 HKBD_Fr_PerfumeSw "23.08.13";
BA_ "GenSigSendType" SG_ 66 HKBD_Fr_DrModFlrSw 4;
BA_ "UserSigValidity" SG_ 66 HKBD_Fr_DrModFlrSw 7;
BA_REL_ "GenSigTimeoutTime" BU_SG_REL_ L_ATCU SG_ 66 HKBD_Fr_DrModFlrSw 1500;
BA_ "Version" SG_ 66 HKBD_Fr_DrModFlrSw "23.08.13";
BA_ "GenSigSendType" SG_ 66 HKBD_Fr_HptIntnstySta 4;
BA_ "UserSigValidity" SG_ 66 HKBD_Fr_HptIntnstySta 7;
BA_REL_ "GenSigTimeoutTime" BU_SG_REL_ L_ATCU SG_ 66 HKBD_Fr_HptIntnstySta 1500;
BA_ "Version" SG_ 66 HKBD_Fr_HptIntnstySta "23.11.06";
BA_ "GenSigSendType" SG_ 66 HKBD_Fr_StrWhlHeatSw 4;
BA_ "UserSigValidity" SG_ 66 HKBD_Fr_StrWhlHeatSw 7;
BA_REL_ "GenSigTimeoutTime" BU_SG_REL_ L_ATCU SG_ 66 HKBD_Fr_StrWhlHeatSw 1500;
BA_ "Version" SG_ 66 HKBD_Fr_StrWhlHeatSw "23.08.13";
BA_ "GenSigSendType" SG_ 66 HKBD_FLStHeatSw 4;
BA_ "UserSigValidity" SG_ 66 HKBD_FLStHeatSw 7;
BA_REL_ "GenSigTimeoutTime" BU_SG_REL_ L_ATCU SG_ 66 HKBD_FLStHeatSw 1500;
BA_ "Version" SG_ 66 HKBD_FLStHeatSw "23.08.13";
BA_ "GenSigSendType" SG_ 66 HKBD_FLStVentSw 4;
BA_ "UserSigValidity" SG_ 66 HKBD_FLStVentSw 7;
BA_REL_ "GenSigTimeoutTime" BU_SG_REL_ L_ATCU SG_ 66 HKBD_FLStVentSw 1500;
BA_ "Version" SG_ 66 HKBD_FLStVentSw "23.08.13";
BA_ "GenSigSendType" SG_ 66 HKBD_FRStHeatSw 4;
BA_ "UserSigValidity" SG_ 66 HKBD_FRStHeatSw 7;
BA_REL_ "GenSigTimeoutTime" BU_SG_REL_ L_ATCU SG_ 66 HKBD_FRStHeatSw 1500;
BA_ "Version" SG_ 66 HKBD_FRStHeatSw "23.08.13";
BA_ "GenSigSendType" SG_ 66 HKBD_FRStVentSw 4;
BA_ "UserSigValidity" SG_ 66 HKBD_FRStVentSw 7;
BA_REL_ "GenSigTimeoutTime" BU_SG_REL_ L_ATCU SG_ 66 HKBD_FRStVentSw 1500;
BA_ "Version" SG_ 66 HKBD_FRStVentSw "23.08.13";
BA_ "GenSigSendType" SG_ 66 HKBD_FLStTumblrSw 4;
BA_ "UserSigValidity" SG_ 66 HKBD_FLStTumblrSw 7;
BA_REL_ "GenSigTimeoutTime" BU_SG_REL_ L_ATCU SG_ 66 HKBD_FLStTumblrSw 1500;
BA_ "Version" SG_ 66 HKBD_FLStTumblrSw "23.08.13";
BA_ "GenSigSendType" SG_ 66 HKBD_Fr_DrModDefSw 4;
BA_ "UserSigValidity" SG_ 66 HKBD_Fr_DrModDefSw 7;
BA_REL_ "GenSigTimeoutTime" BU_SG_REL_ L_ATCU SG_ 66 HKBD_Fr_DrModDefSw 1500;
BA_ "Version" SG_ 66 HKBD_Fr_DrModDefSw "23.08.13";
BA_ "GenSigSendType" SG_ 66 HKBD_FRStTumblrSw 4;
BA_ "UserSigValidity" SG_ 66 HKBD_FRStTumblrSw 7;
BA_REL_ "GenSigTimeoutTime" BU_SG_REL_ L_ATCU SG_ 66 HKBD_FRStTumblrSw 1500;
BA_ "Version" SG_ 66 HKBD_FRStTumblrSw "23.08.13";
BA_ "GenSigSendType" SG_ 66 HKBD_Fr_FrWndShldHtSw 4;
BA_ "UserSigValidity" SG_ 66 HKBD_Fr_FrWndShldHtSw 7;
BA_REL_ "GenSigTimeoutTime" BU_SG_REL_ L_ATCU SG_ 66 HKBD_Fr_FrWndShldHtSw 1500;
BA_ "Version" SG_ 66 HKBD_Fr_FrWndShldHtSw "23.08.13";
BA_ "Description" SG_ 66 HKBD_Fr_DrAutoDnSw "This signal should be used for tumbler type AUTO switch";
BA_ "GenSigSendType" SG_ 66 HKBD_Fr_DrAutoDnSw 4;
BA_ "UserSigValidity" SG_ 66 HKBD_Fr_DrAutoDnSw 7;
BA_REL_ "GenSigTimeoutTime" BU_SG_REL_ L_ATCU SG_ 66 HKBD_Fr_DrAutoDnSw 1500;
BA_ "Version" SG_ 66 HKBD_Fr_DrAutoDnSw "23.08.13";
BA_ "Description" SG_ 66 HKBD_Fr_DrAutoUpSw "This signal should be used for tumbler type AUTO switch";
BA_ "GenSigSendType" SG_ 66 HKBD_Fr_DrAutoUpSw 4;
BA_ "UserSigValidity" SG_ 66 HKBD_Fr_DrAutoUpSw 7;
BA_REL_ "GenSigTimeoutTime" BU_SG_REL_ L_ATCU SG_ 66 HKBD_Fr_DrAutoUpSw 1500;
BA_ "Version" SG_ 66 HKBD_Fr_DrAutoUpSw "23.08.13";
BA_ "GenSigSendType" SG_ 66 HKBD_Fr_DrModSw 4;
BA_ "UserSigValidity" SG_ 66 HKBD_Fr_DrModSw 7;
BA_REL_ "GenSigTimeoutTime" BU_SG_REL_ L_ATCU SG_ 66 HKBD_Fr_DrModSw 1500;
BA_ "Version" SG_ 66 HKBD_Fr_DrModSw "23.08.13";
BA_ "GenSigSendType" SG_ 66 HKBD_Fr_PsModSw 4;
BA_ "UserSigValidity" SG_ 66 HKBD_Fr_PsModSw 7;
BA_REL_ "GenSigTimeoutTime" BU_SG_REL_ L_ATCU SG_ 66 HKBD_Fr_PsModSw 1500;
BA_ "Version" SG_ 66 HKBD_Fr_PsModSw "23.08.13";
BA_ "Description" SG_ 66 HKBD_DisplayTheme "Feedback for the HKBD Display Theme state information";
BA_ "GenSigSendType" SG_ 66 HKBD_DisplayTheme 4;
BA_ "GenSigStartValue" SG_ 66 HKBD_DisplayTheme 3;
BA_ "UserSigValidity" SG_ 66 HKBD_DisplayTheme 7;
BA_REL_ "GenSigTimeoutTime" BU_SG_REL_ L_ATCU SG_ 66 HKBD_DisplayTheme 1500;
BA_ "Version" SG_ 66 HKBD_DisplayTheme "24.01.00";
BA_ "GenSigSendType" SG_ 66 HKBD_Fr_PsModDnSw 4;
BA_ "UserSigValidity" SG_ 66 HKBD_Fr_PsModDnSw 7;
BA_REL_ "GenSigTimeoutTime" BU_SG_REL_ L_ATCU SG_ 66 HKBD_Fr_PsModDnSw 1500;
BA_ "Version" SG_ 66 HKBD_Fr_PsModDnSw "23.08.13";
BA_ "Description" SG_ 66 HKBD_Fr_SmartZoneSW "Smart HVAC SmartZone indicator on/off signal";
BA_ "GenSigSendType" SG_ 66 HKBD_Fr_SmartZoneSW 4;
BA_ "UserSigValidity" SG_ 66 HKBD_Fr_SmartZoneSW 7;
BA_REL_ "GenSigTimeoutTime" BU_SG_REL_ L_ATCU SG_ 66 HKBD_Fr_SmartZoneSW 1500;
BA_ "Version" SG_ 66 HKBD_Fr_SmartZoneSW "24.11.00";
BA_ "GenSigSendType" SG_ 66 HKBD_Fr_PsModUpSw 4;
BA_ "UserSigValidity" SG_ 66 HKBD_Fr_PsModUpSw 7;
BA_REL_ "GenSigTimeoutTime" BU_SG_REL_ L_ATCU SG_ 66 HKBD_Fr_PsModUpSw 1500;
BA_ "Version" SG_ 66 HKBD_Fr_PsModUpSw "23.08.13";
BA_ "GenSigSendType" SG_ 66 HKBD_Fr_PsModVntSw 4;
BA_ "UserSigValidity" SG_ 66 HKBD_Fr_PsModVntSw 7;
BA_REL_ "GenSigTimeoutTime" BU_SG_REL_ L_ATCU SG_ 66 HKBD_Fr_PsModVntSw 1500;
BA_ "Version" SG_ 66 HKBD_Fr_PsModVntSw "23.08.13";
BA_ "GenSigSendType" SG_ 66 HKBD_Fr_PsModFlrSw 4;
BA_ "UserSigValidity" SG_ 66 HKBD_Fr_PsModFlrSw 7;
BA_REL_ "GenSigTimeoutTime" BU_SG_REL_ L_ATCU SG_ 66 HKBD_Fr_PsModFlrSw 1500;
BA_ "Version" SG_ 66 HKBD_Fr_PsModFlrSw "23.08.13";
BA_ "GenSigSendType" SG_ 66 HKBD_Fr_DrAutoSw 4;
BA_ "UserSigValidity" SG_ 66 HKBD_Fr_DrAutoSw 7;
BA_REL_ "GenSigTimeoutTime" BU_SG_REL_ L_ATCU SG_ 66 HKBD_Fr_DrAutoSw 1500;
BA_ "Version" SG_ 66 HKBD_Fr_DrAutoSw "23.08.13";
BA_ "GenMsgCycleTime" BO_ 67 0;
BA_ "GenSigSendType" SG_ 67 HKBD_Fr_DrTempClickCnt 4;
BA_ "GenSigStartValue" SG_ 67 HKBD_Fr_DrTempClickCnt 255;
BA_ "UserSigValidity" SG_ 67 HKBD_Fr_DrTempClickCnt 7;
BA_REL_ "GenSigTimeoutTime" BU_SG_REL_ L_ATCU SG_ 67 HKBD_Fr_DrTempClickCnt 0;
BA_ "Version" SG_ 67 HKBD_Fr_DrTempClickCnt "24.05.08";
BA_ "GenSigSendType" SG_ 67 HKBD_Fr_RrTempClickCnt 4;
BA_ "GenSigStartValue" SG_ 67 HKBD_Fr_RrTempClickCnt 255;
BA_ "UserSigValidity" SG_ 67 HKBD_Fr_RrTempClickCnt 7;
BA_REL_ "GenSigTimeoutTime" BU_SG_REL_ L_ATCU SG_ 67 HKBD_Fr_RrTempClickCnt 0;
BA_ "Version" SG_ 67 HKBD_Fr_RrTempClickCnt "24.05.08";
BA_ "GenSigSendType" SG_ 67 HKBD_Fr_DrBlwClickCnt 4;
BA_ "GenSigStartValue" SG_ 67 HKBD_Fr_DrBlwClickCnt 255;
BA_ "UserSigValidity" SG_ 67 HKBD_Fr_DrBlwClickCnt 7;
BA_REL_ "GenSigTimeoutTime" BU_SG_REL_ L_ATCU SG_ 67 HKBD_Fr_DrBlwClickCnt 0;
BA_ "Version" SG_ 67 HKBD_Fr_DrBlwClickCnt "24.05.08";
BA_ "GenSigSendType" SG_ 67 HKBD_Fr_PsBlwClickCnt 4;
BA_ "GenSigStartValue" SG_ 67 HKBD_Fr_PsBlwClickCnt 255;
BA_ "UserSigValidity" SG_ 67 HKBD_Fr_PsBlwClickCnt 7;
BA_REL_ "GenSigTimeoutTime" BU_SG_REL_ L_ATCU SG_ 67 HKBD_Fr_PsBlwClickCnt 0;
BA_ "Version" SG_ 67 HKBD_Fr_PsBlwClickCnt "24.05.08";
BA_ "GenSigSendType" SG_ 67 HKBD_FrTempKnobCnt 4;
BA_ "GenSigStartValue" SG_ 67 HKBD_FrTempKnobCnt 3;
BA_ "UserSigValidity" SG_ 67 HKBD_FrTempKnobCnt 7;
BA_REL_ "GenSigTimeoutTime" BU_SG_REL_ L_ATCU SG_ 67 HKBD_FrTempKnobCnt 0;
BA_ "Version" SG_ 67 HKBD_FrTempKnobCnt "24.05.08";
BA_ "GenSigSendType" SG_ 67 HKBD_FrBlwKnobCnt 4;
BA_ "GenSigStartValue" SG_ 67 HKBD_FrBlwKnobCnt 3;
BA_ "UserSigValidity" SG_ 67 HKBD_FrBlwKnobCnt 7;
BA_REL_ "GenSigTimeoutTime" BU_SG_REL_ L_ATCU SG_ 67 HKBD_FrBlwKnobCnt 0;
BA_ "Version" SG_ 67 HKBD_FrBlwKnobCnt "24.05.08";
BA_ "GenSigSendType" SG_ 67 HKBD_Fr_PsTempClickCnt 4;
BA_ "GenSigStartValue" SG_ 67 HKBD_Fr_PsTempClickCnt 255;
BA_ "UserSigValidity" SG_ 67 HKBD_Fr_PsTempClickCnt 7;
BA_REL_ "GenSigTimeoutTime" BU_SG_REL_ L_ATCU SG_ 67 HKBD_Fr_PsTempClickCnt 0;
BA_ "Version" SG_ 67 HKBD_Fr_PsTempClickCnt "24.05.08";
BA_ "GenMsgSendType" BO_ 68 0;
BA_ "GenSigSendType" SG_ 68 HKBD_Fr_DrTempDnSw 4;
BA_ "UserSigValidity" SG_ 68 HKBD_Fr_DrTempDnSw 7;
BA_REL_ "GenSigTimeoutTime" BU_SG_REL_ L_ATCU SG_ 68 HKBD_Fr_DrTempDnSw 1500;
BA_ "Version" SG_ 68 HKBD_Fr_DrTempDnSw "23.08.13";
BA_ "GenSigSendType" SG_ 68 HKBD_Fr_DrTempUpSw 4;
BA_ "UserSigValidity" SG_ 68 HKBD_Fr_DrTempUpSw 7;
BA_REL_ "GenSigTimeoutTime" BU_SG_REL_ L_ATCU SG_ 68 HKBD_Fr_DrTempUpSw 1500;
BA_ "Version" SG_ 68 HKBD_Fr_DrTempUpSw "23.08.13";
BA_ "GenSigSendType" SG_ 68 HKBD_Fr_PsBlwDnSw 4;
BA_ "UserSigValidity" SG_ 68 HKBD_Fr_PsBlwDnSw 7;
BA_REL_ "GenSigTimeoutTime" BU_SG_REL_ L_ATCU SG_ 68 HKBD_Fr_PsBlwDnSw 1500;
BA_ "Version" SG_ 68 HKBD_Fr_PsBlwDnSw "23.08.13";
BA_ "GenSigSendType" SG_ 68 HKBD_Fr_PsBlwDnOffSw 4;
BA_ "UserSigValidity" SG_ 68 HKBD_Fr_PsBlwDnOffSw 7;
BA_REL_ "GenSigTimeoutTime" BU_SG_REL_ L_ATCU SG_ 68 HKBD_Fr_PsBlwDnOffSw 1500;
BA_ "Version" SG_ 68 HKBD_Fr_PsBlwDnOffSw "23.08.13";
BA_ "GenSigSendType" SG_ 68 HKBD_Fr_PsBlwUpSw 4;
BA_ "UserSigValidity" SG_ 68 HKBD_Fr_PsBlwUpSw 7;
BA_REL_ "GenSigTimeoutTime" BU_SG_REL_ L_ATCU SG_ 68 HKBD_Fr_PsBlwUpSw 1500;
BA_ "Version" SG_ 68 HKBD_Fr_PsBlwUpSw "23.08.13";
BA_ "GenSigSendType" SG_ 68 HKBD_Fr_PsBlwSet 4;
BA_ "GenSigStartValue" SG_ 68 HKBD_Fr_PsBlwSet 15;
BA_ "UserSigValidity" SG_ 68 HKBD_Fr_PsBlwSet 7;
BA_REL_ "GenSigTimeoutTime" BU_SG_REL_ L_ATCU SG_ 68 HKBD_Fr_PsBlwSet 1500;
BA_ "Version" SG_ 68 HKBD_Fr_PsBlwSet "23.12.02";
BA_ "GenSigSendType" SG_ 68 HKBD_Fr_RrDrTempDnSw 4;
BA_ "UserSigValidity" SG_ 68 HKBD_Fr_RrDrTempDnSw 7;
BA_REL_ "GenSigTimeoutTime" BU_SG_REL_ L_ATCU SG_ 68 HKBD_Fr_RrDrTempDnSw 1500;
BA_ "Version" SG_ 68 HKBD_Fr_RrDrTempDnSw "23.08.13";
BA_ "GenSigSendType" SG_ 68 HKBD_Fr_RrDrTempUpSw 4;
BA_ "UserSigValidity" SG_ 68 HKBD_Fr_RrDrTempUpSw 7;
BA_REL_ "GenSigTimeoutTime" BU_SG_REL_ L_ATCU SG_ 68 HKBD_Fr_RrDrTempUpSw 1500;
BA_ "Version" SG_ 68 HKBD_Fr_RrDrTempUpSw "23.08.13";
BA_ "GenSigSendType" SG_ 68 HKBD_Fr_PsTempDnSw 4;
BA_ "UserSigValidity" SG_ 68 HKBD_Fr_PsTempDnSw 7;
BA_REL_ "GenSigTimeoutTime" BU_SG_REL_ L_ATCU SG_ 68 HKBD_Fr_PsTempDnSw 1500;
BA_ "Version" SG_ 68 HKBD_Fr_PsTempDnSw "23.08.13";
BA_ "GenSigSendType" SG_ 68 HKBD_Fr_RrDrBlwDnSw 4;
BA_ "UserSigValidity" SG_ 68 HKBD_Fr_RrDrBlwDnSw 7;
BA_REL_ "GenSigTimeoutTime" BU_SG_REL_ L_ATCU SG_ 68 HKBD_Fr_RrDrBlwDnSw 1500;
BA_ "Version" SG_ 68 HKBD_Fr_RrDrBlwDnSw "23.08.13";
BA_ "GenSigSendType" SG_ 68 HKBD_Fr_RrDrBlwDnOffSw 4;
BA_ "UserSigValidity" SG_ 68 HKBD_Fr_RrDrBlwDnOffSw 7;
BA_REL_ "GenSigTimeoutTime" BU_SG_REL_ L_ATCU SG_ 68 HKBD_Fr_RrDrBlwDnOffSw 1500;
BA_ "Version" SG_ 68 HKBD_Fr_RrDrBlwDnOffSw "23.08.13";
BA_ "GenSigSendType" SG_ 68 HKBD_Fr_RrDrBlwUpSw 4;
BA_ "UserSigValidity" SG_ 68 HKBD_Fr_RrDrBlwUpSw 7;
BA_REL_ "GenSigTimeoutTime" BU_SG_REL_ L_ATCU SG_ 68 HKBD_Fr_RrDrBlwUpSw 1500;
BA_ "Version" SG_ 68 HKBD_Fr_RrDrBlwUpSw "23.08.13";
BA_ "GenSigSendType" SG_ 68 HKBD_Fr_RrDrBlwSet 4;
BA_ "GenSigStartValue" SG_ 68 HKBD_Fr_RrDrBlwSet 15;
BA_ "UserSigValidity" SG_ 68 HKBD_Fr_RrDrBlwSet 7;
BA_REL_ "GenSigTimeoutTime" BU_SG_REL_ L_ATCU SG_ 68 HKBD_Fr_RrDrBlwSet 1500;
BA_ "Version" SG_ 68 HKBD_Fr_RrDrBlwSet "23.12.02";
BA_ "GenSigSendType" SG_ 68 HKBD_Fr_RrDrModDnSw 4;
BA_ "UserSigValidity" SG_ 68 HKBD_Fr_RrDrModDnSw 7;
BA_REL_ "GenSigTimeoutTime" BU_SG_REL_ L_ATCU SG_ 68 HKBD_Fr_RrDrModDnSw 1500;
BA_ "Version" SG_ 68 HKBD_Fr_RrDrModDnSw "23.08.13";
BA_ "GenSigSendType" SG_ 68 HKBD_Fr_RrDrModUpSw 4;
BA_ "UserSigValidity" SG_ 68 HKBD_Fr_RrDrModUpSw 7;
BA_REL_ "GenSigTimeoutTime" BU_SG_REL_ L_ATCU SG_ 68 HKBD_Fr_RrDrModUpSw 1500;
BA_ "Version" SG_ 68 HKBD_Fr_RrDrModUpSw "23.08.13";
BA_ "GenSigSendType" SG_ 68 HKBD_Fr_RrDrModVntSw 4;
BA_ "UserSigValidity" SG_ 68 HKBD_Fr_RrDrModVntSw 7;
BA_REL_ "GenSigTimeoutTime" BU_SG_REL_ L_ATCU SG_ 68 HKBD_Fr_RrDrModVntSw 1500;
BA_ "Version" SG_ 68 HKBD_Fr_RrDrModVntSw "23.08.13";
BA_ "GenSigSendType" SG_ 68 HKBD_Fr_PsTempUpSw 4;
BA_ "UserSigValidity" SG_ 68 HKBD_Fr_PsTempUpSw 7;
BA_REL_ "GenSigTimeoutTime" BU_SG_REL_ L_ATCU SG_ 68 HKBD_Fr_PsTempUpSw 1500;
BA_ "Version" SG_ 68 HKBD_Fr_PsTempUpSw "23.08.13";
BA_ "GenSigSendType" SG_ 68 HKBD_Fr_RrDrModFlrSw 4;
BA_ "UserSigValidity" SG_ 68 HKBD_Fr_RrDrModFlrSw 7;
BA_REL_ "GenSigTimeoutTime" BU_SG_REL_ L_ATCU SG_ 68 HKBD_Fr_RrDrModFlrSw 1500;
BA_ "Version" SG_ 68 HKBD_Fr_RrDrModFlrSw "23.08.13";
BA_ "GenSigSendType" SG_ 68 HKBD_Fr_RrDrModBiLvlSw 4;
BA_ "UserSigValidity" SG_ 68 HKBD_Fr_RrDrModBiLvlSw 7;
BA_REL_ "GenSigTimeoutTime" BU_SG_REL_ L_ATCU SG_ 68 HKBD_Fr_RrDrModBiLvlSw 1500;
BA_ "Version" SG_ 68 HKBD_Fr_RrDrModBiLvlSw "23.08.13";
BA_ "GenSigSendType" SG_ 68 HKBD_Fr_RrDrAutoSw 4;
BA_ "UserSigValidity" SG_ 68 HKBD_Fr_RrDrAutoSw 7;
BA_REL_ "GenSigTimeoutTime" BU_SG_REL_ L_ATCU SG_ 68 HKBD_Fr_RrDrAutoSw 1500;
BA_ "Version" SG_ 68 HKBD_Fr_RrDrAutoSw "23.08.13";
BA_ "GenSigSendType" SG_ 68 HKBD_Fr_RrDrMultiAutoSw 4;
BA_ "GenSigStartValue" SG_ 68 HKBD_Fr_RrDrMultiAutoSw 15;
BA_ "UserSigValidity" SG_ 68 HKBD_Fr_RrDrMultiAutoSw 7;
BA_REL_ "GenSigTimeoutTime" BU_SG_REL_ L_ATCU SG_ 68 HKBD_Fr_RrDrMultiAutoSw 1500;
BA_ "Version" SG_ 68 HKBD_Fr_RrDrMultiAutoSw "23.12.02";
BA_ "GenSigSendType" SG_ 68 HKBD_Fr_RrOffSw 4;
BA_ "UserSigValidity" SG_ 68 HKBD_Fr_RrOffSw 7;
BA_REL_ "GenSigTimeoutTime" BU_SG_REL_ L_ATCU SG_ 68 HKBD_Fr_RrOffSw 1500;
BA_ "Version" SG_ 68 HKBD_Fr_RrOffSw "23.08.13";
BA_ "GenSigSendType" SG_ 68 HKBD_Fr_RrSyncSw 4;
BA_ "UserSigValidity" SG_ 68 HKBD_Fr_RrSyncSw 7;
BA_REL_ "GenSigTimeoutTime" BU_SG_REL_ L_ATCU SG_ 68 HKBD_Fr_RrSyncSw 1500;
BA_ "Version" SG_ 68 HKBD_Fr_RrSyncSw "23.08.13";
BA_ "GenSigSendType" SG_ 68 HKBD_Fr_RLStHeatSw 4;
BA_ "UserSigValidity" SG_ 68 HKBD_Fr_RLStHeatSw 7;
BA_REL_ "GenSigTimeoutTime" BU_SG_REL_ L_ATCU SG_ 68 HKBD_Fr_RLStHeatSw 1500;
BA_ "Version" SG_ 68 HKBD_Fr_RLStHeatSw "23.08.13";
BA_ "GenSigSendType" SG_ 68 HKBD_Fr_RLStVentSw 4;
BA_ "UserSigValidity" SG_ 68 HKBD_Fr_RLStVentSw 7;
BA_REL_ "GenSigTimeoutTime" BU_SG_REL_ L_ATCU SG_ 68 HKBD_Fr_RLStVentSw 1500;
BA_ "Version" SG_ 68 HKBD_Fr_RLStVentSw "23.08.13";
BA_ "GenSigSendType" SG_ 68 HKBD_Fr_DrBlwDnSw 4;
BA_ "UserSigValidity" SG_ 68 HKBD_Fr_DrBlwDnSw 7;
BA_REL_ "GenSigTimeoutTime" BU_SG_REL_ L_ATCU SG_ 68 HKBD_Fr_DrBlwDnSw 1500;
BA_ "Version" SG_ 68 HKBD_Fr_DrBlwDnSw "23.08.13";
BA_ "GenSigSendType" SG_ 68 HKBD_Fr_RRStHeatSw 4;
BA_ "UserSigValidity" SG_ 68 HKBD_Fr_RRStHeatSw 7;
BA_REL_ "GenSigTimeoutTime" BU_SG_REL_ L_ATCU SG_ 68 HKBD_Fr_RRStHeatSw 1500;
BA_ "Version" SG_ 68 HKBD_Fr_RRStHeatSw "23.08.13";
BA_ "GenSigSendType" SG_ 68 HKBD_Fr_RRStVentSw 4;
BA_ "UserSigValidity" SG_ 68 HKBD_Fr_RRStVentSw 7;
BA_REL_ "GenSigTimeoutTime" BU_SG_REL_ L_ATCU SG_ 68 HKBD_Fr_RRStVentSw 1500;
BA_ "Version" SG_ 68 HKBD_Fr_RRStVentSw "23.08.13";
BA_ "GenSigSendType" SG_ 68 HKBD_Fr_RLStTumblrSw 4;
BA_ "UserSigValidity" SG_ 68 HKBD_Fr_RLStTumblrSw 7;
BA_REL_ "GenSigTimeoutTime" BU_SG_REL_ L_ATCU SG_ 68 HKBD_Fr_RLStTumblrSw 1500;
BA_ "Version" SG_ 68 HKBD_Fr_RLStTumblrSw "23.08.13";
BA_ "GenSigSendType" SG_ 68 HKBD_Fr_RRStTumblrSw 4;
BA_ "UserSigValidity" SG_ 68 HKBD_Fr_RRStTumblrSw 7;
BA_REL_ "GenSigTimeoutTime" BU_SG_REL_ L_ATCU SG_ 68 HKBD_Fr_RRStTumblrSw 1500;
BA_ "Version" SG_ 68 HKBD_Fr_RRStTumblrSw "23.08.13";
BA_ "GenSigSendType" SG_ 68 HKBD_Fr_RrPsModDnSw 4;
BA_ "UserSigValidity" SG_ 68 HKBD_Fr_RrPsModDnSw 7;
BA_REL_ "GenSigTimeoutTime" BU_SG_REL_ L_ATCU SG_ 68 HKBD_Fr_RrPsModDnSw 1500;
BA_ "Version" SG_ 68 HKBD_Fr_RrPsModDnSw "23.08.13";
BA_ "GenSigSendType" SG_ 68 HKBD_Fr_RrPsModUpSw 4;
BA_ "UserSigValidity" SG_ 68 HKBD_Fr_RrPsModUpSw 7;
BA_REL_ "GenSigTimeoutTime" BU_SG_REL_ L_ATCU SG_ 68 HKBD_Fr_RrPsModUpSw 1500;
BA_ "Version" SG_ 68 HKBD_Fr_RrPsModUpSw "23.08.13";
BA_ "GenSigSendType" SG_ 68 HKBD_Fr_RrPsModVntSw 4;
BA_ "UserSigValidity" SG_ 68 HKBD_Fr_RrPsModVntSw 7;
BA_REL_ "GenSigTimeoutTime" BU_SG_REL_ L_ATCU SG_ 68 HKBD_Fr_RrPsModVntSw 1500;
BA_ "Version" SG_ 68 HKBD_Fr_RrPsModVntSw "23.08.13";
BA_ "GenSigSendType" SG_ 68 HKBD_Fr_RrPsModFlrSw 4;
BA_ "UserSigValidity" SG_ 68 HKBD_Fr_RrPsModFlrSw 7;
BA_REL_ "GenSigTimeoutTime" BU_SG_REL_ L_ATCU SG_ 68 HKBD_Fr_RrPsModFlrSw 1500;
BA_ "Version" SG_ 68 HKBD_Fr_RrPsModFlrSw "23.08.13";
BA_ "GenSigSendType" SG_ 68 HKBD_Fr_DrBlwDnOffSw 4;
BA_ "UserSigValidity" SG_ 68 HKBD_Fr_DrBlwDnOffSw 7;
BA_REL_ "GenSigTimeoutTime" BU_SG_REL_ L_ATCU SG_ 68 HKBD_Fr_DrBlwDnOffSw 1500;
BA_ "Version" SG_ 68 HKBD_Fr_DrBlwDnOffSw "23.08.13";
BA_ "GenSigSendType" SG_ 68 HKBD_Fr_RrLockSw 4;
BA_ "UserSigValidity" SG_ 68 HKBD_Fr_RrLockSw 7;
BA_REL_ "GenSigTimeoutTime" BU_SG_REL_ L_ATCU SG_ 68 HKBD_Fr_RrLockSw 1500;
BA_ "Version" SG_ 68 HKBD_Fr_RrLockSw "23.08.13";
BA_ "GenSigSendType" SG_ 68 HKBD_Fr_RrPsModBiLvlSw 4;
BA_ "UserSigValidity" SG_ 68 HKBD_Fr_RrPsModBiLvlSw 7;
BA_REL_ "GenSigTimeoutTime" BU_SG_REL_ L_ATCU SG_ 68 HKBD_Fr_RrPsModBiLvlSw 1500;
BA_ "Version" SG_ 68 HKBD_Fr_RrPsModBiLvlSw "23.08.13";
BA_ "GenSigSendType" SG_ 68 HKBD_Fr_RrDrModSw 4;
BA_ "UserSigValidity" SG_ 68 HKBD_Fr_RrDrModSw 7;
BA_REL_ "GenSigTimeoutTime" BU_SG_REL_ L_ATCU SG_ 68 HKBD_Fr_RrDrModSw 1500;
BA_ "Version" SG_ 68 HKBD_Fr_RrDrModSw "23.08.13";
BA_ "GenSigSendType" SG_ 68 HKBD_Fr_RrPsModSw 4;
BA_ "UserSigValidity" SG_ 68 HKBD_Fr_RrPsModSw 7;
BA_REL_ "GenSigTimeoutTime" BU_SG_REL_ L_ATCU SG_ 68 HKBD_Fr_RrPsModSw 1500;
BA_ "Version" SG_ 68 HKBD_Fr_RrPsModSw "23.08.13";
BA_ "GenSigSendType" SG_ 68 HKBD_Fr_RrPsBlwSet 4;
BA_ "GenSigStartValue" SG_ 68 HKBD_Fr_RrPsBlwSet 15;
BA_ "UserSigValidity" SG_ 68 HKBD_Fr_RrPsBlwSet 7;
BA_REL_ "GenSigTimeoutTime" BU_SG_REL_ L_ATCU SG_ 68 HKBD_Fr_RrPsBlwSet 1500;
BA_ "Version" SG_ 68 HKBD_Fr_RrPsBlwSet "23.12.02";
BA_ "GenSigSendType" SG_ 68 HKBD_Fr_RrPsBlwUpSw 4;
BA_ "UserSigValidity" SG_ 68 HKBD_Fr_RrPsBlwUpSw 7;
BA_REL_ "GenSigTimeoutTime" BU_SG_REL_ L_ATCU SG_ 68 HKBD_Fr_RrPsBlwUpSw 1500;
BA_ "Version" SG_ 68 HKBD_Fr_RrPsBlwUpSw "23.08.13";
BA_ "GenSigSendType" SG_ 68 HKBD_Fr_RrPsBlwDnSw 4;
BA_ "UserSigValidity" SG_ 68 HKBD_Fr_RrPsBlwDnSw 7;
BA_REL_ "GenSigTimeoutTime" BU_SG_REL_ L_ATCU SG_ 68 HKBD_Fr_RrPsBlwDnSw 1500;
BA_ "Version" SG_ 68 HKBD_Fr_RrPsBlwDnSw "23.08.13";
BA_ "GenSigSendType" SG_ 68 HKBD_Fr_DrBlwUpSw 4;
BA_ "UserSigValidity" SG_ 68 HKBD_Fr_DrBlwUpSw 7;
BA_REL_ "GenSigTimeoutTime" BU_SG_REL_ L_ATCU SG_ 68 HKBD_Fr_DrBlwUpSw 1500;
BA_ "Version" SG_ 68 HKBD_Fr_DrBlwUpSw "23.08.13";
BA_ "GenSigSendType" SG_ 68 HKBD_Fr_RrPsBlwDnOffSw 4;
BA_ "UserSigValidity" SG_ 68 HKBD_Fr_RrPsBlwDnOffSw 7;
BA_REL_ "GenSigTimeoutTime" BU_SG_REL_ L_ATCU SG_ 68 HKBD_Fr_RrPsBlwDnOffSw 1500;
BA_ "Version" SG_ 68 HKBD_Fr_RrPsBlwDnOffSw "23.08.13";
BA_ "GenSigSendType" SG_ 68 HKBD_Fr_RrPsTempDnSw 4;
BA_ "UserSigValidity" SG_ 68 HKBD_Fr_RrPsTempDnSw 7;
BA_REL_ "GenSigTimeoutTime" BU_SG_REL_ L_ATCU SG_ 68 HKBD_Fr_RrPsTempDnSw 1500;
BA_ "Version" SG_ 68 HKBD_Fr_RrPsTempDnSw "23.08.13";
BA_ "GenSigSendType" SG_ 68 HKBD_Fr_RrPsTempUpSw 4;
BA_ "UserSigValidity" SG_ 68 HKBD_Fr_RrPsTempUpSw 7;
BA_REL_ "GenSigTimeoutTime" BU_SG_REL_ L_ATCU SG_ 68 HKBD_Fr_RrPsTempUpSw 1500;
BA_ "Version" SG_ 68 HKBD_Fr_RrPsTempUpSw "23.08.13";
BA_ "GenSigSendType" SG_ 68 HKBD_Fr_DrBlwSet 4;
BA_ "GenSigStartValue" SG_ 68 HKBD_Fr_DrBlwSet 15;
BA_ "UserSigValidity" SG_ 68 HKBD_Fr_DrBlwSet 7;
BA_REL_ "GenSigTimeoutTime" BU_SG_REL_ L_ATCU SG_ 68 HKBD_Fr_DrBlwSet 1500;
BA_ "Version" SG_ 68 HKBD_Fr_DrBlwSet "23.12.02";
BA_ "GenMsgSendType" BO_ 69 0;
BA_ "GenSigSendType" SG_ 69 HKBD_Fr_3rdRrTempDnSw 4;
BA_ "UserSigValidity" SG_ 69 HKBD_Fr_3rdRrTempDnSw 7;
BA_REL_ "GenSigTimeoutTime" BU_SG_REL_ L_ATCU SG_ 69 HKBD_Fr_3rdRrTempDnSw 1500;
BA_ "Version" SG_ 69 HKBD_Fr_3rdRrTempDnSw "23.08.13";
BA_ "GenSigSendType" SG_ 69 HKBD_Fr_3rdRrTempUpSw 4;
BA_ "UserSigValidity" SG_ 69 HKBD_Fr_3rdRrTempUpSw 7;
BA_REL_ "GenSigTimeoutTime" BU_SG_REL_ L_ATCU SG_ 69 HKBD_Fr_3rdRrTempUpSw 1500;
BA_ "Version" SG_ 69 HKBD_Fr_3rdRrTempUpSw "23.08.13";
BA_ "GenSigSendType" SG_ 69 HKBD_Fr_3rdRrModUpSw 4;
BA_ "UserSigValidity" SG_ 69 HKBD_Fr_3rdRrModUpSw 7;
BA_REL_ "GenSigTimeoutTime" BU_SG_REL_ L_ATCU SG_ 69 HKBD_Fr_3rdRrModUpSw 1500;
BA_ "Version" SG_ 69 HKBD_Fr_3rdRrModUpSw "23.08.13";
BA_ "GenSigSendType" SG_ 69 HKBD_Fr_3rdRrModVntSw 4;
BA_ "UserSigValidity" SG_ 69 HKBD_Fr_3rdRrModVntSw 7;
BA_REL_ "GenSigTimeoutTime" BU_SG_REL_ L_ATCU SG_ 69 HKBD_Fr_3rdRrModVntSw 1500;
BA_ "Version" SG_ 69 HKBD_Fr_3rdRrModVntSw "23.08.13";
BA_ "GenSigSendType" SG_ 69 HKBD_Fr_3rdRrModFlrSw 4;
BA_ "UserSigValidity" SG_ 69 HKBD_Fr_3rdRrModFlrSw 7;
BA_REL_ "GenSigTimeoutTime" BU_SG_REL_ L_ATCU SG_ 69 HKBD_Fr_3rdRrModFlrSw 1500;
BA_ "Version" SG_ 69 HKBD_Fr_3rdRrModFlrSw "23.08.13";
BA_ "GenSigSendType" SG_ 69 HKBD_Fr_3rdRrAutoSw 4;
BA_ "UserSigValidity" SG_ 69 HKBD_Fr_3rdRrAutoSw 7;
BA_REL_ "GenSigTimeoutTime" BU_SG_REL_ L_ATCU SG_ 69 HKBD_Fr_3rdRrAutoSw 1500;
BA_ "Version" SG_ 69 HKBD_Fr_3rdRrAutoSw "23.08.13";
BA_ "GenSigSendType" SG_ 69 HKBD_Fr_3rdRrMultiAutoSw 4;
BA_ "GenSigStartValue" SG_ 69 HKBD_Fr_3rdRrMultiAutoSw 7;
BA_ "UserSigValidity" SG_ 69 HKBD_Fr_3rdRrMultiAutoSw 7;
BA_REL_ "GenSigTimeoutTime" BU_SG_REL_ L_ATCU SG_ 69 HKBD_Fr_3rdRrMultiAutoSw 1500;
BA_ "Version" SG_ 69 HKBD_Fr_3rdRrMultiAutoSw "23.12.02";
BA_ "GenSigSendType" SG_ 69 HKBD_Fr_3rdRrOffSw 4;
BA_ "UserSigValidity" SG_ 69 HKBD_Fr_3rdRrOffSw 7;
BA_REL_ "GenSigTimeoutTime" BU_SG_REL_ L_ATCU SG_ 69 HKBD_Fr_3rdRrOffSw 1500;
BA_ "Version" SG_ 69 HKBD_Fr_3rdRrOffSw "23.08.13";
BA_ "GenSigSendType" SG_ 69 HKBD_Fr_3rdRrSyncSw 4;
BA_ "UserSigValidity" SG_ 69 HKBD_Fr_3rdRrSyncSw 7;
BA_REL_ "GenSigTimeoutTime" BU_SG_REL_ L_ATCU SG_ 69 HKBD_Fr_3rdRrSyncSw 1500;
BA_ "Version" SG_ 69 HKBD_Fr_3rdRrSyncSw "23.08.13";
BA_ "GenSigSendType" SG_ 69 HKBD_Fr_3rdRrLockSw 4;
BA_ "UserSigValidity" SG_ 69 HKBD_Fr_3rdRrLockSw 7;
BA_REL_ "GenSigTimeoutTime" BU_SG_REL_ L_ATCU SG_ 69 HKBD_Fr_3rdRrLockSw 1500;
BA_ "Version" SG_ 69 HKBD_Fr_3rdRrLockSw "23.08.13";
BA_ "GenSigSendType" SG_ 69 HKBD_Fr_3rdRrBlwDnSw 4;
BA_ "UserSigValidity" SG_ 69 HKBD_Fr_3rdRrBlwDnSw 7;
BA_REL_ "GenSigTimeoutTime" BU_SG_REL_ L_ATCU SG_ 69 HKBD_Fr_3rdRrBlwDnSw 1500;
BA_ "Version" SG_ 69 HKBD_Fr_3rdRrBlwDnSw "23.08.13";
BA_ "GenSigSendType" SG_ 69 HKBD_Fr_3rdRrModBiLvlSw 4;
BA_ "UserSigValidity" SG_ 69 HKBD_Fr_3rdRrModBiLvlSw 7;
BA_REL_ "GenSigTimeoutTime" BU_SG_REL_ L_ATCU SG_ 69 HKBD_Fr_3rdRrModBiLvlSw 1500;
BA_ "Version" SG_ 69 HKBD_Fr_3rdRrModBiLvlSw "23.08.13";
BA_ "GenSigSendType" SG_ 69 HKBD_FrRrTglSet 4;
BA_ "UserSigValidity" SG_ 69 HKBD_FrRrTglSet 7;
BA_REL_ "GenSigTimeoutTime" BU_SG_REL_ L_ATCU SG_ 69 HKBD_FrRrTglSet 1500;
BA_ "Version" SG_ 69 HKBD_FrRrTglSet "23.11.06";
BA_ "GenSigSendType" SG_ 69 HKBD_Fr_RrScrnSet 4;
BA_ "UserSigValidity" SG_ 69 HKBD_Fr_RrScrnSet 7;
BA_REL_ "GenSigTimeoutTime" BU_SG_REL_ L_ATCU SG_ 69 HKBD_Fr_RrScrnSet 1500;
BA_ "Version" SG_ 69 HKBD_Fr_RrScrnSet "23.12.02";
BA_ "GenSigSendType" SG_ 69 HKBD_Fr_OnOffSet 4;
BA_ "UserSigValidity" SG_ 69 HKBD_Fr_OnOffSet 7;
BA_REL_ "GenSigTimeoutTime" BU_SG_REL_ L_ATCU SG_ 69 HKBD_Fr_OnOffSet 1500;
BA_ "Version" SG_ 69 HKBD_Fr_OnOffSet "23.08.13";
BA_ "GenSigSendType" SG_ 69 HKBD_Fr_RrOnOffSet 4;
BA_ "UserSigValidity" SG_ 69 HKBD_Fr_RrOnOffSet 7;
BA_REL_ "GenSigTimeoutTime" BU_SG_REL_ L_ATCU SG_ 69 HKBD_Fr_RrOnOffSet 1500;
BA_ "Version" SG_ 69 HKBD_Fr_RrOnOffSet "23.08.13";
BA_ "GenSigSendType" SG_ 69 HKBD_Fr_3rdRrOnOffSet 4;
BA_ "UserSigValidity" SG_ 69 HKBD_Fr_3rdRrOnOffSet 7;
BA_REL_ "GenSigTimeoutTime" BU_SG_REL_ L_ATCU SG_ 69 HKBD_Fr_3rdRrOnOffSet 1500;
BA_ "Version" SG_ 69 HKBD_Fr_3rdRrOnOffSet "23.12.02";
BA_ "GenSigSendType" SG_ 69 HKBD_Fr_3rdRrBlwDnOffSw 4;
BA_ "UserSigValidity" SG_ 69 HKBD_Fr_3rdRrBlwDnOffSw 7;
BA_REL_ "GenSigTimeoutTime" BU_SG_REL_ L_ATCU SG_ 69 HKBD_Fr_3rdRrBlwDnOffSw 1500;
BA_ "Version" SG_ 69 HKBD_Fr_3rdRrBlwDnOffSw "23.08.13";
BA_ "GenSigSendType" SG_ 69 HKBD_Fr_RrPsAutoSw 4;
BA_ "UserSigValidity" SG_ 69 HKBD_Fr_RrPsAutoSw 7;
BA_REL_ "GenSigTimeoutTime" BU_SG_REL_ L_ATCU SG_ 69 HKBD_Fr_RrPsAutoSw 1500;
BA_ "Version" SG_ 69 HKBD_Fr_RrPsAutoSw "23.08.13";
BA_ "GenSigSendType" SG_ 69 HKBD_Fr_RrPsMultiAutoSw 4;
BA_ "GenSigStartValue" SG_ 69 HKBD_Fr_RrPsMultiAutoSw 7;
BA_ "UserSigValidity" SG_ 69 HKBD_Fr_RrPsMultiAutoSw 7;
BA_REL_ "GenSigTimeoutTime" BU_SG_REL_ L_ATCU SG_ 69 HKBD_Fr_RrPsMultiAutoSw 1500;
BA_ "Version" SG_ 69 HKBD_Fr_RrPsMultiAutoSw "23.12.02";
BA_ "GenSigSendType" SG_ 69 HKBD_Fr_3rdRrModSw 4;
BA_ "UserSigValidity" SG_ 69 HKBD_Fr_3rdRrModSw 7;
BA_REL_ "GenSigTimeoutTime" BU_SG_REL_ L_ATCU SG_ 69 HKBD_Fr_3rdRrModSw 1500;
BA_ "Version" SG_ 69 HKBD_Fr_3rdRrModSw "23.08.13";
BA_ "GenSigSendType" SG_ 69 HKBD_Fr_3rdRrBlwUpSw 4;
BA_ "UserSigValidity" SG_ 69 HKBD_Fr_3rdRrBlwUpSw 7;
BA_REL_ "GenSigTimeoutTime" BU_SG_REL_ L_ATCU SG_ 69 HKBD_Fr_3rdRrBlwUpSw 1500;
BA_ "Version" SG_ 69 HKBD_Fr_3rdRrBlwUpSw "23.08.13";
BA_ "GenSigSendType" SG_ 69 HKBD_Fr_3rdRrBlwSet 4;
BA_ "GenSigStartValue" SG_ 69 HKBD_Fr_3rdRrBlwSet 15;
BA_ "UserSigValidity" SG_ 69 HKBD_Fr_3rdRrBlwSet 7;
BA_REL_ "GenSigTimeoutTime" BU_SG_REL_ L_ATCU SG_ 69 HKBD_Fr_3rdRrBlwSet 1500;
BA_ "Version" SG_ 69 HKBD_Fr_3rdRrBlwSet "23.12.02";
BA_ "GenSigSendType" SG_ 69 HKBD_Fr_3rdRrModDnSw 4;
BA_ "UserSigValidity" SG_ 69 HKBD_Fr_3rdRrModDnSw 7;
BA_REL_ "GenSigTimeoutTime" BU_SG_REL_ L_ATCU SG_ 69 HKBD_Fr_3rdRrModDnSw 1500;
BA_ "Version" SG_ 69 HKBD_Fr_3rdRrModDnSw "23.08.13";
BA_ "GenMsgSendType" BO_ 70 0;
BA_ "GenMsgCycleTime" BO_ 70 500;
BA_ "Description" SG_ 70 HKBD_SwBtnTyp "Each bit for button type is defined as

0-None/1-Hardkey/2-Touch(Used Beep)/3-Touch(Not Used Beep)

Bit 0~1 (Temp Button)/Bit 2~3 (Blower Button)/Bit 4~5 (Mode Button)/

Bit 6~7 (Auto Button)/Bit 8~9 (A/C Button)/Bit 10~11 (Def Button)/

Bit 12~13 (Intake Button)/Bit 14~15 (Sync Button)/Bit 16~17 (RrDef Button)/

Bit 18~19 (DrOnly Button)/Bit 20~21 (AirCln Button)/Bit 22~23 (StHeatVnt Button)/

Bit 24~25 (StrWhlHeat Button)/Bit 26~27 (FrWndShldHt Button)/

Bit 28~29 (Diffuser Button)/Bit 30~31 (OFF Button)/Bit 32~33 (Climate Button)

Bit 34~35 (FrRrTgl Button)

Bit36~37 (SmartZone Button) : 0 ? None / 1 ? HardKey / 2 ? Touch(Used Beep) / 3 ? Touch (Not Used Beep)

Bit 38~39 : Reserved";
BA_ "GenSigSendType" SG_ 70 HKBD_SwBtnTyp 4;
BA_ "UserSigValidity" SG_ 70 HKBD_SwBtnTyp 7;
BA_REL_ "GenSigTimeoutTime" BU_SG_REL_ L_ATCU SG_ 70 HKBD_SwBtnTyp 5000;
BA_ "Version" SG_ 70 HKBD_SwBtnTyp "24.11.00";
BA_ "Description" SG_ 70 L_HKBD_ResetOpSta "This signal indicates whether the reset operation has been completed or not";
BA_ "GenSigSendType" SG_ 70 L_HKBD_ResetOpSta 4;
BA_ "UserSigValidity" SG_ 70 L_HKBD_ResetOpSta 0;
BA_REL_ "GenSigTimeoutTime" BU_SG_REL_ L_ATCU SG_ 70 L_HKBD_ResetOpSta 1000;
BA_ "Version" SG_ 70 L_HKBD_ResetOpSta "24.10.05";
BA_ "GenMsgCycleTime" BO_ 71 0;
BA_ "GenSigSendType" SG_ 71 HKBD_Fr_RrDrTempClickCnt 4;
BA_ "GenSigStartValue" SG_ 71 HKBD_Fr_RrDrTempClickCnt 255;
BA_ "UserSigValidity" SG_ 71 HKBD_Fr_RrDrTempClickCnt 7;
BA_REL_ "GenSigTimeoutTime" BU_SG_REL_ L_ATCU SG_ 71 HKBD_Fr_RrDrTempClickCnt 0;
BA_ "Version" SG_ 71 HKBD_Fr_RrDrTempClickCnt "23.12.02";
BA_ "GenSigSendType" SG_ 71 HKBD_Fr_RrPsTempClickCnt 4;
BA_ "GenSigStartValue" SG_ 71 HKBD_Fr_RrPsTempClickCnt 255;
BA_ "UserSigValidity" SG_ 71 HKBD_Fr_RrPsTempClickCnt 7;
BA_REL_ "GenSigTimeoutTime" BU_SG_REL_ L_ATCU SG_ 71 HKBD_Fr_RrPsTempClickCnt 0;
BA_ "Version" SG_ 71 HKBD_Fr_RrPsTempClickCnt "23.12.02";
BA_ "GenSigSendType" SG_ 71 HKBD_Fr_RrPsBlwClickCnt 4;
BA_ "GenSigStartValue" SG_ 71 HKBD_Fr_RrPsBlwClickCnt 255;
BA_ "UserSigValidity" SG_ 71 HKBD_Fr_RrPsBlwClickCnt 7;
BA_REL_ "GenSigTimeoutTime" BU_SG_REL_ L_ATCU SG_ 71 HKBD_Fr_RrPsBlwClickCnt 0;
BA_ "Version" SG_ 71 HKBD_Fr_RrPsBlwClickCnt "23.12.02";
BA_ "GenSigSendType" SG_ 71 HKBD_Fr_3rdRrTempClickCnt 4;
BA_ "GenSigStartValue" SG_ 71 HKBD_Fr_3rdRrTempClickCnt 255;
BA_ "UserSigValidity" SG_ 71 HKBD_Fr_3rdRrTempClickCnt 7;
BA_REL_ "GenSigTimeoutTime" BU_SG_REL_ L_ATCU SG_ 71 HKBD_Fr_3rdRrTempClickCnt 0;
BA_ "Version" SG_ 71 HKBD_Fr_3rdRrTempClickCnt "23.12.02";
BA_ "GenSigSendType" SG_ 71 HKBD_Fr_3rdRrBlwClickCnt 4;
BA_ "GenSigStartValue" SG_ 71 HKBD_Fr_3rdRrBlwClickCnt 255;
BA_ "UserSigValidity" SG_ 71 HKBD_Fr_3rdRrBlwClickCnt 7;
BA_REL_ "GenSigTimeoutTime" BU_SG_REL_ L_ATCU SG_ 71 HKBD_Fr_3rdRrBlwClickCnt 0;
BA_ "Version" SG_ 71 HKBD_Fr_3rdRrBlwClickCnt "23.12.02";
BA_ "GenSigSendType" SG_ 71 HKBD_Fr_RrTempKnobCnt 4;
BA_ "GenSigStartValue" SG_ 71 HKBD_Fr_RrTempKnobCnt 3;
BA_ "UserSigValidity" SG_ 71 HKBD_Fr_RrTempKnobCnt 7;
BA_REL_ "GenSigTimeoutTime" BU_SG_REL_ L_ATCU SG_ 71 HKBD_Fr_RrTempKnobCnt 0;
BA_ "Version" SG_ 71 HKBD_Fr_RrTempKnobCnt "23.12.02";
BA_ "GenSigSendType" SG_ 71 HKBD_Fr_RrBlwKnobCnt 4;
BA_ "GenSigStartValue" SG_ 71 HKBD_Fr_RrBlwKnobCnt 3;
BA_ "UserSigValidity" SG_ 71 HKBD_Fr_RrBlwKnobCnt 7;
BA_REL_ "GenSigTimeoutTime" BU_SG_REL_ L_ATCU SG_ 71 HKBD_Fr_RrBlwKnobCnt 0;
BA_ "Version" SG_ 71 HKBD_Fr_RrBlwKnobCnt "23.12.02";
BA_ "GenSigSendType" SG_ 71 HKBD_Fr_3rdTempKnobCnt 4;
BA_ "GenSigStartValue" SG_ 71 HKBD_Fr_3rdTempKnobCnt 3;
BA_ "UserSigValidity" SG_ 71 HKBD_Fr_3rdTempKnobCnt 7;
BA_REL_ "GenSigTimeoutTime" BU_SG_REL_ L_ATCU SG_ 71 HKBD_Fr_3rdTempKnobCnt 0;
BA_ "Version" SG_ 71 HKBD_Fr_3rdTempKnobCnt "23.12.02";
BA_ "GenSigSendType" SG_ 71 HKBD_Fr_3rdBlwKnobCnt 4;
BA_ "GenSigStartValue" SG_ 71 HKBD_Fr_3rdBlwKnobCnt 3;
BA_ "UserSigValidity" SG_ 71 HKBD_Fr_3rdBlwKnobCnt 7;
BA_REL_ "GenSigTimeoutTime" BU_SG_REL_ L_ATCU SG_ 71 HKBD_Fr_3rdBlwKnobCnt 0;
BA_ "Version" SG_ 71 HKBD_Fr_3rdBlwKnobCnt "23.12.02";
BA_ "GenSigSendType" SG_ 71 HKBD_Fr_RrDrBlwClickCnt 4;
BA_ "GenSigStartValue" SG_ 71 HKBD_Fr_RrDrBlwClickCnt 255;
BA_ "UserSigValidity" SG_ 71 HKBD_Fr_RrDrBlwClickCnt 7;
BA_REL_ "GenSigTimeoutTime" BU_SG_REL_ L_ATCU SG_ 71 HKBD_Fr_RrDrBlwClickCnt 0;
BA_ "Version" SG_ 71 HKBD_Fr_RrDrBlwClickCnt "23.12.02";
BA_ "GenMsgSendType" BO_ 72 0;
BA_ "GenMsgCycleTime" BO_ 72 20;
BA_ "GenMsgCycleTimeFast" BO_ 72 0;
BA_ "GenMsgNrOfRepetition" BO_ 72 0;
BA_ "GenMsgDelayTime" BO_ 72 0;
BA_ "UserSigValidity" SG_ 72 HKBD_Fr_IncarRaw 7;
BA_ "Version" SG_ 72 HKBD_Fr_IncarRaw "23.08.13";
VAL_ 33 L_ATCU_Typ1 0 "Defualt" 1 "Domestic" 2 "General or MiddleEast or Australia" 3 "Europe or Russia" 4 "America" 5 "Canada" 6 "China" 7 "India" 8 "Invalid" 9 "Invalid" 10 "Invalid" 11 "Invalid" 12 "Invalid" 13 "Invalid" 14 "Invalid" 15 "Invalid" ;
VAL_ 33 L_ATCU_TempDispSta 0 "OLD Set Temp Display range" 1 "NEW Set Temp Display Range(Default)" 2 "None Heater Set Temp Display Range" 3 "Error Indicator" ;
VAL_ 33 L_ATCU_StrgWhlHeatingOpt 0 "Not Applied" 1 "Applied(steering wheel applied)" 2 "RESERVED" 3 "Invalid" ;
VAL_ 33 L_ATCU_Drv_SeatOptSta 0 "Init" 1 "Heater only 2step" 2 "Heater only 3step" 3 "Vent only 2step" 4 "Vent only 3step" 5 "Heater and Vent 2step" 6 "Heater and Vent 3step" 7 "Invalid" ;
VAL_ 33 L_ATCU_Ast_SeatOptSta 0 "Init" 1 "Heater only 2step" 2 "Heater only 3step" 3 "Vent only 2step" 4 "Vent only 3step" 5 "Heater and Vent 2step" 6 "Heater and Vent 3step" 7 "Invalid" ;
VAL_ 33 L_ATCU_RL_SeatOptSta 0 "Init" 1 "Heater only 2step" 2 "Heater only 3step" 3 "Vent only 2step" 4 "Vent only 3step" 5 "Heater and Vent 2step" 6 "Heater and Vent 3step" 7 "Invalid" ;
VAL_ 33 L_ATCU_RR_SeatOptSta 0 "Init" 1 "Heater only 2step" 2 "Heater only 3step" 3 "Vent only 2step" 4 "Vent only 3step" 5 "Heater and Vent 2step" 6 "Heater and Vent 3step" 7 "Invalid" ;
VAL_ 33 L_ATCU_SmartZoneDis 0 "Default" 1 "On" 2 "Off" 3 "Invalid" ;
VAL_ 34 L_ATCU_DrTempCDis 0 "Blank Display (Default)" 1 "'LO' Display" 2 "15.0¡É~32.0¡É" 3 "15.0¡É~32.0¡É" 4 "15.0¡É~32.0¡É" 5 "15.0¡É~32.0¡É" 6 "15.0¡É~32.0¡É" 7 "15.0¡É~32.0¡É" 8 "15.0¡É~32.0¡É" 9 "15.0¡É~32.0¡É" 10 "15.0¡É~32.0¡É" 11 "15.0¡É~32.0¡É" 12 "15.0¡É~32.0¡É" 13 "15.0¡É~32.0¡É" 14 "15.0¡É~32.0¡É" 15 "15.0¡É~32.0¡É" 16 "15.0¡É~32.0¡É" 17 "15.0¡É~32.0¡É" 18 "15.0¡É~32.0¡É" 19 "15.0¡É~32.0¡É" 20 "15.0¡É~32.0¡É" 21 "15.0¡É~32.0¡É" 22 "15.0¡É~32.0¡É" 23 "15.0¡É~32.0¡É" 24 "15.0¡É~32.0¡É" 25 "15.0¡É~32.0¡É" 26 "15.0¡É~32.0¡É" 27 "15.0¡É~32.0¡É" 28 "15.0¡É~32.0¡É" 29 "15.0¡É~32.0¡É" 30 "15.0¡É~32.0¡É" 31 "15.0¡É~32.0¡É" 32 "15.0¡É~32.0¡É" 33 "15.0¡É~32.0¡É" 34 "15.0¡É~32.0¡É" 35 "15.0¡É~32.0¡É" 36 "15.0¡É~32.0¡É" 37 "0x25~0xFD:RESERVED" 253 "0x25~0xFD:RESERVED" 254 "'HI' Display" 255 "Error Indicator" ;
VAL_ 34 L_ATCU_DrTempFDis 0 "Blank Display(Default)" 1 "'LO' Display" 2 "58¢µ~92¢µ" 3 "58¢µ~92¢µ" 4 "58¢µ~92¢µ" 5 "58¢µ~92¢µ" 6 "58¢µ~92¢µ" 7 "58¢µ~92¢µ" 8 "58¢µ~92¢µ" 9 "58¢µ~92¢µ" 10 "58¢µ~92¢µ" 11 "58¢µ~92¢µ" 12 "58¢µ~92¢µ" 13 "58¢µ~92¢µ" 14 "58¢µ~92¢µ" 15 "58¢µ~92¢µ" 16 "58¢µ~92¢µ" 17 "58¢µ~92¢µ" 18 "58¢µ~92¢µ" 19 "58¢µ~92¢µ" 20 "58¢µ~92¢µ" 21 "58¢µ~92¢µ" 22 "58¢µ~92¢µ" 23 "58¢µ~92¢µ" 24 "58¢µ~92¢µ" 25 "58¢µ~92¢µ" 26 "58¢µ~92¢µ" 27 "58¢µ~92¢µ" 28 "58¢µ~92¢µ" 29 "58¢µ~92¢µ" 30 "58¢µ~92¢µ" 31 "58¢µ~92¢µ" 32 "58¢µ~92¢µ" 33 "58¢µ~92¢µ" 34 "58¢µ~92¢µ" 35 "58¢µ~92¢µ" 36 "58¢µ~92¢µ" 37 "0x25~0xFD:RESERVED" 253 "0x25~0xFD:RESERVED" 254 "'HI' Display" 255 "Error Indicator" ;
VAL_ 34 L_ATCU_PassTempFDis 0 "Blank Display(Default)" 1 "'LO' Display" 2 "58¢µ~92¢µ" 3 "58¢µ~92¢µ" 4 "58¢µ~92¢µ" 5 "58¢µ~92¢µ" 6 "58¢µ~92¢µ" 7 "58¢µ~92¢µ" 8 "58¢µ~92¢µ" 9 "58¢µ~92¢µ" 10 "58¢µ~92¢µ" 11 "58¢µ~92¢µ" 12 "58¢µ~92¢µ" 13 "58¢µ~92¢µ" 14 "58¢µ~92¢µ" 15 "58¢µ~92¢µ" 16 "58¢µ~92¢µ" 17 "58¢µ~92¢µ" 18 "58¢µ~92¢µ" 19 "58¢µ~92¢µ" 20 "58¢µ~92¢µ" 21 "58¢µ~92¢µ" 22 "58¢µ~92¢µ" 23 "58¢µ~92¢µ" 24 "58¢µ~92¢µ" 25 "58¢µ~92¢µ" 26 "58¢µ~92¢µ" 27 "58¢µ~92¢µ" 28 "58¢µ~92¢µ" 29 "58¢µ~92¢µ" 30 "58¢µ~92¢µ" 31 "58¢µ~92¢µ" 32 "58¢µ~92¢µ" 33 "58¢µ~92¢µ" 34 "58¢µ~92¢µ" 35 "58¢µ~92¢µ" 36 "58¢µ~92¢µ" 37 "0x25~0xFD:RESERVED" 253 "0x25~0xFD:RESERVED" 254 "'HI' Display" 255 "Error Indicator" ;
VAL_ 34 L_ATCU_FrDrModDis 0 "Off(Blank Display, Vent mode not Display ex) Auto(Default)" 1 "VENT" 2 "B_L" 3 "FLOOR" 4 "MIX (7 MODE DEF FLOOR)" 5 "DEF (MAX DEF)" 6 "AUTO DEFOG" 7 "7 MODE DEF VENT" 8 "MODE AUTO" 9 "7 MODE DEF VENT FLOOR" 10 "7 MODE DEF" 11 "DEF VENT (Arrow)" 12 "DEF FLOOR (Arrow)" 13 "DEF VENT FLOOR (Arrow)" 14 "DEF (Arrow)" 15 "Error Indicator" ;
VAL_ 34 L_ATCU_FrPassModDis 0 "Off(Blank Display, Vent mode not Display ex) Auto(Default)" 1 "VENT" 2 "B_L" 3 "FLOOR" 4 "MIX (7 MODE DEF FLOOR)" 5 "DEF (MAX DEF)" 6 "AUTO DEFOG" 7 "7 MODE DEF VENT" 8 "MODE AUTO" 9 "7 MODE DEF VENT FLOOR" 10 "7 MODE DEF" 11 "DEF VENT (Arrow)" 12 "DEF FLOOR (Arrow)" 13 "DEF VENT FLOOR (Arrow)" 14 "DEF (Arrow)" 15 "Error Indicator" ;
VAL_ 34 L_ATCU_FrDrBlwDis 0 "OFF(System Off)" 1 "Blank Display(No Blower level display, ex)Auto" 2 "1 Level" 3 "2 Level" 4 "3 Level" 5 "4 Level" 6 "5 Level" 7 "6 Level" 8 "7 Level" 9 "8 Level" 10 "Not used" 11 "Not used" 12 "Not used" 13 "Not used" 14 "Not used" 15 "Error Indicator" ;
VAL_ 34 L_ATCU_FrPassBlwDis 0 "OFF(System Off)" 1 "Blank Display(No Blower level display, ex)Auto" 2 "1 Level" 3 "2 Level" 4 "3 Level" 5 "4 Level" 6 "5 Level" 7 "6 Level" 8 "7 Level" 9 "8 Level" 10 "Not used" 11 "Not used" 12 "Not used" 13 "Not used" 14 "Not used" 15 "Error Indicator" ;
VAL_ 34 L_ATCU_DrAutoDis 0 "DrAUTO Off" 1 "DrAUTO On" 2 "Not used" 3 "Error Indicator" ;
VAL_ 34 L_ATCU_PassAutoDis 0 "PsAUTO Off" 1 "PsAUTO On" 2 "Not used" 3 "Error Indicator" ;
VAL_ 34 L_ATCU_DrMultiAutoBlwDis 0 "MultiAutoBlr Display Off" 1 "Multi Auto Blower Low" 2 "Multi Auto Blower Mid" 3 "Multi Auto Blower High" ;
VAL_ 34 L_ATCU_PassMultiAutoBlwDis 0 "MultiAutoBlr Display Off" 1 "Multi Auto Blower Low" 2 "Multi Auto Blower Mid" 3 "Multi Auto Blower High" ;
VAL_ 34 L_ATCU_AcDis 0 "A/C Off" 1 "A/C ON" 2 "Not used" 3 "Error Indicator" ;
VAL_ 34 L_ATCU_IntakeDis 0 "Default(Fresh off & Rec off)" 1 "REC (Fresh off)" 2 "FRE (REC off)" 3 "Error Indicator" ;
VAL_ 34 L_ATCU_SyncDis 0 "SYNC Off" 1 "SYNC On" 2 "Not used" 3 "Error Indicator" ;
VAL_ 34 L_ATCU_FrDefDis 0 "Front Def Off" 1 "Front Def On" 2 "Not used" 3 "Error Indicator" ;
VAL_ 34 L_ATCU_PassTempCDis 0 "Blank Display (Default)" 1 "'LO' Display" 2 "15.0¡É~32.0¡É" 3 "15.0¡É~32.0¡É" 4 "15.0¡É~32.0¡É" 5 "15.0¡É~32.0¡É" 6 "15.0¡É~32.0¡É" 7 "15.0¡É~32.0¡É" 8 "15.0¡É~32.0¡É" 9 "15.0¡É~32.0¡É" 10 "15.0¡É~32.0¡É" 11 "15.0¡É~32.0¡É" 12 "15.0¡É~32.0¡É" 13 "15.0¡É~32.0¡É" 14 "15.0¡É~32.0¡É" 15 "15.0¡É~32.0¡É" 16 "15.0¡É~32.0¡É" 17 "15.0¡É~32.0¡É" 18 "15.0¡É~32.0¡É" 19 "15.0¡É~32.0¡É" 20 "15.0¡É~32.0¡É" 21 "15.0¡É~32.0¡É" 22 "15.0¡É~32.0¡É" 23 "15.0¡É~32.0¡É" 24 "15.0¡É~32.0¡É" 25 "15.0¡É~32.0¡É" 26 "15.0¡É~32.0¡É" 27 "15.0¡É~32.0¡É" 28 "15.0¡É~32.0¡É" 29 "15.0¡É~32.0¡É" 30 "15.0¡É~32.0¡É" 31 "15.0¡É~32.0¡É" 32 "15.0¡É~32.0¡É" 33 "15.0¡É~32.0¡É" 34 "15.0¡É~32.0¡É" 35 "15.0¡É~32.0¡É" 36 "15.0¡É~32.0¡É" 37 "0x25~0xFD:RESERVED" 253 "0x25~0xFD:RESERVED" 254 "'HI' Display" 255 "Error Indicator" ;
VAL_ 35 L_ATCU_DrOnlyDis 0 "Initial (Dual Temp Display)" 1 "Driver Only Status (Only Display Driver Temp)" 2 "Not used" 3 "Error Indicator" ;
VAL_ 35 L_ATCU_SmrtVntDis 0 "Off" 1 "Smart Ventilation" 2 "Smart CO2" 3 "Error Indicator" ;
VAL_ 35 L_ATCU_FrWndShldHtInd 0 "Off" 1 "On" 2 "RESERVED" ;
VAL_ 35 L_ATCU_IncarMtrOnReq 0 "OFF" 1 "ON" ;
VAL_ 35 L_ATCU_LanguageInfo 0 "Off" 1 "Korea" 2 "English(US)" 3 "English(UK)" 4 "Simplified chinese" 5 "Traditional chinese" 6 "French(EU)" 7 "Spanish(EU)" 8 "Arabic" 9 "Czech" 10 "Danish" 11 "German" 12 "Italian" 13 "Dutch" 14 "Polish" 15 "Portuguese" 16 "Russain" 17 "Slovak" 18 "Swedish" 19 "Turkish" 20 "French(US)" 21 "Spanish(US)" 22 "English(India)" 23 "Norwegian" 24 "Finnish" 25 "Indonesian" 26 "Brazilian Portuguese" 27 "Malay" 28 "Hungarian" 29 "English (Australia)" 30 "Japanese" 31 "Hindi" 32 "Hebrew" 33 "Greek" 34 "Ukrainian" 35 "Slovenian" 36 "Bulgarian" 37 "Croatian" 38 "Romanian" 39 "Bengali" 40 "Marathi" 41 "Telugu" 42 "Tamil" 43 "Gujarati" 44 "Kannada" 45 "Odia" 46 "Malayalam" 47 "Punjabi" 48 "Thai" 49 "Tagalog" 50 "Vietnamese" 51 "0x33~0xFE:RESERVED" 254 "0x33~0xFE:RESERVED" 255 "Invalid" ;
VAL_ 35 L_ATCU_RrDefInd 0 "OFF" 1 "ON" ;
VAL_ 35 L_ATCU_AfterBlowDisplay 0 "Default" 1 "AfterBlower Waiting" 2 "AfterBlower Operating(Symbol Off)" 3 "AfterBlower Operating(Symbol On)" ;
VAL_ 35 L_ATCU_SchdldVentDisplay 0 "Default" 1 "SchdldVent Waiting" 2 "SchdldVent Operating(Symbol Off)" 3 "SchdldVent Operating(Symbol On)" ;
VAL_ 35 L_ATCU_FLStHeatSwHInd 0 "OFF" 1 "ON" ;
VAL_ 35 L_ATCU_FLStHeatSwMInd 0 "OFF" 1 "ON" ;
VAL_ 35 L_ATCU_ADSBlinkDis 0 "AutoDefogBlink Non Request" 1 "AutoDefogBlink Request" 2 "Not used" 3 "Error Indicator" ;
VAL_ 35 L_ATCU_FLStHeatSwLInd 0 "OFF" 1 "ON" ;
VAL_ 35 L_ATCU_FLStVntSwHInd 0 "OFF" 1 "ON" ;
VAL_ 35 L_ATCU_FLStVntSwMInd 0 "OFF" 1 "ON" ;
VAL_ 35 L_ATCU_FLStVntSwLInd 0 "OFF" 1 "ON" ;
VAL_ 35 L_ATCU_FRStHeatSwHInd 0 "OFF" 1 "ON" ;
VAL_ 35 L_ATCU_FRStHeatSwMInd 0 "OFF" 1 "ON" ;
VAL_ 35 L_ATCU_FRStHeatSwLInd 0 "OFF" 1 "ON" ;
VAL_ 35 L_ATCU_FRStVntSwHInd 0 "OFF" 1 "ON" ;
VAL_ 35 L_ATCU_FRStVntSwMInd 0 "OFF" 1 "ON" ;
VAL_ 35 L_ATCU_FRStVntSwLInd 0 "OFF" 1 "ON" ;
VAL_ 35 L_ATCU_StrWhlHeatInd 0 "OFF" 1 "Step1" 2 "Step2" 3 "RESERVED" ;
VAL_ 35 L_ATCU_RhstaLvlSta 0 "RESERVED" 1 "Step1" 2 "Step2" 3 "Step 3" 4 "Step 4" 5 "Step5" 6 "Step 6" 7 "Step 7" 8 "Step8" 9 "Step 9" 10 "Step 10" 11 "Step11" 12 "Step 12" 13 "Step 13" 14 "Step14" 15 "Step 15" 16 "Step 16" 17 "Step17" 18 "Step 18" 19 "Step 19" 20 "Step 20 (Reset Value)" 21 "Step 21(Detent)" ;
VAL_ 35 L_ATCU_IntTailOnOff 0 "OFF" 1 "ON" ;
VAL_ 35 L_ATCU_AutoLightSta 0 "Off (not Night)" 1 "Night" ;
VAL_ 35 L_ATCU_FrBckLightSta 0 "OFF" 1 "ON" ;
VAL_ 35 L_ATCU_DisplayTheme 0 "Default" 1 "White Theme" 2 "Black Theme" 3 "Invalid" ;
VAL_ 35 L_ATCU_GUIBlankDis 0 "Default" 1 "GUI Blank Display" ;
VAL_ 35 L_ATCU_HptIntnstySet 0 "Default" 1 "Haptic OFF" 2 "Haptic Intensity Level 1" 3 "Haptic Intensity Level 2" 4 "Haptic Intensity Level 3" 5 "Haptic Intensity Level 4" 6 "Haptic Intensity Level 5" 7 "RESERVED" 8 "RESERVED" 9 "RESERVED" 10 "RESERVED" 11 "RESERVED" 12 "RESERVED" 13 "RESERVED" 14 "RESERVED" 15 "Invalid" ;
VAL_ 35 L_ATCU_TlltLmpDis 0 "ON Lamp off OFF Lamp off" 1 "ON Lamp off OFF Lamp on" 2 "ON Lamp on Off Lamp off" 3 "ON Lamp on OFF Lamp on" 4 "RESERVED" 5 "RESERVED" 6 "RESERVED" 7 "Error Indicator" ;
VAL_ 35 L_ATCU_AvTailOnOff 0 "OFF" 1 "ON" ;
VAL_ 35 L_ATCU_SchdldClimateDisplay 0 "Reservation Not Set" 1 "Reservation Set" 2 "Not used" 3 "Error Indicator" ;
VAL_ 35 L_ATCU_AirClnDis 0 "AirClean Off" 1 "AirClean On" 2 "Not used" 3 "Error Indicator" ;
VAL_ 35 L_ATCU_CO2WrngDis 0 "Co2 Warning Off" 1 "Co2 Warning On" 2 "Not used" 3 "Error Indicator" ;
VAL_ 36 L_ATCU_ArClnIntroEvt 0 "OFF" 1 "ON" ;
VAL_ 36 L_ATCU_ArClnSmblClr 0 "Default (Initial Value)" 1 "Mono Color" 2 "Blue Color" 3 "Green Color" 4 "Orange Color" 5 "Red Color" 6 "Yellow Color" 7 "RESERVED" 8 "RESERVED" 9 "RESERVED" 10 "RESERVED" 11 "RESERVED" 12 "RESERVED" 13 "RESERVED" 14 "Gray Color (Deactivate)" 15 "Invalid" ;
VAL_ 36 L_ATCU_DustLevelDis 0 "Sensor Fail" 1 "Good" 2 "Normal" 3 "Bad" 4 "Very Bad" 5 "RESERVED" 6 "Loading(Init or StandBy)" 7 "Error Indicator" ;
VAL_ 36 L_ATCU_DustBarDisOff 0 "False(Symbol ON)" 1 "True(Symbol OFF)" ;
VAL_ 36 L_ATCU_DustSnrStepDis 0 "default" 1 "0step" 2 "1step" 3 "2step" 4 "3step" 5 "4step" 6 "5step" 7 "6step" 8 "7step" 9 "8step" 10 "9step" 11 "10step" 12 "11step" 13 "12step" 14 "13step" 15 "14step" 16 "15step" 17 "16step" ;
VAL_ 36 L_ATCU_FragStrhDis 0 "OFF" 1 "1st(Low)" 2 "1st&2nd(Mid)" 3 "1st&2nd&3rd(High)" ;
VAL_ 36 L_ATCU_FragKindDis 0 "Default" 1 "First" 2 "Second" 3 "RESERVED" 4 "RESERVED" 5 "RESERVED" 6 "None" 7 "Error Indicator" ;
VAL_ 36 L_ATCU_Frag1Inform 0 "Default" 1 "THE DRIVER'S AWAKENING" 2 "MY FAVORITE PLACE" 3 "THE GREAT OUTDOORS" 4 "RESERVED" 5 "RESERVED" 6 "RESERVED" 7 "RESERVED" 8 "RESERVED" 9 "RESERVED" 10 "RESERVED" 11 "RESERVED" 12 "New Fragrance Mounted" 13 "No Cartridge Mounted" 14 "Unknown Cartridge Monuted" 15 "Error Indicator" ;
VAL_ 36 L_ATCU_Frag2Inform 0 "Default" 1 "THE DRIVER'S AWAKENING" 2 "MY FAVORITE PLACE" 3 "THE GREAT OUTDOORS" 4 "RESERVED" 5 "RESERVED" 6 "RESERVED" 7 "RESERVED" 8 "RESERVED" 9 "RESERVED" 10 "RESERVED" 11 "RESERVED" 12 "New Fragrance Mounted" 13 "No Cartridge Mounted" 14 "Unknown Cartridge Monuted" 15 "Error Indicator" ;
VAL_ 36 L_ATCU_Frag1RemainDisp 0 "Default" 1 "Remains 100% (70~100%)" 2 "Remains 70% (30~70%)" 3 "Remains 30% (0~30%)" 4 "Remains 0%" 5 "RESERVED" 6 "Unknown" 7 "Error Indicator" ;
VAL_ 36 L_ATCU_Frag2RemainDisp 0 "Default" 1 "Remains 100% (70~100%)" 2 "Remains 70% (30~70%)" 3 "Remains 30% (0~30%)" 4 "Remains 0%" 5 "RESERVED" 6 "Unknown" 7 "Error Indicator" ;
VAL_ 36 L_ATCU_ArClnSmblTyp 0 "Default" 1 "BLANK DISPLAY" 2 "Tree Only" 3 "Tree & Fixed Arrow" 4 "Tree & Rotating Arrow" ;
VAL_ 36 L_ATCU_FrtBlwMaxLvlVaild 0 "Invalid (Multi AUTO Not Applied)" 1 "Reversed" 2 "1 Level" 3 "2 Level" 4 "3 Level" 5 "4 Level" 6 "5 Level" 7 "6 Level" 8 "7 Level" 9 "8 Level" 10 "Not used" 11 "Not used" 12 "Not used" 13 "Not used" 14 "Not used" 15 "Error Indicator" ;
VAL_ 36 L_ATCU_OpSta 0 "DATC Off (Power Down)" 1 "DATC Normal" 2 "DATC System Off (Blower Off)" 3 "DATC Self Diagnosis" 4 "Version Display" 5 "Not used" 6 "Not used" 7 "Error Indicator" ;
VAL_ 36 L_ATCU_TempDispUnit 0 "Centigrade(¡É)" 1 "Fahrenheit(¢µ)" 2 "Not used" 3 "Error Indicator" ;
VAL_ 36 L_ATCU_DrvAUTOStep 0 "Default" 1 "OFF" 2 "1st & 2nd & 3rd On (3 Step Type)" 3 "1st & 2nd On (3 Step Type)" 4 "1st On (3 Step Type)" 5 "1st & 2nd On (2 Step Type)" 6 "1st On (2 Step Type)" 7 "RESERVED" 8 "RESERVED" 9 "RESERVED" 10 "RESERVED" 11 "RESERVED" 12 "RESERVED" 13 "RESERVED" 14 "RESERVED" 15 "Error Indicator" ;
VAL_ 36 L_ATCU_DiagCodeDis 0 "Blank Display" 1023 "Error Indicator" ;
VAL_ 37 L_ATCU_RrOpSta 0 "DATC Off (Power Down)" 1 "DATC Normal" 2 "DATC System Off (Blower Off)" 3 "DATC Self Diagnosis" 4 "Not used" 5 "Not used" 6 "Not used" 7 "Error Indicator" ;
VAL_ 37 L_ATCU_RrDrvTempFDis 0 "Blank Display (Default)" 1 "'LO' Display" 2 "58¢µ~92¢µ" 3 "58¢µ~92¢µ" 4 "58¢µ~92¢µ" 5 "58¢µ~92¢µ" 6 "58¢µ~92¢µ" 7 "58¢µ~92¢µ" 8 "58¢µ~92¢µ" 9 "58¢µ~92¢µ" 10 "58¢µ~92¢µ" 11 "58¢µ~92¢µ" 12 "58¢µ~92¢µ" 13 "58¢µ~92¢µ" 14 "58¢µ~92¢µ" 15 "58¢µ~92¢µ" 16 "58¢µ~92¢µ" 17 "58¢µ~92¢µ" 18 "58¢µ~92¢µ" 19 "58¢µ~92¢µ" 20 "58¢µ~92¢µ" 21 "58¢µ~92¢µ" 22 "58¢µ~92¢µ" 23 "58¢µ~92¢µ" 24 "58¢µ~92¢µ" 25 "58¢µ~92¢µ" 26 "58¢µ~92¢µ" 27 "58¢µ~92¢µ" 28 "58¢µ~92¢µ" 29 "58¢µ~92¢µ" 30 "58¢µ~92¢µ" 31 "58¢µ~92¢µ" 32 "58¢µ~92¢µ" 33 "58¢µ~92¢µ" 34 "58¢µ~92¢µ" 35 "58¢µ~92¢µ" 36 "58¢µ~92¢µ" 37 "0x25~0xFD:RESERVED" 253 "0x25~0xFD:RESERVED" 254 "'HI' Display" 255 "Error Indicator" ;
VAL_ 37 L_ATCU_RrDrvModDis 0 "Off(Blank Display, Vent mode not Display ex) Auto" 1 "VENT" 2 "B_L" 3 "FLOOR" 4 "MIX" 5 "DEF(Including Max DEF)" 6 "AUTO DEFOG" 7 "Def (7 mode only)" 8 "DefVent(7 mode only)" 9 "DefFL(7 mode only)" 10 "VentFL(7 mode only)" 11 "DefVentFL(7 mode only)" 12 "Not used" 13 "Not used" 14 "Not used" 15 "Error Indicator" ;
VAL_ 37 L_ATCU_RrDrvBlwDis 0 "OFF(System Off)" 1 "Blank Display(Blower Level no display, ex)Auto mode)" 2 "1 Level" 3 "2 Level" 4 "3 Level" 5 "4 Level" 6 "5 Level" 7 "6 Level" 8 "7 Level" 9 "8 Level" 10 "Not used" 11 "Not used" 12 "Not used" 13 "Not used" 14 "Not used" 15 "Error Indicator" ;
VAL_ 37 L_ATCU_RrDrvAutoDis 0 "RrAUTO Off" 1 "RrAUTO On" 2 "Not used" 3 "Error Indicator" ;
VAL_ 37 L_ATCU_RrDrvMultiAutoBlwDis 0 "MultiAutoBlr Display Off" 1 "Multi Auto Blower Low" 2 "Multi Auto Blower Mid" 3 "Multi Auto Blower High" ;
VAL_ 37 L_ATCU_RrDrvTempCDis 0 "Blank Display (Default)" 1 "'LO' Display" 2 "15.0¡É~32.0¡É" 3 "15.0¡É~32.0¡É" 4 "15.0¡É~32.0¡É" 5 "15.0¡É~32.0¡É" 6 "15.0¡É~32.0¡É" 7 "15.0¡É~32.0¡É" 8 "15.0¡É~32.0¡É" 9 "15.0¡É~32.0¡É" 10 "15.0¡É~32.0¡É" 11 "15.0¡É~32.0¡É" 12 "15.0¡É~32.0¡É" 13 "15.0¡É~32.0¡É" 14 "15.0¡É~32.0¡É" 15 "15.0¡É~32.0¡É" 16 "15.0¡É~32.0¡É" 17 "15.0¡É~32.0¡É" 18 "15.0¡É~32.0¡É" 19 "15.0¡É~32.0¡É" 20 "15.0¡É~32.0¡É" 21 "15.0¡É~32.0¡É" 22 "15.0¡É~32.0¡É" 23 "15.0¡É~32.0¡É" 24 "15.0¡É~32.0¡É" 25 "15.0¡É~32.0¡É" 26 "15.0¡É~32.0¡É" 27 "15.0¡É~32.0¡É" 28 "15.0¡É~32.0¡É" 29 "15.0¡É~32.0¡É" 30 "15.0¡É~32.0¡É" 31 "15.0¡É~32.0¡É" 32 "15.0¡É~32.0¡É" 33 "15.0¡É~32.0¡É" 34 "15.0¡É~32.0¡É" 35 "15.0¡É~32.0¡É" 36 "15.0¡É~32.0¡É" 37 "0x25~0xFD:RESERVED" 253 "0x25~0xFD:RESERVED" 254 "'HI' Display" 255 "Error Indicator" ;
VAL_ 37 L_ATCU_RrSyncDis 0 "RrSYNC Off" 1 "RrSYNC On" 2 "Not used" 3 "Error Indicator" ;
VAL_ 37 L_ATCU_RrLcdBckLightSta 0 "OFF" 1 "ON" ;
VAL_ 37 L_ATCU_RrGUIBlankDis 0 "OFF" 1 "ON" ;
VAL_ 37 L_ATCU_RLStHeatSwHInd 0 "OFF" 1 "ON" ;
VAL_ 37 L_ATCU_RLStHeatSwMInd 0 "OFF" 1 "ON" ;
VAL_ 37 L_ATCU_RLStHeatSwLInd 0 "OFF" 1 "ON" ;
VAL_ 37 L_ATCU_RLStVntSwHInd 0 "OFF" 1 "ON" ;
VAL_ 37 L_ATCU_RLStVntSwMInd 0 "OFF" 1 "ON" ;
VAL_ 37 L_ATCU_RLStVntSwLInd 0 "OFF" 1 "ON" ;
VAL_ 37 L_ATCU_RRStHeatSwHInd 0 "OFF" 1 "ON" ;
VAL_ 37 L_ATCU_RRStHeatSwMInd 0 "OFF" 1 "ON" ;
VAL_ 37 L_ATCU_RRStHeatSwLInd 0 "OFF" 1 "ON" ;
VAL_ 37 L_ATCU_RRStVntSwHInd 0 "OFF" 1 "ON" ;
VAL_ 37 L_ATCU_RRStVntSwMInd 0 "OFF" 1 "ON" ;
VAL_ 37 L_ATCU_RRStVntSwLInd 0 "OFF" 1 "ON" ;
VAL_ 37 L_ATCU_RrMTCOpSta 0 "DATC Off (Power Down)" 1 "DATC Normal" 2 "DATC System Off (Blower Off)" 3 "Error Indicator" ;
VAL_ 37 L_ATCU_RrMTCTempLvl 0 "Off" 1 "Level 1" 2 "Level 2" 3 "Level 3" 4 "Level 4" 5 "Level 5" 6 "Level 6" 7 "Level 7" 8 "Level 8" ;
VAL_ 37 L_ATCU_RrPsModDis 0 "Off(Blank Display, Vent mode not Display ex) Auto" 1 "VENT" 2 "B_L" 3 "FLOOR" 4 "MIX" 5 "DEF(Including Max DEF)" 6 "AUTO DEFOG" 7 "Def (7 mode only)" 8 "DefVent(7 mode only)" 9 "DefFL(7 mode only)" 10 "VentFL(7 mode only)" 11 "DefVentFL(7 mode only)" 12 "Not used" 13 "Not used" 14 "Not used" 15 "Error Indicator" ;
VAL_ 37 L_ATCU_RrLockDis 0 "RearLock Off" 1 "RearLock On" 2 "Not Used" 3 "Error Indicator" ;
VAL_ 37 L_ATCU_RrDrvAutoStep 0 "Default" 1 "OFF" 2 "1st & 2nd & 3rd On (3 Step Type)" 3 "1st & 2nd On (3 Step Type)" 4 "1st On (3 Step Type)" 5 "1st & 2nd On (2 Step Type)" 6 "1st On (2 Step Type)" 7 "RESERVED" 8 "RESERVED" 9 "RESERVED" 10 "RESERVED" 11 "RESERVED" 12 "RESERVED" 13 "RESERVED" 14 "RESERVED" 15 "Error Indicator" ;
VAL_ 38 L_ATCU_3rdRrTempCDis 0 "Blank Display (Default)" 1 "'LO' Display" 2 "15.0¡É~32.0¡É" 3 "15.0¡É~32.0¡É" 4 "15.0¡É~32.0¡É" 5 "15.0¡É~32.0¡É" 6 "15.0¡É~32.0¡É" 7 "15.0¡É~32.0¡É" 8 "15.0¡É~32.0¡É" 9 "15.0¡É~32.0¡É" 10 "15.0¡É~32.0¡É" 11 "15.0¡É~32.0¡É" 12 "15.0¡É~32.0¡É" 13 "15.0¡É~32.0¡É" 14 "15.0¡É~32.0¡É" 15 "15.0¡É~32.0¡É" 16 "15.0¡É~32.0¡É" 17 "15.0¡É~32.0¡É" 18 "15.0¡É~32.0¡É" 19 "15.0¡É~32.0¡É" 20 "15.0¡É~32.0¡É" 21 "15.0¡É~32.0¡É" 22 "15.0¡É~32.0¡É" 23 "15.0¡É~32.0¡É" 24 "15.0¡É~32.0¡É" 25 "15.0¡É~32.0¡É" 26 "15.0¡É~32.0¡É" 27 "15.0¡É~32.0¡É" 28 "15.0¡É~32.0¡É" 29 "15.0¡É~32.0¡É" 30 "15.0¡É~32.0¡É" 31 "15.0¡É~32.0¡É" 32 "15.0¡É~32.0¡É" 33 "15.0¡É~32.0¡É" 34 "15.0¡É~32.0¡É" 35 "15.0¡É~32.0¡É" 36 "15.0¡É~32.0¡É" 37 "0x25~0xFD:RESERVED" 253 "0x25~0xFD:RESERVED" 254 "'HI' Display" 255 "Error Indicator" ;
VAL_ 38 L_ATCU_3rdRrModDis 0 "Off(Blank Display, Vent mode not Display ex) Auto" 1 "VENT" 2 "B_L" 3 "FLOOR" 4 "MIX" 5 "DEF(Including Max DEF)" 6 "AUTO DEFOG" 7 "Def (7 mode only)" 8 "DefVent(7 mode only)" 9 "DefFL(7 mode only)" 10 "VentFL(7 mode only)" 11 "DefVentFL(7 mode only)" 12 "Not used" 13 "Not used" 14 "Not used" 15 "Error Indicator" ;
VAL_ 38 L_ATCU_3rdRrBlwDis 0 "OFF(System Off)" 1 "Blank Display(Blower Level no display, ex)Auto mode)" 2 "1 Level" 3 "2 Level" 4 "3 Level" 5 "4 Level" 6 "5 Level" 7 "6 Level" 8 "7 Level" 9 "8 Level" 10 "Not used" 11 "Not used" 12 "Not used" 13 "Not used" 14 "Not used" 15 "Error Indicator" ;
VAL_ 38 L_ATCU_3rdRrAutoDis 0 "3rdRrAUTO Off" 1 "3rdRrAUTO On" 2 "Not used" 3 "Error Indicator" ;
VAL_ 38 L_ATCU_3rdRrMultiAutoBlwDis 0 "MultiAutoBlr Display Off" 1 "Multi Auto Blower Low" 2 "Multi Auto Blower Mid" 3 "Multi Auto Blower High" 4 "RESERVED" 5 "RESERVED" 6 "RESERVED" 7 "Error Indicator" ;
VAL_ 38 L_ATCU_3rdRrSyncDis 0 "RearAc Off" 1 "RearAc On" 2 "Not Used" 3 "Error Indicator" ;
VAL_ 38 L_ATCU_3rdRrOnInd 0 "Off" 1 "On" 2 "RESERVED" ;
VAL_ 38 L_ATCU_3rdRrLockDis 0 "RearLock Off" 1 "RearLock On" 2 "Not Used" 3 "Error Indicator" ;
VAL_ 38 L_ATCU_3rdRrLcdBckLightSta 0 "OFF" 1 "ON" ;
VAL_ 38 L_ATCU_3rdRrGUIBlankDis 0 "OFF" 1 "ON" ;
VAL_ 38 L_ATCU_3rdRLStHeatSwHInd 0 "OFF" 1 "ON" ;
VAL_ 38 L_ATCU_3rdRLStHeatSwMInd 0 "OFF" 1 "ON" ;
VAL_ 38 L_ATCU_3rdRLStHeatSwLInd 0 "OFF" 1 "ON" ;
VAL_ 38 L_ATCU_3rdRLStVntSwHInd 0 "OFF" 1 "ON" ;
VAL_ 38 L_ATCU_3rdRLStVntSwMInd 0 "OFF" 1 "ON" ;
VAL_ 38 L_ATCU_3rdRLStVntSwLInd 0 "OFF" 1 "ON" ;
VAL_ 38 L_ATCU_3rdRRStHeatSwHInd 0 "OFF" 1 "ON" ;
VAL_ 38 L_ATCU_3rdRRStHeatSwMInd 0 "OFF" 1 "ON" ;
VAL_ 38 L_ATCU_3rdRRStHeatSwLInd 0 "OFF" 1 "ON" ;
VAL_ 38 L_ATCU_3rdRRStVntSwHInd 0 "OFF" 1 "ON" ;
VAL_ 38 L_ATCU_3rdRRStVntSwMInd 0 "OFF" 1 "ON" ;
VAL_ 38 L_ATCU_3rdRRStVntSwLInd 0 "OFF" 1 "ON" ;
VAL_ 38 L_ATCU_3rdRrMTCOpSta 0 "DATC Off (Power Down)" 1 "DATC Normal" 2 "DATC System Off (Blower Off)" 3 "Error Indicator" ;
VAL_ 38 L_ATCU_3rdRrMtcTempLvl 0 "Off" 1 "Level 1" 2 "Level 2" 3 "Level 3" 4 "Level 4" 5 "Level 5" 6 "Level 6" 7 "Level 7" 8 "Level 8" ;
VAL_ 38 L_ATCU_3rdAUTOStep 0 "Default" 1 "OFF" 2 "1st & 2nd & 3rd On (3 Step Type)" 3 "1st & 2nd On (3 Step Type)" 4 "1st On (3 Step Type)" 5 "1st & 2nd On (2 Step Type)" 6 "1st On (2 Step Type)" 7 "Error Indicator" ;
VAL_ 38 L_ATCU_RrPassMultiAutoBlwDis 0 "MultiAutoBlr Display Off" 1 "Multi Auto Blower Low" 2 "Multi Auto Blower Mid" 3 "Multi Auto Blower High" 4 "RESERVED" 5 "RESERVED" 6 "RESERVED" 7 "Error Indicator" ;
VAL_ 38 L_ATCU_DisPnlState 0 "Front Display State(Default)" 1 "Rear Display State" 2 "RESERVED" 3 "Error Indicator" ;
VAL_ 38 L_ATCU_3rdRrTempFDis 0 "Blank Display(Default)" 1 "'LO' Display" 2 "58¢µ~92¢µ" 3 "58¢µ~92¢µ" 4 "58¢µ~92¢µ" 5 "58¢µ~92¢µ" 6 "58¢µ~92¢µ" 7 "58¢µ~92¢µ" 8 "58¢µ~92¢µ" 9 "58¢µ~92¢µ" 10 "58¢µ~92¢µ" 11 "58¢µ~92¢µ" 12 "58¢µ~92¢µ" 13 "58¢µ~92¢µ" 14 "58¢µ~92¢µ" 15 "58¢µ~92¢µ" 16 "58¢µ~92¢µ" 17 "58¢µ~92¢µ" 18 "58¢µ~92¢µ" 19 "58¢µ~92¢µ" 20 "58¢µ~92¢µ" 21 "58¢µ~92¢µ" 22 "58¢µ~92¢µ" 23 "58¢µ~92¢µ" 24 "58¢µ~92¢µ" 25 "58¢µ~92¢µ" 26 "58¢µ~92¢µ" 27 "58¢µ~92¢µ" 28 "58¢µ~92¢µ" 29 "58¢µ~92¢µ" 30 "58¢µ~92¢µ" 31 "58¢µ~92¢µ" 32 "58¢µ~92¢µ" 33 "58¢µ~92¢µ" 34 "58¢µ~92¢µ" 35 "58¢µ~92¢µ" 36 "58¢µ~92¢µ" 37 "0x25~0xFD:RESERVED" 253 "0x25~0xFD:RESERVED" 254 "'HI' Display" 255 "Error Indicator" ;
VAL_ 39 L_ATCU_RrHVACTempActrTgt 0 "0x0x0~0x3FF:AD = Factor*Hex + Offset" 1023 "0x0x0~0x3FF:AD = Factor*Hex + Offset" ;
VAL_ 39 L_ATCU_RrHVACTempAsstActrTgt 0 "0x0x0~0x3FF:AD = Factor*Hex + Offset" 1023 "0x0x0~0x3FF:AD = Factor*Hex + Offset" ;
VAL_ 39 L_ATCU_RrDrHVACModeActrTgt 0 "0x0x0~0x3FF:AD = Factor*Hex + Offset" 1023 "0x0x0~0x3FF:AD = Factor*Hex + Offset" ;
VAL_ 39 L_ATCU_RrHVACBlowerTgtV 0 "0x0x0~0xFF:V = Factor*Hex + Offset" 255 "0x0x0~0xFF:V = Factor*Hex + Offset" ;
VAL_ 39 L_ATCU_RrHVACBLDCRpmVal 0 "0x0x0~0x1388:Factor * Hex + Offset" 5000 "0x0x0~0x1388:Factor * Hex + Offset" 5001 "0x1389~0x7FFF:RESERVED" 32767 "0x1389~0x7FFF:RESERVED" ;
VAL_ 39 L_ATCU_RrPsHVACModeActrTgt 0 "0x0x0~0x3FF:AD=Factor*Hex + Offset" 1023 "0x0x0~0x3FF:AD=Factor*Hex + Offset" ;
VAL_ 40 L_ATCU_PassAUTOStep 0 "Default" 1 "OFF" 2 "1st & 2nd & 3rd On (3 Step Type)" 3 "1st & 2nd On (3 Step Type)" 4 "1st On (3 Step Type)" 5 "1st & 2nd On (2 Step Type)" 6 "1st On (2 Step Type)" 7 "Error Indicator" ;
VAL_ 40 L_ATCU_RrPassTempFDis 0 "Blank Display(Default)" 1 "'LO' Display" 2 "58¢µ~32¢µ" 3 "58¢µ~32¢µ" 4 "58¢µ~32¢µ" 5 "58¢µ~32¢µ" 6 "58¢µ~32¢µ" 7 "58¢µ~32¢µ" 8 "58¢µ~32¢µ" 9 "58¢µ~32¢µ" 10 "58¢µ~32¢µ" 11 "58¢µ~32¢µ" 12 "58¢µ~32¢µ" 13 "58¢µ~32¢µ" 14 "58¢µ~32¢µ" 15 "58¢µ~32¢µ" 16 "58¢µ~32¢µ" 17 "58¢µ~32¢µ" 18 "58¢µ~32¢µ" 19 "58¢µ~32¢µ" 20 "58¢µ~32¢µ" 21 "58¢µ~32¢µ" 22 "58¢µ~32¢µ" 23 "58¢µ~32¢µ" 24 "58¢µ~32¢µ" 25 "58¢µ~32¢µ" 26 "58¢µ~32¢µ" 27 "58¢µ~32¢µ" 28 "58¢µ~32¢µ" 29 "58¢µ~32¢µ" 30 "58¢µ~32¢µ" 31 "58¢µ~32¢µ" 32 "58¢µ~32¢µ" 33 "58¢µ~32¢µ" 34 "58¢µ~32¢µ" 35 "58¢µ~32¢µ" 36 "58¢µ~32¢µ" 37 "0x25~0xFD:RESERVED" 253 "0x25~0xFD:RESERVED" 254 "'HI' Display" 255 "Error Indicator" ;
VAL_ 40 L_ATCU_RrPassBlwDis 0 "OFF(Default)" 1 "Blank Display(Blower level not display, ex)Auto mode)" 2 "1 Step" 3 "2 Step" 4 "3 Step" 5 "4 Step" 6 "5 Step" 7 "6 Step" 8 "7 Step" 9 "8 Step" 10 "BLOWER AUTO" 11 "RESERVED" 12 "RESERVED" 13 "RESERVED" 14 "RESERVED" 15 "Error Indicator" ;
VAL_ 40 L_ATCU_RrPassAUTODis 0 "PsAUTO Off" 1 "PsAUTO On" 2 "Not used" 3 "Error Indicator" ;
VAL_ 40 L_ATCU_RrPassAUTOStep 0 "Default" 1 "OFF" 2 "1st & 2nd & 3rd On (3 Step Type)" 3 "1st & 2nd On (3 Step Type)" 4 "1st On (3 Step Type)" 5 "1st & 2nd On (2 Step Type)" 6 "1st On (2 Step Type)" 7 "Error Indicator" ;
VAL_ 40 L_ATCU_CampModeSta 0 "Default" 1 "Off" 2 "On" 3 "Invalid" ;
VAL_ 40 L_ATCU_RrPassTempCDis 0 "Blank Display(Default)" 1 "'LO' Display" 2 "15.0¡É~32.0¡É" 3 "15.0¡É~32.0¡É" 4 "15.0¡É~32.0¡É" 5 "15.0¡É~32.0¡É" 6 "15.0¡É~32.0¡É" 7 "15.0¡É~32.0¡É" 8 "15.0¡É~32.0¡É" 9 "15.0¡É~32.0¡É" 10 "15.0¡É~32.0¡É" 11 "15.0¡É~32.0¡É" 12 "15.0¡É~32.0¡É" 13 "15.0¡É~32.0¡É" 14 "15.0¡É~32.0¡É" 15 "15.0¡É~32.0¡É" 16 "15.0¡É~32.0¡É" 17 "15.0¡É~32.0¡É" 18 "15.0¡É~32.0¡É" 19 "15.0¡É~32.0¡É" 20 "15.0¡É~32.0¡É" 21 "15.0¡É~32.0¡É" 22 "15.0¡É~32.0¡É" 23 "15.0¡É~32.0¡É" 24 "15.0¡É~32.0¡É" 25 "15.0¡É~32.0¡É" 26 "15.0¡É~32.0¡É" 27 "15.0¡É~32.0¡É" 28 "15.0¡É~32.0¡É" 29 "15.0¡É~32.0¡É" 30 "15.0¡É~32.0¡É" 31 "15.0¡É~32.0¡É" 32 "15.0¡É~32.0¡É" 33 "15.0¡É~32.0¡É" 34 "15.0¡É~32.0¡É" 35 "15.0¡É~32.0¡É" 36 "15.0¡É~32.0¡É" 37 "0x25~0xFD:RESERVED" 253 "0x25~0xFD:RESERVED" 254 "'HI' Display" 255 "Error Indicator" ;
VAL_ 40 L_ATCU_UtilModeUsmSta 0 "Disable" 1 "Rest Mode Off" 2 "Rest Mode On" 3 "Invalid" ;
VAL_ 40 L_ATCU_RrAcDis 0 "AC OFF" 1 "AC ON" 2 "Not used" 3 "Error Indicator" ;
VAL_ 40 L_ATCU_3rdAcDis 0 "AC Off" 1 "AC ON" 2 "Not used" 3 "Error Indicator" ;
VAL_ 41 L_ATCU_OutTempDispC 0 "Default" 1 "Not Used" 2 "0x02~0xCA:-40¡É~60¡É" 202 "0x02~0xCA:-40¡É~60¡É" 203 "RESERVED" 204 "RESERVED" 205 "RESERVED" 206 "RESERVED" 207 "RESERVED" 208 "RESERVED" 209 "RESERVED" 210 "RESERVED" 211 "RESERVED" 212 "RESERVED" 213 "RESERVED" 214 "RESERVED" 215 "RESERVED" 216 "RESERVED" 217 "RESERVED" 218 "RESERVED" 219 "RESERVED" 220 "RESERVED" 221 "RESERVED" 222 "RESERVED" 223 "RESERVED" 224 "RESERVED" 225 "RESERVED" 226 "RESERVED" 227 "RESERVED" 228 "RESERVED" 229 "RESERVED" 230 "RESERVED" 231 "RESERVED" 232 "RESERVED" 233 "RESERVED" 234 "RESERVED" 235 "RESERVED" 236 "RESERVED" 237 "RESERVED" 238 "RESERVED" 239 "RESERVED" 240 "RESERVED" 241 "RESERVED" 242 "RESERVED" 243 "RESERVED" 244 "RESERVED" 245 "RESERVED" 246 "RESERVED" 247 "RESERVED" 248 "RESERVED" 249 "RESERVED" 250 "RESERVED" 251 "RESERVED" 252 "RESERVED" 253 "RESERVED" 254 "Sensor Fail (--Display)" 255 "Invalid" ;
VAL_ 41 L_ATCU_DtntOutSta 0 "Detent Off" 1 "Detent On" ;
VAL_ 41 L_ATCU_AutoBrightSta 0 "RESERVED" 1 "0x01~0xC8:Bright State (1~200 Step)" 200 "0x01~0xC8:Bright State (1~200 Step)" 201 "RESERVED" 202 "RESERVED" 203 "RESERVED" 204 "RESERVED" 205 "RESERVED" 206 "RESERVED" 207 "RESERVED" 208 "RESERVED" 209 "RESERVED" 210 "RESERVED" 211 "RESERVED" 212 "RESERVED" 213 "RESERVED" 214 "RESERVED" 215 "RESERVED" 216 "RESERVED" 217 "RESERVED" 218 "RESERVED" 219 "RESERVED" 220 "RESERVED" 221 "RESERVED" 222 "RESERVED" 223 "RESERVED" 224 "RESERVED" 225 "RESERVED" 226 "RESERVED" 227 "RESERVED" 228 "RESERVED" 229 "RESERVED" 230 "RESERVED" 231 "RESERVED" 232 "RESERVED" 233 "RESERVED" 234 "RESERVED" 235 "RESERVED" 236 "RESERVED" 237 "RESERVED" 238 "RESERVED" 239 "RESERVED" 240 "RESERVED" 241 "RESERVED" 242 "RESERVED" 243 "RESERVED" 244 "RESERVED" 245 "RESERVED" 246 "RESERVED" 247 "RESERVED" 248 "RESERVED" 249 "RESERVED" 250 "RESERVED" 251 "RESERVED" 252 "RESERVED" 253 "RESERVED" 254 "RESERVED" 255 "RESERVED" ;
VAL_ 41 L_ATCU_DustSnrVal 1021 "Standby" 1022 "Init" 1023 "RESERVED" ;
VAL_ 41 L_ATCU_NotMinModeBrightSta 0 "RESERVED (Not Used)" 1 "0x01~0xC8:Bright State(1~200 Step)" 200 "0x01~0xC8:Bright State(1~200 Step)" ;
VAL_ 41 L_ATCU_IAUPrfleVal 0 "Default" 1 "Guest" 2 "Profile 1" 3 "Profile 2" 4 "Profile 3" 5 "Profile 4" 6 "Profile 5" 7 "Proflie 6" 8 "Profile 7" 9 "Profile 8" 10 "Profile 9" 11 "RESERVED" 12 "RESERVED" 13 "RESERVED" 14 "RESERVED" 15 "Invalid" ;
VAL_ 41 L_ATCU_AVNPrfleVal 0 "Default" 1 "Guest" 2 "Profile 1" 3 "Profile 2" 4 "Profile 3" 5 "Profile 4" 6 "Profile 5" 7 "Profile 6" 8 "Profile 7" 9 "Profile 8" 10 "Profile 9" 11 "RESERVED" 12 "RESERVED" 13 "RESERVED" 14 "RESERVED" 15 "Invalid" ;
VAL_ 41 L_ATCU_SchdldClimateSta 0 "Default" 1 "Deactivated" 2 "Activated" 3 "Invalid" ;
VAL_ 41 L_ATCU_OutTempDispF 0 "Default" 1 "Not Used" 2 "0x02~0xCA:-40¢µ~160¢µ" 202 "0x02~0xCA:-40¢µ~160¢µ" 203 "RESERVED" 204 "RESERVED" 205 "RESERVED" 206 "RESERVED" 207 "RESERVED" 208 "RESERVED" 209 "RESERVED" 210 "RESERVED" 211 "RESERVED" 212 "RESERVED" 213 "RESERVED" 214 "RESERVED" 215 "RESERVED" 216 "RESERVED" 217 "RESERVED" 218 "RESERVED" 219 "RESERVED" 220 "RESERVED" 221 "RESERVED" 222 "RESERVED" 223 "RESERVED" 224 "RESERVED" 225 "RESERVED" 226 "RESERVED" 227 "RESERVED" 228 "RESERVED" 229 "RESERVED" 230 "RESERVED" 231 "RESERVED" 232 "RESERVED" 233 "RESERVED" 234 "RESERVED" 235 "RESERVED" 236 "RESERVED" 237 "RESERVED" 238 "RESERVED" 239 "RESERVED" 240 "RESERVED" 241 "RESERVED" 242 "RESERVED" 243 "RESERVED" 244 "RESERVED" 245 "RESERVED" 246 "RESERVED" 247 "RESERVED" 248 "RESERVED" 249 "RESERVED" 250 "RESERVED" 251 "RESERVED" 252 "RESERVED" 253 "RESERVED" 254 "Sensor Fail (--Display)" 255 "Invalid" ;
VAL_ 48 L_ATCU_SW_Ver1 0 "0x0x00~0x7E:ASCII value" 126 "0x0x00~0x7E:ASCII value" 127 "Invalid" ;
VAL_ 48 L_ATCU_SW_Ver3 0 "0x0x00~0x7E:ASCII value" 126 "0x0x00~0x7E:ASCII value" 127 "Invalid" ;
VAL_ 48 L_ATCU_SW_Ver4 0 "0x0x00~0x7E:ASCII value" 126 "0x0x00~0x7E:ASCII value" 127 "Invalid" ;
VAL_ 48 L_ATCU_SW_Ver5 0 "0x0x00~0x7E:ASCII value" 126 "0x0x00~0x7E:ASCII value" 127 "Invalid" ;
VAL_ 48 L_ATCU_SW_Ver2 0 "0x0x00~0x7E:ASCII value" 126 "0x0x00~0x7E:ASCII value" 127 "Invalid" ;
VAL_ 49 L_ATCU_ResetPreWrngForOthers 0 "No Warning" 1 "Warning" 2 "RESERVED" 3 "Invalid" ;
VAL_ 49 L_ATCU_ResetReqForOthers 0 "No Request" 1 "Reset Request" 2 "RESERVED" 3 "Invalid" ;
VAL_ 273 L_ATCU_FHPTCOpPrmssnSta 0 "Not Permiited" 1 "Permitted" ;
VAL_ 273 L_ATCU_FHPTCPassTrgtDty 0 "0x0x0~0xC8:Duty" 200 "0x0x0~0xC8:Duty" 201 "RESERVED" 202 "RESERVED" 203 "RESERVED" 204 "RESERVED" 205 "RESERVED" 206 "RESERVED" 207 "RESERVED" 208 "RESERVED" 209 "RESERVED" 210 "RESERVED" 211 "RESERVED" 212 "RESERVED" 213 "RESERVED" 214 "RESERVED" 215 "RESERVED" 216 "RESERVED" 217 "RESERVED" 218 "RESERVED" 219 "RESERVED" 220 "RESERVED" 221 "RESERVED" 222 "RESERVED" 223 "RESERVED" 224 "RESERVED" 225 "RESERVED" 226 "RESERVED" 227 "RESERVED" 228 "RESERVED" 229 "RESERVED" 230 "RESERVED" 231 "RESERVED" 232 "RESERVED" 233 "RESERVED" 234 "RESERVED" 235 "RESERVED" 236 "RESERVED" 237 "RESERVED" 238 "RESERVED" 239 "RESERVED" 240 "RESERVED" 241 "RESERVED" 242 "RESERVED" 243 "RESERVED" 244 "RESERVED" 245 "RESERVED" 246 "RESERVED" 247 "RESERVED" 248 "RESERVED" 249 "RESERVED" 250 "RESERVED" 251 "RESERVED" 252 "RESERVED" 253 "RESERVED" 254 "RESERVED" 255 "ERROR" ;
VAL_ 273 L_ATCU_FHPTCDischrgReq 0 "Non-Request" 1 "Request" ;
VAL_ 273 L_ATCU_FltMsgTmOutFHPTC1 0 "Normal" 1 "Message Timeout" ;
VAL_ 273 L_ATCU_FltMsgTmOutFHPTC2 0 "Normal" 1 "Message Timeout" ;
VAL_ 273 L_ATCU_FltMsgTmOutFHPTC3 0 "Normal" 1 "Message Timeout" ;
VAL_ 273 L_ATCU_FltMsgTmOutFHPTC4 0 "Normal" 1 "Message Timeout" ;
VAL_ 273 L_ATCU_FrBlwLvl 0 "OFF" 1 "0 level" 2 "1 level" 3 "2 level" 4 "3 level" 5 "4 level" 6 "5 level" 7 "6 level" 8 "7 evel" 9 "8 level" 10 "RESERVED" 11 "RESERVED" 12 "RESERVED" 13 "RESERVED" 14 "RESERVED" 15 "Error Indicator" ;
VAL_ 273 L_ATCU_FrBlwLvlSigVaildSta 0 "Invaild (Blower Level Info Not supported)" 1 "Vaild (Blower Level Info Supported) (Initial Value:0H)" ;
VAL_ 273 L_ATCU_DrvrSdTyp 0 "LHD" 1 "RHD" ;
VAL_ 273 L_ATCU_FrBlwFltSta 0 "Normal" 1 "Blower Fault" ;
VAL_ 273 L_ATCU_PassBlwLvl 0 "OFF(Default)" 1 "0 Level" 2 "1 Level" 3 "2 Level" 4 "3 Level" 5 "4 Level" 6 "5 Level" 7 "6 Level" 8 "7 Level" 9 "8 Level" 10 "RESERVED" 11 "RESERVED" 12 "RESERVED" 13 "RESERVED" 14 "RESERVED" 15 "Error Indicator" ;
VAL_ 273 L_ATCU_FHPTCDrTrgtDty 0 "0x0x0~0xC8:Duty" 200 "0x0x0~0xC8:Duty" 201 "RESERVED" 202 "RESERVED" 203 "RESERVED" 204 "RESERVED" 205 "RESERVED" 206 "RESERVED" 207 "RESERVED" 208 "RESERVED" 209 "RESERVED" 210 "RESERVED" 211 "RESERVED" 212 "RESERVED" 213 "RESERVED" 214 "RESERVED" 215 "RESERVED" 216 "RESERVED" 217 "RESERVED" 218 "RESERVED" 219 "RESERVED" 220 "RESERVED" 221 "RESERVED" 222 "RESERVED" 223 "RESERVED" 224 "RESERVED" 225 "RESERVED" 226 "RESERVED" 227 "RESERVED" 228 "RESERVED" 229 "RESERVED" 230 "RESERVED" 231 "RESERVED" 232 "RESERVED" 233 "RESERVED" 234 "RESERVED" 235 "RESERVED" 236 "RESERVED" 237 "RESERVED" 238 "RESERVED" 239 "RESERVED" 240 "RESERVED" 241 "RESERVED" 242 "RESERVED" 243 "RESERVED" 244 "RESERVED" 245 "RESERVED" 246 "RESERVED" 247 "RESERVED" 248 "RESERVED" 249 "RESERVED" 250 "RESERVED" 251 "RESERVED" 252 "RESERVED" 253 "RESERVED" 254 "RESERVED" 255 "ERROR" ;
VAL_ 66 HKBD_Fr_DrModDnSw 0 "Off" 1 "On" ;
VAL_ 66 HKBD_Fr_DrModUpSw 0 "Off" 1 "On" ;
VAL_ 66 HKBD_Fr_DrMultiAutoSw 0 "RESERVED" 1 "Low" 2 "Medium" 3 "High" 4 "RESERVED" 5 "RESERVED" 6 "RESERVED" 7 "Invalid" ;
VAL_ 66 HKBD_Fr_PsAutoSw 0 "Off" 1 "On" ;
VAL_ 66 HKBD_Fr_PsMultiAutoSw 0 "RESERVED" 1 "Low" 2 "Medium" 3 "High" 4 "RESERVED" 5 "RESERVED" 6 "RESERVED" 7 "Invalid" ;
VAL_ 66 HKBD_Fr_AcSw 0 "Off" 1 "On" ;
VAL_ 66 HKBD_Fr_DefSw 0 "Off" 1 "On" ;
VAL_ 66 HKBD_Fr_RecSw 0 "Off" 1 "On" ;
VAL_ 66 HKBD_Fr_DrModVntSw 0 "Off" 1 "On" ;
VAL_ 66 HKBD_Fr_FreSw 0 "Off" 1 "On" ;
VAL_ 66 HKBD_Fr_IntakeTglSw 0 "Off" 1 "On" ;
VAL_ 66 HKBD_Fr_OffSw 0 "Off" 1 "On" ;
VAL_ 66 HKBD_Fr_SyncSw 0 "Off" 1 "On" ;
VAL_ 66 HKBD_Fr_RrDefInd 0 "Off" 1 "On" ;
VAL_ 66 HKBD_Fr_RrDefSw 0 "Off" 1 "On" ;
VAL_ 66 HKBD_Fr_ArclnSw 0 "Off" 1 "On" ;
VAL_ 66 HKBD_Fr_DrOnlySw 0 "Off" 1 "On" ;
VAL_ 66 HKBD_Fr_ClimateSw 0 "Off" 1 "On" ;
VAL_ 66 HKBD_Fr_PerfumeSw 0 "Off" 1 "On" ;
VAL_ 66 HKBD_Fr_DrModFlrSw 0 "Off" 1 "On" ;
VAL_ 66 HKBD_Fr_HptIntnstySta 0 "Default" 1 "Haptic OFF" 2 "Haptic Intensity Level 1" 3 "Haptic Intensity Level 2" 4 "Haptic Intensity Level 3" 5 "Haptic Intensity Level 4" 6 "Haptic Intensity Level 5" 7 "RESERVED" 8 "RESERVED" 9 "RESERVED" 10 "RESERVED" 11 "RESERVED" 12 "RESERVED" 13 "RESERVED" 14 "RESERVED" 15 "Invalid" ;
VAL_ 66 HKBD_Fr_StrWhlHeatSw 0 "Off" 1 "On" ;
VAL_ 66 HKBD_FLStHeatSw 0 "Off" 1 "On" ;
VAL_ 66 HKBD_FLStVentSw 0 "Off" 1 "On" ;
VAL_ 66 HKBD_FRStHeatSw 0 "Off" 1 "On" ;
VAL_ 66 HKBD_FRStVentSw 0 "Off" 1 "On" ;
VAL_ 66 HKBD_FLStTumblrSw 0 "Default" 1 "Up" 2 "Down" 3 "Error Indicator" ;
VAL_ 66 HKBD_Fr_DrModDefSw 0 "Off" 1 "On" ;
VAL_ 66 HKBD_FRStTumblrSw 0 "Default" 1 "Up" 2 "Down" 3 "Error Indicator" ;
VAL_ 66 HKBD_Fr_FrWndShldHtSw 0 "Off" 1 "On" ;
VAL_ 66 HKBD_Fr_DrAutoDnSw 0 "Off" 1 "On" ;
VAL_ 66 HKBD_Fr_DrAutoUpSw 0 "Off" 1 "On" ;
VAL_ 66 HKBD_Fr_DrModSw 0 "Off" 1 "On" ;
VAL_ 66 HKBD_Fr_PsModSw 0 "Off" 1 "On" ;
VAL_ 66 HKBD_DisplayTheme 0 "Default" 1 "White Theme" 2 "Black Theme" 3 "Invalid" ;
VAL_ 66 HKBD_Fr_PsModDnSw 0 "Off" 1 "On" ;
VAL_ 66 HKBD_Fr_SmartZoneSW 0 "Default(Off)" 1 "On" ;
VAL_ 66 HKBD_Fr_PsModUpSw 0 "Off" 1 "On" ;
VAL_ 66 HKBD_Fr_PsModVntSw 0 "Off" 1 "On" ;
VAL_ 66 HKBD_Fr_PsModFlrSw 0 "Off" 1 "On" ;
VAL_ 66 HKBD_Fr_DrAutoSw 0 "Off" 1 "On" ;
VAL_ 67 HKBD_Fr_DrTempClickCnt 0 "RESERVED" 1 "0x1~0x7F:clockwise" 127 "0x1~0x7F:clockwise" 128 "0x80~0xFE:Counterclockwise" 254 "0x80~0xFE:Counterclockwise" 255 "Invalid" ;
VAL_ 67 HKBD_Fr_RrTempClickCnt 0 "RESERVED" 1 "0x1~0x7F:clockwise" 127 "0x1~0x7F:clockwise" 128 "0x80~0xFE:Counterclockwise" 254 "0x80~0xFE:Counterclockwise" 255 "Invalid" ;
VAL_ 67 HKBD_Fr_DrBlwClickCnt 0 "RESERVED" 1 "0x1~0x7F:clockwise" 127 "0x1~0x7F:clockwise" 128 "0x80~0xFE:Counterclockwise" 254 "0x80~0xFE:Counterclockwise" 255 "Invalid" ;
VAL_ 67 HKBD_Fr_PsBlwClickCnt 0 "RESERVED" 1 "0x1~0x7F:clockwise" 127 "0x1~0x7F:clockwise" 128 "0x80~0xFE:Counterclockwise" 254 "0x80~0xFE:Counterclockwise" 255 "Invalid" ;
VAL_ 67 HKBD_FrTempKnobCnt 0 "0" 1 "1" 2 "2" 3 "invalid" ;
VAL_ 67 HKBD_FrBlwKnobCnt 0 "0" 1 "1" 2 "2" 3 "invalid" ;
VAL_ 67 HKBD_Fr_PsTempClickCnt 0 "RESERVED" 1 "0x1~0x7F:clockwise" 127 "0x1~0x7F:clockwise" 128 "0x80~0xFE:Counterclockwise" 254 "0x80~0xFE:Counterclockwise" 255 "Invalid" ;
VAL_ 68 HKBD_Fr_DrTempDnSw 0 "Off" 1 "On" ;
VAL_ 68 HKBD_Fr_DrTempUpSw 0 "Off" 1 "On" ;
VAL_ 68 HKBD_Fr_PsBlwDnSw 0 "Off" 1 "On" ;
VAL_ 68 HKBD_Fr_PsBlwDnOffSw 0 "Off" 1 "On" ;
VAL_ 68 HKBD_Fr_PsBlwUpSw 0 "Off" 1 "On" ;
VAL_ 68 HKBD_Fr_PsBlwSet 0 "Off" 1 "0 Level" 2 "1 Level" 3 "2 Level" 4 "3 Level" 5 "4 Level" 6 "5 Level" 7 "6 Level" 8 "7 Level" 9 "8 Level" 15 "Invalid" ;
VAL_ 68 HKBD_Fr_RrDrTempDnSw 0 "Off" 1 "On" ;
VAL_ 68 HKBD_Fr_RrDrTempUpSw 0 "Off" 1 "On" ;
VAL_ 68 HKBD_Fr_PsTempDnSw 0 "Off" 1 "On" ;
VAL_ 68 HKBD_Fr_RrDrBlwDnSw 0 "Off" 1 "On" ;
VAL_ 68 HKBD_Fr_RrDrBlwDnOffSw 0 "Off" 1 "On" ;
VAL_ 68 HKBD_Fr_RrDrBlwUpSw 0 "Off" 1 "On" ;
VAL_ 68 HKBD_Fr_RrDrBlwSet 0 "Off" 1 "0 Level" 2 "1 Level" 3 "2 Level" 4 "3 Level" 5 "4 Level" 6 "5 Level" 7 "6 Level" 8 "7 Level" 9 "8 Level" 15 "Invalid" ;
VAL_ 68 HKBD_Fr_RrDrModDnSw 0 "Off" 1 "On" ;
VAL_ 68 HKBD_Fr_RrDrModUpSw 0 "Off" 1 "On" ;
VAL_ 68 HKBD_Fr_RrDrModVntSw 0 "Off" 1 "On" ;
VAL_ 68 HKBD_Fr_PsTempUpSw 0 "Off" 1 "On" ;
VAL_ 68 HKBD_Fr_RrDrModFlrSw 0 "Off" 1 "On" ;
VAL_ 68 HKBD_Fr_RrDrModBiLvlSw 0 "Off" 1 "On" ;
VAL_ 68 HKBD_Fr_RrDrAutoSw 0 "Off" 1 "On" ;
VAL_ 68 HKBD_Fr_RrDrMultiAutoSw 0 "RESERVED" 1 "Low" 2 "Medium" 3 "High" 4 "RESERVED" 5 "RESERVED" 6 "RESERVED" 7 "Invalid" ;
VAL_ 68 HKBD_Fr_RrOffSw 0 "Off" 1 "On" ;
VAL_ 68 HKBD_Fr_RrSyncSw 0 "Off" 1 "On" ;
VAL_ 68 HKBD_Fr_RLStHeatSw 0 "Off" 1 "On" ;
VAL_ 68 HKBD_Fr_RLStVentSw 0 "Off" 1 "On" ;
VAL_ 68 HKBD_Fr_DrBlwDnSw 0 "Off" 1 "On" ;
VAL_ 68 HKBD_Fr_RRStHeatSw 0 "Off" 1 "On" ;
VAL_ 68 HKBD_Fr_RRStVentSw 0 "Off" 1 "On" ;
VAL_ 68 HKBD_Fr_RLStTumblrSw 0 "Default" 1 "Up" 2 "Down" 3 "Error Indicator" ;
VAL_ 68 HKBD_Fr_RRStTumblrSw 0 "Default" 1 "Up" 2 "Down" 3 "Error Indicator" ;
VAL_ 68 HKBD_Fr_RrPsModDnSw 0 "Off" 1 "On" ;
VAL_ 68 HKBD_Fr_RrPsModUpSw 0 "Off" 1 "On" ;
VAL_ 68 HKBD_Fr_RrPsModVntSw 0 "Off" 1 "On" ;
VAL_ 68 HKBD_Fr_RrPsModFlrSw 0 "Off" 1 "On" ;
VAL_ 68 HKBD_Fr_DrBlwDnOffSw 0 "Off" 1 "On" ;
VAL_ 68 HKBD_Fr_RrLockSw 0 "Off" 1 "On" ;
VAL_ 68 HKBD_Fr_RrPsModBiLvlSw 0 "Off" 1 "On" ;
VAL_ 68 HKBD_Fr_RrDrModSw 0 "Off" 1 "On" ;
VAL_ 68 HKBD_Fr_RrPsModSw 0 "Off" 1 "On" ;
VAL_ 68 HKBD_Fr_RrPsBlwSet 0 "Off" 1 "0 Level" 2 "1 Level" 3 "2 Level" 4 "3 Level" 5 "4 Level" 6 "5 Level" 7 "6 Level" 8 "7 Level" 9 "8 Level" 15 "Invalid" ;
VAL_ 68 HKBD_Fr_RrPsBlwUpSw 0 "Off" 1 "On" ;
VAL_ 68 HKBD_Fr_RrPsBlwDnSw 0 "Off" 1 "On" ;
VAL_ 68 HKBD_Fr_DrBlwUpSw 0 "Off" 1 "On" ;
VAL_ 68 HKBD_Fr_RrPsBlwDnOffSw 0 "Off" 1 "On" ;
VAL_ 68 HKBD_Fr_RrPsTempDnSw 0 "Off" 1 "On" ;
VAL_ 68 HKBD_Fr_RrPsTempUpSw 0 "Off" 1 "On" ;
VAL_ 68 HKBD_Fr_DrBlwSet 0 "Off" 1 "0 Level" 2 "1 Level" 3 "2 Level" 4 "3 Level" 5 "4 Level" 6 "5 Level" 7 "6 Level" 8 "7 Level" 9 "8 Level" 15 "Invalid" ;
VAL_ 69 HKBD_Fr_3rdRrTempDnSw 0 "Off" 1 "On" ;
VAL_ 69 HKBD_Fr_3rdRrTempUpSw 0 "Off" 1 "On" ;
VAL_ 69 HKBD_Fr_3rdRrModUpSw 0 "Off" 1 "On" ;
VAL_ 69 HKBD_Fr_3rdRrModVntSw 0 "Off" 1 "On" ;
VAL_ 69 HKBD_Fr_3rdRrModFlrSw 0 "Off" 1 "On" ;
VAL_ 69 HKBD_Fr_3rdRrAutoSw 0 "Off" 1 "On" ;
VAL_ 69 HKBD_Fr_3rdRrMultiAutoSw 0 "RESERVED" 1 "Low" 2 "Medium" 3 "High" 4 "RESERVED" 5 "RESERVED" 6 "RESERVED" 7 "Invalid" ;
VAL_ 69 HKBD_Fr_3rdRrOffSw 0 "Off" 1 "On" ;
VAL_ 69 HKBD_Fr_3rdRrSyncSw 0 "Off" 1 "On" ;
VAL_ 69 HKBD_Fr_3rdRrLockSw 0 "Off" 1 "On" ;
VAL_ 69 HKBD_Fr_3rdRrBlwDnSw 0 "Off" 1 "On" ;
VAL_ 69 HKBD_Fr_3rdRrModBiLvlSw 0 "Off" 1 "On" ;
VAL_ 69 HKBD_FrRrTglSet 0 "Default" 1 "On" 2 "Off" 3 "Invalid" ;
VAL_ 69 HKBD_Fr_RrScrnSet 0 "Default" 1 "On" 2 "Off" 3 "Invalid" ;
VAL_ 69 HKBD_Fr_OnOffSet 0 "Default" 1 "On" 2 "Off" 3 "Invalid" ;
VAL_ 69 HKBD_Fr_RrOnOffSet 0 "Default" 1 "On" 2 "Off" 3 "Invalid" ;
VAL_ 69 HKBD_Fr_3rdRrOnOffSet 0 "Default" 1 "On" 2 "Off" 3 "Invalid" ;
VAL_ 69 HKBD_Fr_3rdRrBlwDnOffSw 0 "Off" 1 "On" ;
VAL_ 69 HKBD_Fr_RrPsAutoSw 0 "Off" 1 "On" ;
VAL_ 69 HKBD_Fr_RrPsMultiAutoSw 0 "RESERVED" 1 "Low" 2 "Medium" 3 "High" 4 "RESERVED" 5 "RESERVED" 6 "RESERVED" 7 "Invalid" ;
VAL_ 69 HKBD_Fr_3rdRrModSw 0 "Off" 1 "On" ;
VAL_ 69 HKBD_Fr_3rdRrBlwUpSw 0 "Off" 1 "On" ;
VAL_ 69 HKBD_Fr_3rdRrBlwSet 0 "Off" 1 "0 Level" 2 "1 Level" 3 "2 Level" 4 "3 Level" 5 "4 Level" 6 "5 Level" 7 "6 Level" 8 "7 Level" 9 "8 Level" 15 "Invalid" ;
VAL_ 69 HKBD_Fr_3rdRrModDnSw 0 "Off" 1 "On" ;
VAL_ 70 L_HKBD_ResetOpSta 0 "Normal" 1 "Reser Complete" 2 "Reset Fail" 3 "RESERVED" ;
VAL_ 71 HKBD_Fr_RrDrTempClickCnt 0 "RESERVED" 1 "0x1~0x7F:clockwise" 127 "0x1~0x7F:clockwise" 128 "0x80~0xFE:Counterclockwise" 254 "0x80~0xFE:Counterclockwise" 255 "Invalid" ;
VAL_ 71 HKBD_Fr_RrPsTempClickCnt 0 "RESERVED" 1 "0x1~0x7F:clockwise" 127 "0x1~0x7F:clockwise" 128 "0x80~0xFE:Counterclockwise" 254 "0x80~0xFE:Counterclockwise" 255 "Invalid" ;
VAL_ 71 HKBD_Fr_RrPsBlwClickCnt 0 "RESERVED" 1 "0x1~0x7F:clockwise" 127 "0x1~0x7F:clockwise" 128 "0x80~0xFE:Counterclockwise" 254 "0x80~0xFE:Counterclockwise" 255 "Invalid" ;
VAL_ 71 HKBD_Fr_3rdRrTempClickCnt 0 "RESERVED" 1 "0x1~0x7F:clockwise" 127 "0x1~0x7F:clockwise" 128 "0x80~0xFE:Counterclockwise" 254 "0x80~0xFE:Counterclockwise" 255 "Invalid" ;
VAL_ 71 HKBD_Fr_3rdRrBlwClickCnt 0 "RESERVED" 1 "0x1~0x7F:clockwise" 127 "0x1~0x7F:clockwise" 128 "0x80~0xFE:Counterclockwise" 254 "0x80~0xFE:Counterclockwise" 255 "Invalid" ;
VAL_ 71 HKBD_Fr_RrTempKnobCnt 0 "0" 1 "1" 2 "2" 3 "invalid" ;
VAL_ 71 HKBD_Fr_RrBlwKnobCnt 0 "0" 1 "1" 2 "2" 3 "invalid" ;
VAL_ 71 HKBD_Fr_3rdTempKnobCnt 0 "0" 1 "1" 2 "2" 3 "invalid" ;
VAL_ 71 HKBD_Fr_3rdBlwKnobCnt 0 "0" 1 "1" 2 "2" 3 "invalid" ;
VAL_ 71 HKBD_Fr_RrDrBlwClickCnt 0 "RESERVED" 1 "0x1~0x7F:clockwise" 127 "0x1~0x7F:clockwise" 128 "0x80~0xFE:Counterclockwise" 254 "0x80~0xFE:Counterclockwise" 255 "Invalid" ;
VAL_ 72 HKBD_Fr_IncarRaw 1023 "Error Indicator" ;
